VERSION "canboat-NMEA2000-curated"

NS_ :

BS_:

BU_: Vector__XXX
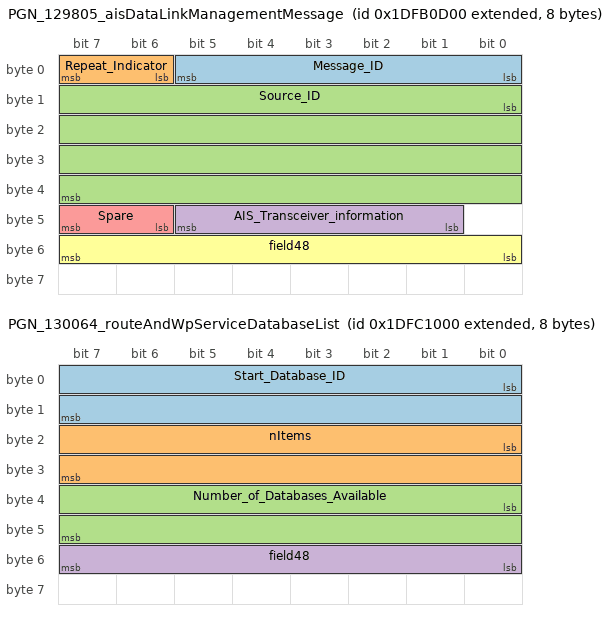
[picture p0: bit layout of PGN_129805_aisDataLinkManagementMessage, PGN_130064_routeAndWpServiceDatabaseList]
BO_ 2650475776 PGN_129805_aisDataLinkManagementMessage: 8 Vector__XXX
 SG_ Message_ID : 0|6@1+ (1.0,0) [0|63] "" Vector__XXX
 SG_ Repeat_Indicator : 6|2@1+ (1.0,0) [0|3] "" Vector__XXX
 SG_ Source_ID : 8|32@1+ (1.0,0) [2000000.0|999999999.0] "" Vector__XXX
 SG_ AIS_Transceiver_information : 41|5@1+ (1.0,0) [0|31] "" Vector__XXX
 SG_ Spare : 46|2@1+ (1.0,0) [0|3] "" Vector__XXX
 SG_ field48 : 48|8@1+ (1.0,0) [0|255] "" Vector__XXX

BO_ 2650476032 PGN_129806_aisChannelManagement: 31 Vector__XXX
 SG_ Message_ID : 0|6@1+ (1.0,0) [0|63] "" Vector__XXX
 SG_ Repeat_Indicator : 6|2@1+ (1.0,0) [0|3] "" Vector__XXX
 SG_ Source_ID : 8|32@1+ (1.0,0) [2000000.0|999999999.0] "" Vector__XXX
 SG_ AIS_Transceiver_information : 41|5@1+ (1.0,0) [0|31] "" Vector__XXX
 SG_ Spare : 46|2@1+ (1.0,0) [0|3] "" Vector__XXX
 SG_ Channel_A : 48|16@1+ (1.0,0) [0|65535] "" Vector__XXX
 SG_ Channel_B : 64|16@1+ (1.0,0) [0|65535] "" Vector__XXX
 SG_ Power : 83|1@1+ (1.0,0) [0|1] "" Vector__XXX
 SG_ Tx_Rx_Mode : 84|4@1+ (1.0,0) [0|15] "" Vector__XXX
 SG_ North_East_Longitude_Corner_1 : 88|32@1- (1e-07,0) [-180.0|180.0] "" Vector__XXX
 SG_ North_East_Latitude_Corner_1 : 120|32@1- (1e-07,0) [-90.0|90.0] "" Vector__XXX
 SG_ South_West_Longitude_Corner_2 : 152|32@1- (1e-07,0) [-180.0|180.0] "" Vector__XXX
 SG_ South_West_Latitude_Corner_2 : 184|32@1- (1e-07,0) [-90.0|90.0] "" Vector__XXX
 SG_ Addressed_or_Broadcast_Message_Indicator : 217|1@1+ (1.0,0) [0|1] "" Vector__XXX
 SG_ Channel_A_Bandwidth : 218|1@1+ (1.0,0) [0|1] "" Vector__XXX
 SG_ Channel_B_Bandwidth : 219|1@1+ (1.0,0) [0|1] "" Vector__XXX
 SG_ Transitional_Zone_Size : 221|3@1+ (1.0,0) [0|7] "" Vector__XXX
 SG_ Spare_1 : 224|23@1+ (1.0,0) [0|8388607] "" Vector__XXX

BO_ 2650476288 PGN_129807_aisClassBGroupAssignment: 29 Vector__XXX
 SG_ Message_ID : 0|6@1+ (1.0,0) [0|63] "" Vector__XXX
 SG_ Repeat_Indicator : 6|2@1+ (1.0,0) [0|3] "" Vector__XXX
 SG_ Source_ID : 8|32@1+ (1.0,0) [2000000.0|999999999.0] "" Vector__XXX
 SG_ Spare : 40|2@1+ (1.0,0) [0|3] "" Vector__XXX
 SG_ Tx_Rx_Mode : 42|4@1+ (1.0,0) [0|15] "" Vector__XXX
 SG_ North_East_Longitude_Corner_1 : 48|32@1- (1e-07,0) [-180.0|180.0] "" Vector__XXX
 SG_ North_East_Latitude_Corner_1 : 80|32@1- (1e-07,0) [-90.0|90.0] "" Vector__XXX
 SG_ South_West_Longitude_Corner_2 : 112|32@1- (1e-07,0) [-180.0|180.0] "" Vector__XXX
 SG_ South_West_Latitude_Corner_2 : 144|32@1- (1e-07,0) [-90.0|90.0] "" Vector__XXX
 SG_ Station_Type : 176|4@1+ (1.0,0) [0|15] "" Vector__XXX
 SG_ Ship_and_Cargo_Filter : 184|8@1+ (1.0,0) [0|255] "" Vector__XXX
 SG_ Spare_1 : 192|22@1+ (1.0,0) [0|4194303] "" Vector__XXX
 SG_ Reporting_Interval : 216|4@1+ (1.0,0) [0|15] "" Vector__XXX
 SG_ Quiet_Time : 220|4@1+ (60.0,0) [0.0|900.0] "" Vector__XXX
 SG_ Spare_2 : 224|6@1+ (1.0,0) [0|63] "" Vector__XXX

BO_ 2449149952 PGN_129808_dscCallInformation: 62 Vector__XXX
 SG_ DSC_Format_Symbol : 0|8@1+ (1.0,0) [0|255] "" Vector__XXX
 SG_ DSC_Category_Symbol : 8|8@1+ (1.0,0) [0|255] "" Vector__XXX
 SG_ DSC_Message_Address : 16|40@1+ (1.0,0) [0.0|9999999999.0] "" Vector__XXX
 SG_ _1st_Telecommand : 56|8@1+ (1.0,0) [0|255] "" Vector__XXX
 SG_ Subsequent_Communication_Mode_or_2nd_Telecommand : 64|8@1+ (1.0,0) [0|255] "" Vector__XXX
 SG_ Proposed_Rx_Frequency_Channel : 72|48@1+ (1.0,0) [0|281474976710655] "" Vector__XXX
 SG_ Proposed_Tx_Frequency_Channel : 120|48@1+ (1.0,0) [0|281474976710655] "" Vector__XXX
 SG_ Telephone_Number : 168|8@1+ (1.0,0) [0|255] "" Vector__XXX
 SG_ Latitude_of_Vessel_Reported : 176|32@1- (1e-07,0) [-90.0|90.0] "" Vector__XXX
 SG_ Longitude_of_Vessel_Reported : 208|32@1- (1e-07,0) [-180.0|180.0] "" Vector__XXX
 SG_ Time_of_Position : 240|32@1+ (0.0001,0) [0.0|86401.0] "" Vector__XXX
 SG_ MMSI_of_Ship_In_Distress : 272|40@1+ (1.0,0) [0.0|9999999999.0] "" Vector__XXX
 SG_ DSC_EOS_Symbol : 312|8@1+ (1.0,0) [0|255] "" Vector__XXX
 SG_ Expansion_Enabled : 320|2@1+ (1.0,0) [0|3] "" Vector__XXX
 SG_ Calling_Rx_Frequency_Channel : 328|48@1+ (1.0,0) [0|281474976710655] "" Vector__XXX
 SG_ Calling_Tx_Frequency_Channel : 376|48@1+ (1.0,0) [0|281474976710655] "" Vector__XXX
 SG_ Time_of_Receipt : 424|32@1+ (0.0001,0) [0.0|86401.0] "" Vector__XXX
 SG_ Date_of_Receipt : 456|16@1+ (1.0,0) [0|65535] "" Vector__XXX
 SG_ DSC_Equipment_Assigned_Message_ID : 472|16@1+ (1.0,0) [0|65535] "" Vector__XXX
 SG_ field488 : 488|8@1+ (1.0,0) [0|255] "" Vector__XXX

BO_ 2449149952 PGN_129808_dscDistressCallInformation: 62 Vector__XXX
 SG_ DSC_Format : 0|8@1+ (1.0,0) [0|255] "" Vector__XXX
 SG_ DSC_Category : 8|8@1+ (1.0,0) [0|255] "" Vector__XXX
 SG_ DSC_Message_Address : 16|40@1+ (1.0,0) [0.0|9999999999.0] "" Vector__XXX
 SG_ Nature_of_Distress : 56|8@1+ (1.0,0) [0|255] "" Vector__XXX
 SG_ Subsequent_Communication_Mode_or_2nd_Telecommand : 64|8@1+ (1.0,0) [0|255] "" Vector__XXX
 SG_ Proposed_Rx_Frequency_Channel : 72|48@1+ (1.0,0) [0|281474976710655] "" Vector__XXX
 SG_ Proposed_Tx_Frequency_Channel : 120|48@1+ (1.0,0) [0|281474976710655] "" Vector__XXX
 SG_ Telephone_Number : 168|8@1+ (1.0,0) [0|255] "" Vector__XXX
 SG_ Latitude_of_Vessel_Reported : 176|32@1- (1e-07,0) [-90.0|90.0] "" Vector__XXX
 SG_ Longitude_of_Vessel_Reported : 208|32@1- (1e-07,0) [-180.0|180.0] "" Vector__XXX
 SG_ Time_of_Position : 240|32@1+ (0.0001,0) [0.0|86401.0] "" Vector__XXX
 SG_ MMSI_of_Ship_In_Distress : 272|40@1+ (1.0,0) [0.0|9999999999.0] "" Vector__XXX
 SG_ DSC_EOS_Symbol : 312|8@1+ (1.0,0) [0|255] "" Vector__XXX
 SG_ Expansion_Enabled : 320|2@1+ (1.0,0) [0|3] "" Vector__XXX
 SG_ Calling_Rx_Frequency_Channel : 328|48@1+ (1.0,0) [0|281474976710655] "" Vector__XXX
 SG_ Calling_Tx_Frequency_Channel : 376|48@1+ (1.0,0) [0|281474976710655] "" Vector__XXX
 SG_ Time_of_Receipt : 424|32@1+ (0.0001,0) [0.0|86401.0] "" Vector__XXX
 SG_ Date_of_Receipt : 456|16@1+ (1.0,0) [0|65535] "" Vector__XXX
 SG_ DSC_Equipment_Assigned_Message_ID : 472|16@1+ (1.0,0) [0|65535] "" Vector__XXX
 SG_ field488 : 488|8@1+ (1.0,0) [0|255] "" Vector__XXX

BO_ 2583367936 PGN_129809_aisClassBStaticDataMsg24PartA: 27 Vector__XXX
 SG_ Message_ID : 0|6@1+ (1.0,0) [0|63] "" Vector__XXX
 SG_ Repeat_Indicator : 6|2@1+ (1.0,0) [0|3] "" Vector__XXX
 SG_ User_ID : 8|32@1+ (1.0,0) [2000000.0|999999999.0] "" Vector__XXX
 SG_ Name : 40|160@1+ (1.0,0) [0|1461501637330902918203684832716283019655932542975] "" Vector__XXX
 SG_ AIS_Transceiver_information : 200|5@1+ (1.0,0) [0|31] "" Vector__XXX
 SG_ Sequence_ID : 208|8@1+ (1.0,0) [0|255] "" Vector__XXX

BO_ 2583368192 PGN_129810_aisClassBStaticDataMsg24PartB: 35 Vector__XXX
 SG_ Message_ID : 0|6@1+ (1.0,0) [0|63] "" Vector__XXX
 SG_ Repeat_Indicator : 6|2@1+ (1.0,0) [0|3] "" Vector__XXX
 SG_ User_ID : 8|32@1+ (1.0,0) [2000000.0|999999999.0] "" Vector__XXX
 SG_ Type_of_ship : 40|8@1+ (1.0,0) [0|255] "" Vector__XXX
 SG_ Vendor_ID : 48|56@1+ (1.0,0) [0|72057594037927935] "" Vector__XXX
 SG_ Callsign : 104|56@1+ (1.0,0) [0|72057594037927935] "" Vector__XXX
 SG_ Length : 160|16@1+ (0.1,0) [0.0|6553.5] "" Vector__XXX
 SG_ Beam : 176|16@1+ (0.1,0) [0.0|6553.5] "" Vector__XXX
 SG_ Position_reference_from_Starboard : 192|16@1+ (0.1,0) [0.0|6553.5] "" Vector__XXX
 SG_ Position_reference_from_Bow : 208|16@1+ (0.1,0) [0.0|6553.5] "" Vector__XXX
 SG_ Mothership_User_ID : 224|32@1+ (1.0,0) [2000000.0|999999999.0] "" Vector__XXX
 SG_ Spare : 258|2@1+ (1.0,0) [0|3] "" Vector__XXX
 SG_ GNSS_type : 260|4@1+ (1.0,0) [0|15] "" Vector__XXX
 SG_ AIS_Transceiver_information : 264|5@1+ (1.0,0) [0|31] "" Vector__XXX
 SG_ Sequence_ID : 272|8@1+ (1.0,0) [0|255] "" Vector__XXX

BO_ 2583368448 PGN_129811_aisSingleSlotBinaryMessageDeprecated: 14 Vector__XXX
 SG_ Sequence_ID : 0|8@1+ (1.0,0) [0|255] "" Vector__XXX
 SG_ Message_ID : 8|6@1+ (1.0,0) [0|63] "" Vector__XXX
 SG_ Repeat_Indicator : 14|2@1+ (1.0,0) [0|3] "" Vector__XXX
 SG_ Source_ID : 16|32@1+ (1.0,0) [2000000.0|999999999.0] "" Vector__XXX
 SG_ Destination_Indicator : 48|1@1+ (1.0,0) [0|1] "" Vector__XXX
 SG_ Binary_data_flag : 49|1@1+ (1.0,0) [0|1] "" Vector__XXX
 SG_ Spare : 50|1@1+ (1.0,0) [0|1] "" Vector__XXX
 SG_ AIS_Transceiver_information : 51|5@1+ (1.0,0) [0|31] "" Vector__XXX
 SG_ Destination_ID : 56|32@1+ (1.0,0) [2000000.0|999999999.0] "" Vector__XXX
 SG_ Number_of_bits_in_Binary_Data_Field : 88|16@1+ (1.0,0) [0|65535] "" Vector__XXX
 SG_ Binary_Data : 104|8@1+ (1.0,0) [0|255] "" Vector__XXX

BO_ 2583368704 PGN_129812_aisMultiSlotBinaryMessageDeprecated: 16 Vector__XXX
 SG_ Sequence_ID : 0|8@1+ (1.0,0) [0|255] "" Vector__XXX
 SG_ Message_ID : 8|6@1+ (1.0,0) [0|63] "" Vector__XXX
 SG_ Repeat_Indicator : 14|2@1+ (1.0,0) [0|3] "" Vector__XXX
 SG_ Source_ID : 16|32@1+ (1.0,0) [2000000.0|999999999.0] "" Vector__XXX
 SG_ Destination_Indicator : 48|1@1+ (1.0,0) [0|1] "" Vector__XXX
 SG_ Binary_data_flag : 49|1@1+ (1.0,0) [0|1] "" Vector__XXX
 SG_ AIS_Transceiver_information : 52|5@1+ (1.0,0) [0|31] "" Vector__XXX
 SG_ Destination_ID : 57|32@1+ (1.0,0) [2000000.0|999999999.0] "" Vector__XXX
 SG_ Spare : 89|3@1+ (1.0,0) [0|7] "" Vector__XXX
 SG_ Communication_state_selector_flag : 92|1@1+ (1.0,0) [0|1] "" Vector__XXX
 SG_ Communication_State : 93|19@1+ (1.0,0) [0|524287] "" Vector__XXX
 SG_ Spare_1 : 112|3@1+ (1.0,0) [0|7] "" Vector__XXX
 SG_ field120 : 120|8@1+ (1.0,0) [0|255] "" Vector__XXX

BO_ 2583368960 PGN_129813_aisLongRangeBroadcastMessage: 20 Vector__XXX
 SG_ Sequence_ID : 0|8@1+ (1.0,0) [0|255] "" Vector__XXX
 SG_ Message_ID : 8|6@1+ (1.0,0) [0|63] "" Vector__XXX
 SG_ Repeat_Indicator : 14|2@1+ (1.0,0) [0|3] "" Vector__XXX
 SG_ User_ID : 16|32@1+ (1.0,0) [2000000.0|999999999.0] "" Vector__XXX
 SG_ Longitude : 48|32@1- (1e-07,0) [-180.0|180.0] "" Vector__XXX
 SG_ Latitude : 80|32@1- (1e-07,0) [-90.0|90.0] "" Vector__XXX
 SG_ Position_Accuracy : 112|1@1+ (1.0,0) [0|1] "" Vector__XXX
 SG_ RAIM : 113|1@1+ (1.0,0) [0|1] "" Vector__XXX
 SG_ Nav_Status : 114|4@1+ (1.0,0) [0|15] "" Vector__XXX
 SG_ Position_Latency : 118|1@1+ (1.0,0) [0|1] "" Vector__XXX
 SG_ Spare : 119|1@1+ (1.0,0) [0|1] "" Vector__XXX
 SG_ SOG : 120|16@1+ (0.01,0) [0.0|655.35] "" Vector__XXX
 SG_ COG : 136|16@1+ (0.0001,0) [0.0|6.5535000000000005] "" Vector__XXX
 SG_ AIS_Transceiver_information : 152|5@1+ (1.0,0) [0|31] "" Vector__XXX

BO_ 2583369216 PGN_129814_aisSingleSlotBinaryMessage: 15 Vector__XXX
 SG_ Sequence_ID : 0|8@1+ (1.0,0) [0|255] "" Vector__XXX
 SG_ Message_ID : 8|6@1+ (1.0,0) [0|63] "" Vector__XXX
 SG_ Repeat_Indicator : 14|2@1+ (1.0,0) [0|3] "" Vector__XXX
 SG_ Source_ID : 16|32@1+ (1.0,0) [2000000.0|999999999.0] "" Vector__XXX
 SG_ Destination_Indicator : 48|1@1+ (1.0,0) [0|1] "" Vector__XXX
 SG_ Binary_data_flag : 49|1@1+ (1.0,0) [0|1] "" Vector__XXX
 SG_ Spare : 50|1@1+ (1.0,0) [0|1] "" Vector__XXX
 SG_ AIS_Transceiver_information : 59|5@1+ (1.0,0) [0|31] "" Vector__XXX
 SG_ Destination_ID : 64|32@1+ (1.0,0) [2000000.0|999999999.0] "" Vector__XXX
 SG_ Number_of_bits_in_Binary_Data_Field : 96|16@1+ (1.0,0) [0|65535] "" Vector__XXX
 SG_ Binary_Data : 112|8@1+ (1.0,0) [0|255] "" Vector__XXX

BO_ 2583369472 PGN_129815_aisMultiSlotBinaryMessage: 18 Vector__XXX
 SG_ Sequence_ID : 0|8@1+ (1.0,0) [0|255] "" Vector__XXX
 SG_ Message_ID : 8|6@1+ (1.0,0) [0|63] "" Vector__XXX
 SG_ Repeat_Indicator : 14|2@1+ (1.0,0) [0|3] "" Vector__XXX
 SG_ Source_ID : 16|32@1+ (1.0,0) [2000000.0|999999999.0] "" Vector__XXX
 SG_ Destination_Indicator : 48|1@1+ (1.0,0) [0|1] "" Vector__XXX
 SG_ Binary_data_flag : 49|1@1+ (1.0,0) [0|1] "" Vector__XXX
 SG_ Destination_ID : 52|32@1+ (1.0,0) [2000000.0|999999999.0] "" Vector__XXX
 SG_ Spare : 84|3@1+ (1.0,0) [0|7] "" Vector__XXX
 SG_ Communication_state_selector_flag : 87|1@1+ (1.0,0) [0|1] "" Vector__XXX
 SG_ Communication_State : 88|19@1+ (1.0,0) [0|524287] "" Vector__XXX
 SG_ Spare_1 : 107|3@1+ (1.0,0) [0|7] "" Vector__XXX
 SG_ AIS_Transceiver_information : 110|5@1+ (1.0,0) [0|31] "" Vector__XXX
 SG_ Number_of_Bits_in_Binary_Data_Field : 120|16@1+ (1.0,0) [0|65535] "" Vector__XXX
 SG_ Binary_Data : 136|8@1+ (1.0,0) [0|255] "" Vector__XXX

BO_ 2583369728 PGN_129816_aisAcknowledgeBinary: 9 Vector__XXX
 SG_ Sequence_ID : 0|8@1+ (1.0,0) [0|255] "" Vector__XXX
 SG_ Message_ID : 8|6@1+ (1.0,0) [0|63] "" Vector__XXX
 SG_ Repeat_Indicator : 14|2@1+ (1.0,0) [0|3] "" Vector__XXX
 SG_ Source_ID : 16|32@1+ (1.0,0) [2000000.0|999999999.0] "" Vector__XXX
 SG_ AIS_Transceiver_information : 50|5@1+ (1.0,0) [0|31] "" Vector__XXX
 SG_ Spare : 55|1@1+ (1.0,0) [0|1] "" Vector__XXX
 SG_ Number_of_Acknowledgments : 56|8@1+ (1.0,0) [0|255] "" Vector__XXX
 SG_ field64 : 64|8@1+ (1.0,0) [0|255] "" Vector__XXX

BO_ 2382103552 PGN_130052_loranCTdData: 32 Vector__XXX
 SG_ Group_Repetition_Interval__GRI_ : 0|32@1- (1e-09,0) [-2.147483648|2.147483647] "" Vector__XXX
 SG_ Master_Range : 32|32@1- (1e-09,0) [-2.147483648|2.147483647] "" Vector__XXX
 SG_ V_Secondary_TD : 64|32@1- (1e-09,0) [-2.147483648|2.147483647] "" Vector__XXX
 SG_ W_Secondary_TD : 96|32@1- (1e-09,0) [-2.147483648|2.147483647] "" Vector__XXX
 SG_ X_Secondary_TD : 128|32@1- (1e-09,0) [-2.147483648|2.147483647] "" Vector__XXX
 SG_ Y_Secondary_TD : 160|32@1- (1e-09,0) [-2.147483648|2.147483647] "" Vector__XXX
 SG_ Z_Secondary_TD : 192|32@1- (1e-09,0) [-2.147483648|2.147483647] "" Vector__XXX
 SG_ Station_status__Master : 224|4@1+ (1.0,0) [0|15] "" Vector__XXX
 SG_ Station_status__V : 228|4@1+ (1.0,0) [0|15] "" Vector__XXX
 SG_ Station_status__W : 232|4@1+ (1.0,0) [0|15] "" Vector__XXX
 SG_ Station_status__X : 236|4@1+ (1.0,0) [0|15] "" Vector__XXX
 SG_ Station_status__Y : 240|4@1+ (1.0,0) [0|15] "" Vector__XXX
 SG_ Station_status__Z : 244|4@1+ (1.0,0) [0|15] "" Vector__XXX
 SG_ Mode : 248|4@1+ (1.0,0) [0|15] "" Vector__XXX

BO_ 2382103808 PGN_130053_loranCRangeData: 32 Vector__XXX
 SG_ Group_Repetition_Interval__GRI_ : 0|32@1- (1e-09,0) [-2.147483648|2.147483647] "" Vector__XXX
 SG_ Master_Range : 32|32@1- (1e-09,0) [-2.147483648|2.147483647] "" Vector__XXX
 SG_ V_Secondary_Range : 64|32@1- (1e-09,0) [-2.147483648|2.147483647] "" Vector__XXX
 SG_ W_Secondary_Range : 96|32@1- (1e-09,0) [-2.147483648|2.147483647] "" Vector__XXX
 SG_ X_Secondary_Range : 128|32@1- (1e-09,0) [-2.147483648|2.147483647] "" Vector__XXX
 SG_ Y_Secondary_Range : 160|32@1- (1e-09,0) [-2.147483648|2.147483647] "" Vector__XXX
 SG_ Z_Secondary_Range : 192|32@1- (1e-09,0) [-2.147483648|2.147483647] "" Vector__XXX
 SG_ Station_status__Master : 224|4@1+ (1.0,0) [0|15] "" Vector__XXX
 SG_ Station_status__V : 228|4@1+ (1.0,0) [0|15] "" Vector__XXX
 SG_ Station_status__W : 232|4@1+ (1.0,0) [0|15] "" Vector__XXX
 SG_ Station_status__X : 236|4@1+ (1.0,0) [0|15] "" Vector__XXX
 SG_ Station_status__Y : 240|4@1+ (1.0,0) [0|15] "" Vector__XXX
 SG_ Station_status__Z : 244|4@1+ (1.0,0) [0|15] "" Vector__XXX
 SG_ Mode : 248|4@1+ (1.0,0) [0|15] "" Vector__XXX

BO_ 2382104064 PGN_130054_loranCSignalData: 15 Vector__XXX
 SG_ Group_Repetition_Interval__GRI_ : 0|32@1- (1e-09,0) [-2.147483648|2.147483647] "" Vector__XXX
 SG_ Station_identifier : 32|8@1+ (1.0,0) [0|255] "" Vector__XXX
 SG_ Station_SNR : 40|16@1- (0.01,0) [-327.68|327.67] "" Vector__XXX
 SG_ Station_ECD : 56|32@1- (1e-09,0) [-2.147483648|2.147483647] "" Vector__XXX
 SG_ Station_ASF : 88|32@1- (1e-09,0) [-2.147483648|2.147483647] "" Vector__XXX

BO_ 2583432192 PGN_130060_label: 10 Vector__XXX
 SG_ Hardware_Channel_ID : 0|8@1+ (1.0,0) [0|255] "" Vector__XXX
 SG_ PGN : 8|24@1+ (1.0,0) [0.0|262143.0] "" Vector__XXX
 SG_ Data_Source_Instance_Field_Number : 32|8@1+ (1.0,0) [0|255] "" Vector__XXX
 SG_ Data_Source_Instance_Value : 40|8@1+ (1.0,0) [0|255] "" Vector__XXX
 SG_ Secondary_Enumeration_Field_Number : 48|8@1+ (1.0,0) [0|255] "" Vector__XXX
 SG_ Secondary_Enumeration_Field_Value : 56|8@1+ (1.0,0) [0|255] "" Vector__XXX
 SG_ Parameter_Field_Number : 64|8@1+ (1.0,0) [0|255] "" Vector__XXX
 SG_ Label : 72|8@1+ (1.0,0) [0|255] "" Vector__XXX

BO_ 2583432448 PGN_130061_channelSourceConfiguration: 19 Vector__XXX
 SG_ Data_Source_Channel_ID : 0|8@1+ (1.0,0) [0|255] "" Vector__XXX
 SG_ Source_Selection_Status : 8|2@1+ (1.0,0) [0|3] "" Vector__XXX
 SG_ NAME_Selection_Criteria_Mask : 12|12@1+ (1.0,0) [0|4095] "" Vector__XXX
 SG_ Source_NAME : 24|64@1+ (1.0,0) [0|18446744073709551615] "" Vector__XXX
 SG_ PGN : 88|24@1+ (1.0,0) [0.0|262143.0] "" Vector__XXX
 SG_ Data_Source_Instance_Field_Number : 112|8@1+ (1.0,0) [0|255] "" Vector__XXX
 SG_ Data_Source_Instance_Value : 120|8@1+ (1.0,0) [0|255] "" Vector__XXX
 SG_ Secondary_Enumeration_Field_Number : 128|8@1+ (1.0,0) [0|255] "" Vector__XXX
 SG_ Secondary_Enumeration_Field_Value : 136|8@1+ (1.0,0) [0|255] "" Vector__XXX
 SG_ Parameter_Field_Number : 144|8@1+ (1.0,0) [0|255] "" Vector__XXX

BO_ 2650542080 PGN_130064_routeAndWpServiceDatabaseList: 8 Vector__XXX
 SG_ Start_Database_ID : 0|16@1+ (1.0,0) [0|65535] "" Vector__XXX
 SG_ nItems : 16|16@1+ (1.0,0) [0|65535] "" Vector__XXX
 SG_ Number_of_Databases_Available : 32|16@1+ (1.0,0) [0|65535] "" Vector__XXX
 SG_ field48 : 48|8@1+ (1.0,0) [0|255] "" Vector__XXX

BO_ 2650542336 PGN_130065_routeAndWpServiceRouteList: 9 Vector__XXX
 SG_ Start_Route_ID : 0|16@1+ (1.0,0) [0|65535] "" Vector__XXX
 SG_ nItems : 16|16@1+ (1.0,0) [0|65535] "" Vector__XXX
 SG_ Number_of_Routes_in_Database : 32|16@1+ (1.0,0) [0|65535] "" Vector__XXX
 SG_ Database_ID : 48|16@1+ (1.0,0) [0|65535] "" Vector__XXX
 SG_ field64 : 64|8@1+ (1.0,0) [0|255] "" Vector__XXX

BO_ 2650542592 PGN_130066_routeAndWpServiceRouteWpListAttributes: 18 Vector__XXX
 SG_ Database_ID : 0|16@1+ (1.0,0) [0|65535] "" Vector__XXX
 SG_ Route_ID : 16|16@1+ (1.0,0) [0|65535] "" Vector__XXX
 SG_ Route_WP_List_Name : 32|8@1+ (1.0,0) [0|255] "" Vector__XXX
 SG_ Route_WP_List_Timestamp : 40|32@1+ (0.0001,0) [0.0|86401.0] "" Vector__XXX
 SG_ Route_WP_List_Datestamp : 72|16@1+ (1.0,0) [0|65535] "" Vector__XXX
 SG_ Change_at_Last_Timestamp : 88|8@1+ (1.0,0) [0|255] "" Vector__XXX
 SG_ Number_of_WPs_in_the_Route_WP_List : 96|16@1+ (1.0,0) [0|65535] "" Vector__XXX
 SG_ Critical_supplementary_parameters : 112|8@1+ (1.0,0) [0|255] "" Vector__XXX
 SG_ Navigation_Method : 120|2@1+ (1.0,0) [0|3] "" Vector__XXX
 SG_ WP_Identification_Method : 122|2@1+ (1.0,0) [0|3] "" Vector__XXX
 SG_ Route_Status : 124|4@1+ (1.0,0) [0|15] "" Vector__XXX
 SG_ XTE_Limit_for_the_Route : 128|16@1- (1.0,0) [-32768|32767] "" Vector__XXX

BO_ 2650542848 PGN_130067_routeAndWpServiceRouteWpNamePosition: 11 Vector__XXX
 SG_ Start_RPS_ : 0|16@1+ (1.0,0) [0|65535] "" Vector__XXX
 SG_ nItems : 16|16@1+ (1.0,0) [0|65535] "" Vector__XXX
 SG_ Number_of_WPs_in_the_Route_WP_List : 32|16@1+ (1.0,0) [0|65535] "" Vector__XXX
 SG_ Database_ID : 48|16@1+ (1.0,0) [0|65535] "" Vector__XXX
 SG_ Route_ID : 64|16@1+ (1.0,0) [0|65535] "" Vector__XXX
 SG_ field80 : 80|8@1+ (1.0,0) [0|255] "" Vector__XXX

BO_ 2650543104 PGN_130068_routeAndWpServiceRouteWpName: 11 Vector__XXX
 SG_ Start_RPS_ : 0|16@1+ (1.0,0) [0|65535] "" Vector__XXX
 SG_ nItems : 16|16@1+ (1.0,0) [0|65535] "" Vector__XXX
 SG_ Number_of_WPs_in_the_Route_WP_List : 32|16@1+ (1.0,0) [0|65535] "" Vector__XXX
 SG_ Database_ID : 48|16@1+ (1.0,0) [0|65535] "" Vector__XXX
 SG_ Route_ID : 64|16@1+ (1.0,0) [0|65535] "" Vector__XXX
 SG_ field80 : 80|8@1+ (1.0,0) [0|255] "" Vector__XXX

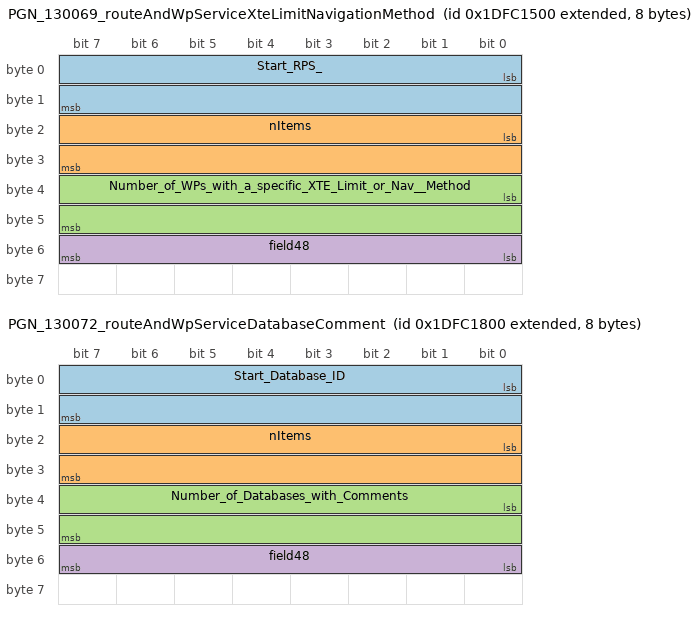
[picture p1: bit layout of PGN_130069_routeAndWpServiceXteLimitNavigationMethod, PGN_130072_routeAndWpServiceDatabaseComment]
BO_ 2650543360 PGN_130069_routeAndWpServiceXteLimitNavigationMethod: 8 Vector__XXX
 SG_ Start_RPS_ : 0|16@1+ (1.0,0) [0|65535] "" Vector__XXX
 SG_ nItems : 16|16@1+ (1.0,0) [0|65535] "" Vector__XXX
 SG_ Number_of_WPs_with_a_specific_XTE_Limit_or_Nav__Method : 32|16@1+ (1.0,0) [0|65535] "" Vector__XXX
 SG_ field48 : 48|8@1+ (1.0,0) [0|255] "" Vector__XXX

BO_ 2650543616 PGN_130070_routeAndWpServiceWpComment: 11 Vector__XXX
 SG_ Start_ID : 0|16@1+ (1.0,0) [0|65535] "" Vector__XXX
 SG_ nItems : 16|16@1+ (1.0,0) [0|65535] "" Vector__XXX
 SG_ Number_of_WPs_with_Comments : 32|16@1+ (1.0,0) [0|65535] "" Vector__XXX
 SG_ Database_ID : 48|16@1+ (1.0,0) [0|65535] "" Vector__XXX
 SG_ Route_ID : 64|16@1+ (1.0,0) [0|65535] "" Vector__XXX
 SG_ field80 : 80|8@1+ (1.0,0) [0|255] "" Vector__XXX

BO_ 2650543872 PGN_130071_routeAndWpServiceRouteComment: 9 Vector__XXX
 SG_ Start_Route_ID : 0|16@1+ (1.0,0) [0|65535] "" Vector__XXX
 SG_ nItems : 16|16@1+ (1.0,0) [0|65535] "" Vector__XXX
 SG_ Number_of_Routes_with_Comments : 32|16@1+ (1.0,0) [0|65535] "" Vector__XXX
 SG_ Database_ID : 48|16@1+ (1.0,0) [0|65535] "" Vector__XXX
 SG_ field64 : 64|8@1+ (1.0,0) [0|255] "" Vector__XXX

BO_ 2650544128 PGN_130072_routeAndWpServiceDatabaseComment: 8 Vector__XXX
 SG_ Start_Database_ID : 0|16@1+ (1.0,0) [0|65535] "" Vector__XXX
 SG_ nItems : 16|16@1+ (1.0,0) [0|65535] "" Vector__XXX
 SG_ Number_of_Databases_with_Comments : 32|16@1+ (1.0,0) [0|65535] "" Vector__XXX
 SG_ field48 : 48|8@1+ (1.0,0) [0|255] "" Vector__XXX

BO_ 2650544384 PGN_130073_routeAndWpServiceRadiusOfTurn: 11 Vector__XXX
 SG_ Start_RPS_ : 0|16@1+ (1.0,0) [0|65535] "" Vector__XXX
 SG_ nItems : 16|16@1+ (1.0,0) [0|65535] "" Vector__XXX
 SG_ Number_of_WPs_with_a_specific_Radius_of_Turn : 32|16@1+ (1.0,0) [0|65535] "" Vector__XXX
 SG_ Database_ID : 48|16@1+ (1.0,0) [0|65535] "" Vector__XXX
 SG_ Route_ID : 64|16@1+ (1.0,0) [0|65535] "" Vector__XXX
 SG_ field80 : 80|8@1+ (1.0,0) [0|255] "" Vector__XXX

BO_ 2650544640 PGN_130074_routeAndWpServiceWpListWpNamePosition: 11 Vector__XXX
 SG_ Start_WP_ID : 0|16@1+ (1.0,0) [0|65535] "" Vector__XXX
 SG_ nItems : 16|16@1+ (1.0,0) [0|65535] "" Vector__XXX
 SG_ Number_of_valid_WPs_in_the_WP_List : 32|16@1+ (1.0,0) [0|65535] "" Vector__XXX
 SG_ Database_ID : 48|16@1+ (1.0,0) [0|65535] "" Vector__XXX
 SG_ field80 : 80|8@1+ (1.0,0) [0|255] "" Vector__XXX

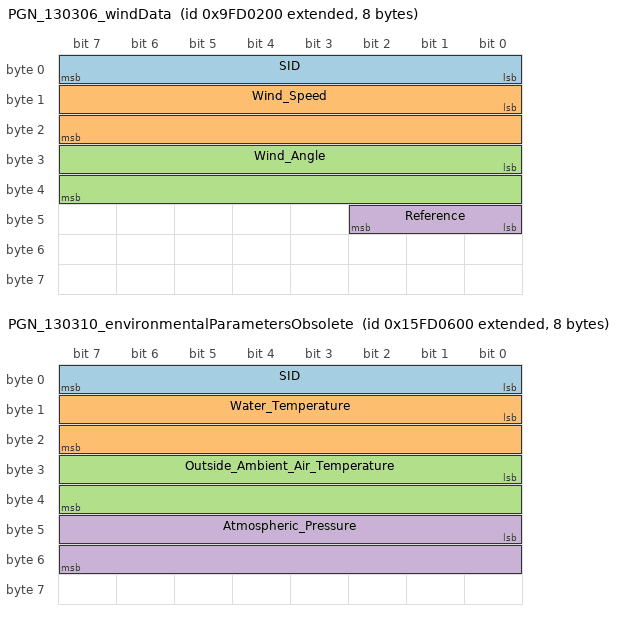
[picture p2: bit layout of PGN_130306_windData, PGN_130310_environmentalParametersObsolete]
BO_ 2315059712 PGN_130306_windData: 8 Vector__XXX
 SG_ SID : 0|8@1+ (1.0,0) [0|255] "" Vector__XXX
 SG_ Wind_Speed : 8|16@1+ (0.01,0) [0.0|655.35] "" Vector__XXX
 SG_ Wind_Angle : 24|16@1+ (0.0001,0) [0.0|6.5535000000000005] "" Vector__XXX
 SG_ Reference : 40|3@1+ (1.0,0) [0|7] "" Vector__XXX

BO_ 2516387328 PGN_130310_environmentalParametersObsolete: 8 Vector__XXX
 SG_ SID : 0|8@1+ (1.0,0) [0|255] "" Vector__XXX
 SG_ Water_Temperature : 8|16@1+ (0.01,0) [0.0|655.35] "" Vector__XXX
 SG_ Outside_Ambient_Air_Temperature : 24|16@1+ (0.01,0) [0.0|655.35] "" Vector__XXX
 SG_ Atmospheric_Pressure : 40|16@1+ (100.0,0) [0.0|6553500.0] "" Vector__XXX

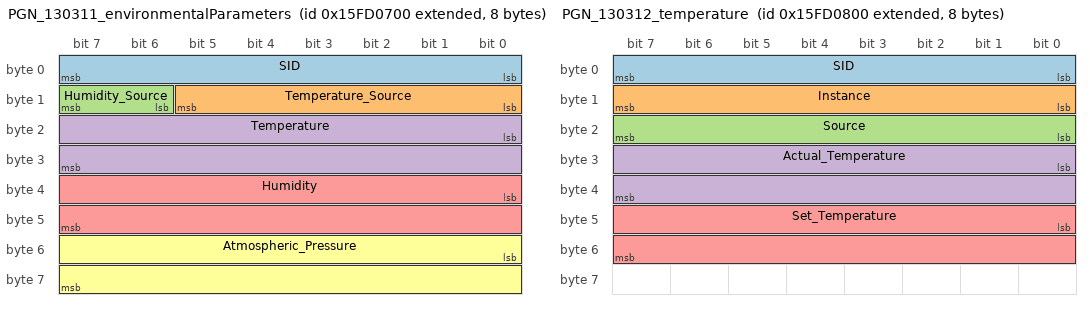
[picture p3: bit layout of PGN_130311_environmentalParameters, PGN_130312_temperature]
BO_ 2516387584 PGN_130311_environmentalParameters: 8 Vector__XXX
 SG_ SID : 0|8@1+ (1.0,0) [0|255] "" Vector__XXX
 SG_ Temperature_Source : 8|6@1+ (1.0,0) [0|63] "" Vector__XXX
 SG_ Humidity_Source : 14|2@1+ (1.0,0) [0|3] "" Vector__XXX
 SG_ Temperature : 16|16@1+ (0.01,0) [0.0|655.35] "" Vector__XXX
 SG_ Humidity : 32|16@1- (0.004,0) [-131.072|131.068] "%" Vector__XXX
 SG_ Atmospheric_Pressure : 48|16@1+ (100.0,0) [0.0|6553500.0] "" Vector__XXX

BO_ 2516387840 PGN_130312_temperature: 8 Vector__XXX
 SG_ SID : 0|8@1+ (1.0,0) [0|255] "" Vector__XXX
 SG_ Instance : 8|8@1+ (1.0,0) [0|255] "" Vector__XXX
 SG_ Source : 16|8@1+ (1.0,0) [0|255] "" Vector__XXX
 SG_ Actual_Temperature : 24|16@1+ (0.01,0) [0.0|655.35] "" Vector__XXX
 SG_ Set_Temperature : 40|16@1+ (0.01,0) [0.0|655.35] "" Vector__XXX

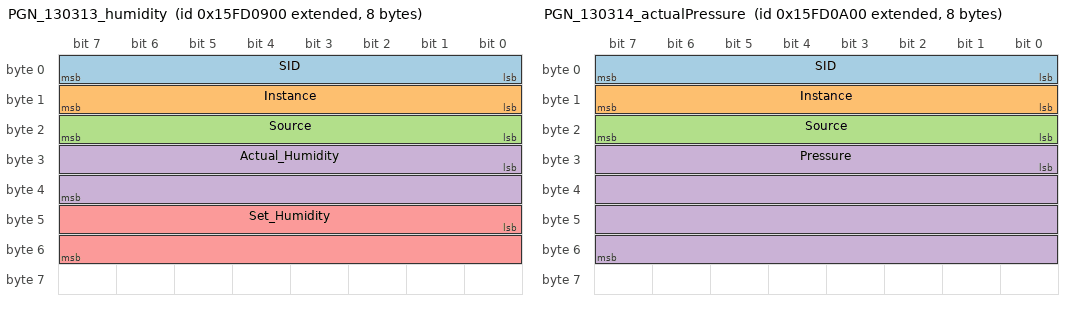
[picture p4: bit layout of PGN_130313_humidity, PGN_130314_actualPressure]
BO_ 2516388096 PGN_130313_humidity: 8 Vector__XXX
 SG_ SID : 0|8@1+ (1.0,0) [0|255] "" Vector__XXX
 SG_ Instance : 8|8@1+ (1.0,0) [0|255] "" Vector__XXX
 SG_ Source : 16|8@1+ (1.0,0) [0|255] "" Vector__XXX
 SG_ Actual_Humidity : 24|16@1- (0.004,0) [-131.072|131.068] "%" Vector__XXX
 SG_ Set_Humidity : 40|16@1- (0.004,0) [-131.072|131.068] "%" Vector__XXX

BO_ 2516388352 PGN_130314_actualPressure: 8 Vector__XXX
 SG_ SID : 0|8@1+ (1.0,0) [0|255] "" Vector__XXX
 SG_ Instance : 8|8@1+ (1.0,0) [0|255] "" Vector__XXX
 SG_ Source : 16|8@1+ (1.0,0) [0|255] "" Vector__XXX
 SG_ Pressure : 24|32@1- (0.1,0) [-214748364.8|214748364.70000002] "" Vector__XXX

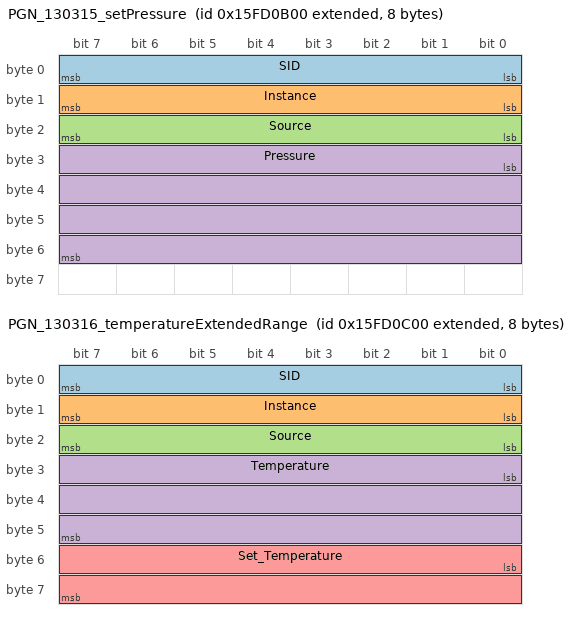
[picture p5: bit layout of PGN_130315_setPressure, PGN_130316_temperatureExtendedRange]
BO_ 2516388608 PGN_130315_setPressure: 8 Vector__XXX
 SG_ SID : 0|8@1+ (1.0,0) [0|255] "" Vector__XXX
 SG_ Instance : 8|8@1+ (1.0,0) [0|255] "" Vector__XXX
 SG_ Source : 16|8@1+ (1.0,0) [0|255] "" Vector__XXX
 SG_ Pressure : 24|32@1- (0.1,0) [-214748364.8|214748364.70000002] "" Vector__XXX

BO_ 2516388864 PGN_130316_temperatureExtendedRange: 8 Vector__XXX
 SG_ SID : 0|8@1+ (1.0,0) [0|255] "" Vector__XXX
 SG_ Instance : 8|8@1+ (1.0,0) [0|255] "" Vector__XXX
 SG_ Source : 16|8@1+ (1.0,0) [0|255] "" Vector__XXX
 SG_ Temperature : 24|24@1+ (0.001,0) [0.0|16777.215] "" Vector__XXX
 SG_ Set_Temperature : 48|16@1+ (0.1,0) [0.0|6553.5] "" Vector__XXX

BO_ 2583498752 PGN_130320_tideStationData: 21 Vector__XXX
 SG_ Mode : 0|4@1+ (1.0,0) [0|15] "" Vector__XXX
 SG_ Tide_Tendency : 4|2@1+ (1.0,0) [0|3] "" Vector__XXX
 SG_ Measurement_Date : 8|16@1+ (1.0,0) [0|65535] "" Vector__XXX
 SG_ Measurement_Time : 24|32@1+ (0.0001,0) [0.0|86401.0] "" Vector__XXX
 SG_ Station_Latitude : 56|32@1- (1e-07,0) [-90.0|90.0] "" Vector__XXX
 SG_ Station_Longitude : 88|32@1- (1e-07,0) [-180.0|180.0] "" Vector__XXX
 SG_ Tide_Level : 120|16@1- (0.001,0) [-32.768|32.767] "" Vector__XXX
 SG_ Tide_Level_standard_deviation : 136|16@1+ (0.01,0) [0.0|655.35] "" Vector__XXX
 SG_ Station_ID : 152|8@1+ (1.0,0) [0|255] "" Vector__XXX
 SG_ Station_Name : 160|8@1+ (1.0,0) [0|255] "" Vector__XXX

BO_ 2583499008 PGN_130321_salinityStationData: 23 Vector__XXX
 SG_ Mode : 0|4@1+ (1.0,0) [0|15] "" Vector__XXX
 SG_ Measurement_Date : 8|16@1+ (1.0,0) [0|65535] "" Vector__XXX
 SG_ Measurement_Time : 24|32@1+ (0.0001,0) [0.0|86401.0] "" Vector__XXX
 SG_ Station_Latitude : 56|32@1- (1e-07,0) [-90.0|90.0] "" Vector__XXX
 SG_ Station_Longitude : 88|32@1- (1e-07,0) [-180.0|180.0] "" Vector__XXX
 SG_ Salinity : 120|32@1- (1.0,0) [-3.40282346638529e+38|3.40282346638529e+38] "ppt" Vector__XXX
 SG_ Water_Temperature : 152|16@1+ (0.01,0) [0.0|655.35] "" Vector__XXX
 SG_ Station_ID : 168|8@1+ (1.0,0) [0|255] "" Vector__XXX
 SG_ Station_Name : 176|8@1+ (1.0,0) [0|255] "" Vector__XXX

BO_ 2583499264 PGN_130322_currentStationData: 27 Vector__XXX
 SG_ Mode : 0|4@1+ (1.0,0) [0|15] "" Vector__XXX
 SG_ State : 4|3@1+ (1.0,0) [0|7] "" Vector__XXX
 SG_ Measurement_Date : 8|16@1+ (1.0,0) [0|65535] "" Vector__XXX
 SG_ Measurement_Time : 24|32@1+ (0.0001,0) [0.0|86401.0] "" Vector__XXX
 SG_ Station_Latitude : 56|32@1- (1e-07,0) [-90.0|90.0] "" Vector__XXX
 SG_ Station_Longitude : 88|32@1- (1e-07,0) [-180.0|180.0] "" Vector__XXX
 SG_ Measurement_Depth : 120|32@1+ (0.01,0) [0.0|42949672.95] "" Vector__XXX
 SG_ Current_speed : 152|16@1+ (0.01,0) [0.0|655.35] "" Vector__XXX
 SG_ Current_flow_direction : 168|16@1+ (0.0001,0) [0.0|6.5535000000000005] "" Vector__XXX
 SG_ Water_Temperature : 184|16@1+ (0.01,0) [0.0|655.35] "" Vector__XXX
 SG_ Station_ID : 200|8@1+ (1.0,0) [0|255] "" Vector__XXX
 SG_ Station_Name : 208|8@1+ (1.0,0) [0|255] "" Vector__XXX

BO_ 2583499520 PGN_130323_meteorologicalStationData: 28 Vector__XXX
 SG_ Mode : 0|4@1+ (1.0,0) [0|15] "" Vector__XXX
 SG_ Measurement_Date : 8|16@1+ (1.0,0) [0|65535] "" Vector__XXX
 SG_ Measurement_Time : 24|32@1+ (0.0001,0) [0.0|86401.0] "" Vector__XXX
 SG_ Station_Latitude : 56|32@1- (1e-07,0) [-90.0|90.0] "" Vector__XXX
 SG_ Station_Longitude : 88|32@1- (1e-07,0) [-180.0|180.0] "" Vector__XXX
 SG_ Wind_Speed : 120|16@1+ (0.01,0) [0.0|655.35] "" Vector__XXX
 SG_ Wind_Direction : 136|16@1+ (0.0001,0) [0.0|6.5535000000000005] "" Vector__XXX
 SG_ Wind_Reference : 152|3@1+ (1.0,0) [0|7] "" Vector__XXX
 SG_ Wind_Gusts : 160|16@1+ (0.01,0) [0.0|655.35] "" Vector__XXX
 SG_ Atmospheric_Pressure : 176|16@1+ (100.0,0) [0.0|6553500.0] "" Vector__XXX
 SG_ Ambient_Temperature : 192|16@1+ (0.01,0) [0.0|655.35] "" Vector__XXX
 SG_ Station_ID : 208|8@1+ (1.0,0) [0|255] "" Vector__XXX
 SG_ Station_Name : 216|8@1+ (1.0,0) [0|255] "" Vector__XXX

BO_ 2583499776 PGN_130324_mooredBuoyStationData: 35 Vector__XXX
 SG_ Mode : 0|4@1+ (1.0,0) [0|15] "" Vector__XXX
 SG_ Measurement_Date : 8|16@1+ (1.0,0) [0|65535] "" Vector__XXX
 SG_ Measurement_Time : 24|32@1+ (0.0001,0) [0.0|86401.0] "" Vector__XXX
 SG_ Station_Latitude : 56|32@1- (1e-07,0) [-90.0|90.0] "" Vector__XXX
 SG_ Station_Longitude : 88|32@1- (1e-07,0) [-180.0|180.0] "" Vector__XXX
 SG_ Wind_Speed : 120|16@1+ (0.01,0) [0.0|655.35] "" Vector__XXX
 SG_ Wind_Direction : 136|16@1+ (0.0001,0) [0.0|6.5535000000000005] "" Vector__XXX
 SG_ Wind_Reference : 152|3@1+ (1.0,0) [0|7] "" Vector__XXX
 SG_ Wind_Gusts : 160|16@1+ (0.01,0) [0.0|655.35] "" Vector__XXX
 SG_ Wave_Height : 176|16@1+ (0.01,0) [0.0|655.35] "" Vector__XXX
 SG_ Dominant_Wave_Period : 192|16@1+ (0.01,0) [0.0|655.35] "" Vector__XXX
 SG_ Atmospheric_Pressure : 208|16@1+ (100.0,0) [0.0|6553500.0] "" Vector__XXX
 SG_ Pressure_Tendency_Rate : 224|16@1- (10.0,0) [-327680.0|327670.0] "" Vector__XXX
 SG_ Air_Temperature : 240|16@1+ (0.01,0) [0.0|655.35] "" Vector__XXX
 SG_ Water_Temperature : 256|16@1+ (0.01,0) [0.0|655.35] "" Vector__XXX
 SG_ Station_ID : 272|8@1+ (1.0,0) [0|255] "" Vector__XXX

BO_ 2583501056 PGN_130329_hvacStatus: 28 Vector__XXX
 SG_ HVAC_Identifier : 0|8@1+ (1.0,0) [0|255] "" Vector__XXX
 SG_ Location : 8|8@1+ (1.0,0) [0|255] "" Vector__XXX
 SG_ Operating_Mode : 16|4@1+ (1.0,0) [0|15] "" Vector__XXX
 SG_ Control_Operating_State : 20|4@1+ (1.0,0) [0|15] "" Vector__XXX
 SG_ Power : 24|2@1+ (1.0,0) [0|3] "" Vector__XXX
 SG_ Fan_Speed_Mode_Changeable : 26|2@1+ (1.0,0) [0|3] "" Vector__XXX
 SG_ Fan_Speed_Mode : 28|2@1+ (1.0,0) [0|3] "" Vector__XXX
 SG_ Fan_Operation_Mode : 30|2@1+ (1.0,0) [0|3] "" Vector__XXX
 SG_ Fan_Speed_Available : 32|8@1+ (1.0,0) [0|255] "" Vector__XXX
 SG_ Fan_Speed : 40|8@1+ (1.0,0) [0|255] "" Vector__XXX
 SG_ Setpoint_Type : 48|8@1+ (1.0,0) [0|255] "" Vector__XXX
 SG_ Lower_Temperature_Setpoint : 56|16@1+ (0.01,0) [0.0|655.35] "" Vector__XXX
 SG_ Upper_Temperature_Setpoint : 72|16@1+ (0.01,0) [0.0|655.35] "" Vector__XXX
 SG_ Lower_Humidity_Setpoint : 88|8@1- (1.0,0) [-128|127] "" Vector__XXX
 SG_ Upper_Humidity_Setpoint : 96|8@1- (1.0,0) [-128|127] "" Vector__XXX
 SG_ Auxiliary_Heat_Control_Supported : 104|4@1+ (1.0,0) [0|15] "" Vector__XXX
 SG_ Auxiliary_Heat_Automatic_Mode : 108|2@1+ (1.0,0) [0|3] "" Vector__XXX
 SG_ Auxiliary_Heat_State : 110|2@1+ (1.0,0) [0|3] "" Vector__XXX
 SG_ Current_Temperature : 112|16@1+ (0.01,0) [0.0|655.35] "" Vector__XXX
 SG_ Current_Humidity : 128|8@1- (1.0,0) [-128|127] "" Vector__XXX
 SG_ Supported_Modes : 136|16@1+ (1.0,0) [0|65535] "" Vector__XXX
 SG_ Sea_Water_Temperature : 152|16@1+ (0.01,0) [0.0|655.35] "" Vector__XXX
 SG_ Loop_Temperature : 168|16@1+ (0.01,0) [0.0|655.35] "" Vector__XXX
 SG_ Evaporator_Temperature : 184|16@1+ (0.01,0) [0.0|655.35] "" Vector__XXX
 SG_ Inlet_Temperature : 200|16@1+ (0.01,0) [0.0|655.35] "" Vector__XXX
 SG_ Inlet_Humidity : 216|8@1- (1.0,0) [-128|127] "" Vector__XXX

BO_ 2650610176 PGN_130330_lightingSystemSettings: 13 Vector__XXX
 SG_ Global_Enable : 0|2@1+ (1.0,0) [0|3] "" Vector__XXX
 SG_ Default_Settings_Command : 2|3@1+ (1.0,0) [0|7] "" Vector__XXX
 SG_ Name_of_the_lighting_controller : 8|8@1+ (1.0,0) [0|255] "" Vector__XXX
 SG_ Max_Scenes : 16|8@1+ (1.0,0) [0|255] "" Vector__XXX
 SG_ Max_Scene_Configuration_Count : 24|8@1+ (1.0,0) [0|255] "" Vector__XXX
 SG_ Max_Zones : 32|8@1+ (1.0,0) [0|255] "" Vector__XXX
 SG_ Max_Color_Sequences : 40|8@1+ (1.0,0) [0|255] "" Vector__XXX
 SG_ Max_Color_Sequence_Color_Count : 48|8@1+ (1.0,0) [0|255] "" Vector__XXX
 SG_ Number_of_Programs : 56|8@1+ (1.0,0) [0|255] "" Vector__XXX
 SG_ Controller_Capabilities : 64|8@1+ (1.0,0) [0|255] "" Vector__XXX
 SG_ Identify_Device : 72|32@1+ (1.0,0) [0|4294967295] "" Vector__XXX

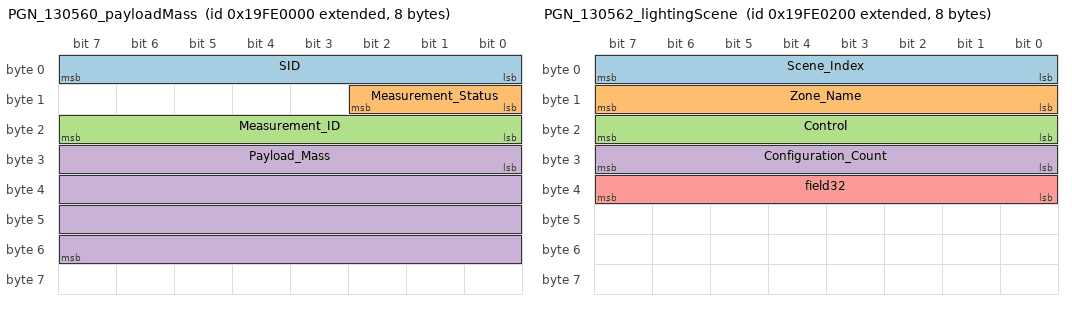
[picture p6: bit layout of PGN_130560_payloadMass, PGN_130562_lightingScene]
BO_ 2583560192 PGN_130560_payloadMass: 8 Vector__XXX
 SG_ SID : 0|8@1+ (1.0,0) [0|255] "" Vector__XXX
 SG_ Measurement_Status : 8|3@1+ (1.0,0) [0|7] "" Vector__XXX
 SG_ Measurement_ID : 16|8@1+ (1.0,0) [0|255] "" Vector__XXX
 SG_ Payload_Mass : 24|32@1+ (1.0,0) [0|4294967295] "" Vector__XXX

BO_ 2583560448 PGN_130561_lightingZone: 14 Vector__XXX
 SG_ Zone_Index : 0|8@1+ (1.0,0) [0|255] "" Vector__XXX
 SG_ Zone_Name : 8|8@1+ (1.0,0) [0|255] "" Vector__XXX
 SG_ Red_Component : 16|8@1+ (1.0,0) [0|255] "" Vector__XXX
 SG_ Green_Component : 24|8@1+ (1.0,0) [0|255] "" Vector__XXX
 SG_ Blue_Component : 32|8@1+ (1.0,0) [0|255] "" Vector__XXX
 SG_ Color_Temperature : 40|16@1+ (1.0,0) [0|65535] "" Vector__XXX
 SG_ Intensity : 56|8@1+ (1.0,0) [0|255] "" Vector__XXX
 SG_ Program_ID : 64|8@1+ (1.0,0) [0|255] "" Vector__XXX
 SG_ Program_Color_Sequence_Index : 72|8@1+ (1.0,0) [0|255] "" Vector__XXX
 SG_ Program_Intensity : 80|8@1+ (1.0,0) [0|255] "" Vector__XXX
 SG_ Program_Rate : 88|8@1+ (1.0,0) [0|255] "" Vector__XXX
 SG_ Program_Color_Sequence : 96|8@1+ (1.0,0) [0|255] "" Vector__XXX
 SG_ Zone_Enabled : 104|2@1+ (1.0,0) [0|3] "" Vector__XXX

BO_ 2583560704 PGN_130562_lightingScene: 8 Vector__XXX
 SG_ Scene_Index : 0|8@1+ (1.0,0) [0|255] "" Vector__XXX
 SG_ Zone_Name : 8|8@1+ (1.0,0) [0|255] "" Vector__XXX
 SG_ Control : 16|8@1+ (1.0,0) [0|255] "" Vector__XXX
 SG_ Configuration_Count : 24|8@1+ (1.0,0) [0|255] "" Vector__XXX
 SG_ field32 : 32|8@1+ (1.0,0) [0|255] "" Vector__XXX

BO_ 2583560960 PGN_130563_lightingDevice: 21 Vector__XXX
 SG_ Device_ID : 0|32@1+ (1.0,0) [0|4294967295] "" Vector__XXX
 SG_ Device_Capabilities : 32|8@1+ (1.0,0) [0|255] "" Vector__XXX
 SG_ Color_Capabilities : 40|8@1+ (1.0,0) [0|255] "" Vector__XXX
 SG_ Zone_Index : 48|8@1+ (1.0,0) [0|255] "" Vector__XXX
 SG_ Name_of_Lighting_Device : 56|8@1+ (1.0,0) [0|255] "" Vector__XXX
 SG_ Status : 64|8@1+ (1.0,0) [0|255] "" Vector__XXX
 SG_ Red_Component : 72|8@1+ (1.0,0) [0|255] "" Vector__XXX
 SG_ Green_Component : 80|8@1+ (1.0,0) [0|255] "" Vector__XXX
 SG_ Blue_Component : 88|8@1+ (1.0,0) [0|255] "" Vector__XXX
 SG_ Color_Temperature : 96|16@1+ (1.0,0) [0|65535] "" Vector__XXX
 SG_ Intensity : 112|8@1+ (1.0,0) [0|255] "" Vector__XXX
 SG_ Program_ID : 120|8@1+ (1.0,0) [0|255] "" Vector__XXX
 SG_ Program_Color_Sequence_Index : 128|8@1+ (1.0,0) [0|255] "" Vector__XXX
 SG_ Program_Intensity : 136|8@1+ (1.0,0) [0|255] "" Vector__XXX
 SG_ Program_Rate : 144|8@1+ (1.0,0) [0|255] "" Vector__XXX
 SG_ Program_Color_Sequence_Rate : 152|8@1+ (1.0,0) [0|255] "" Vector__XXX
 SG_ Enabled : 160|2@1+ (1.0,0) [0|3] "" Vector__XXX

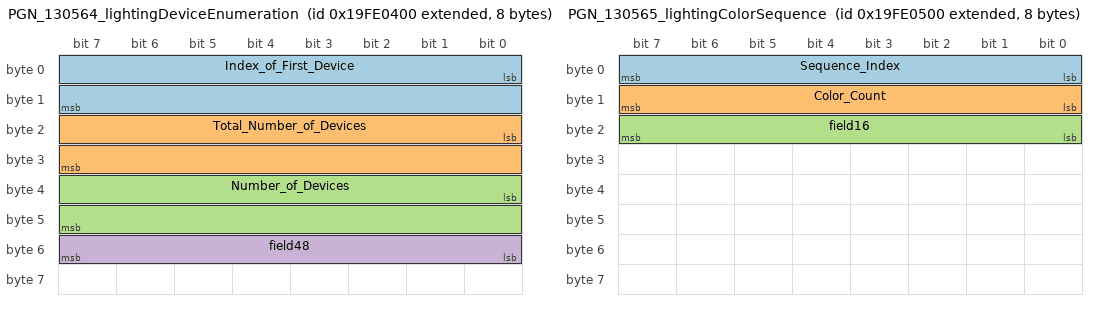
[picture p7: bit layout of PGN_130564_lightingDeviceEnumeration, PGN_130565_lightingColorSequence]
BO_ 2583561216 PGN_130564_lightingDeviceEnumeration: 8 Vector__XXX
 SG_ Index_of_First_Device : 0|16@1+ (1.0,0) [0|65535] "" Vector__XXX
 SG_ Total_Number_of_Devices : 16|16@1+ (1.0,0) [0|65535] "" Vector__XXX
 SG_ Number_of_Devices : 32|16@1+ (1.0,0) [0|65535] "" Vector__XXX
 SG_ field48 : 48|8@1+ (1.0,0) [0|255] "" Vector__XXX

BO_ 2583561472 PGN_130565_lightingColorSequence: 8 Vector__XXX
 SG_ Sequence_Index : 0|8@1+ (1.0,0) [0|255] "" Vector__XXX
 SG_ Color_Count : 8|8@1+ (1.0,0) [0|255] "" Vector__XXX
 SG_ field16 : 16|8@1+ (1.0,0) [0|255] "" Vector__XXX

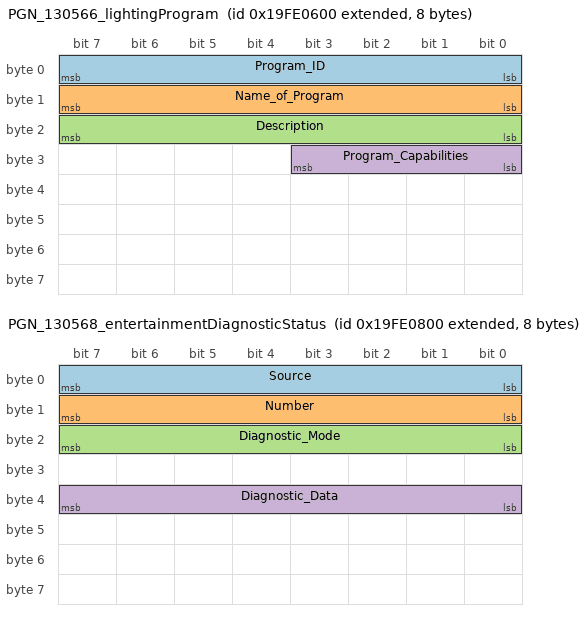
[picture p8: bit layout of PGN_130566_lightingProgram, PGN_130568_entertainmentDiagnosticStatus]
BO_ 2583561728 PGN_130566_lightingProgram: 8 Vector__XXX
 SG_ Program_ID : 0|8@1+ (1.0,0) [0|255] "" Vector__XXX
 SG_ Name_of_Program : 8|8@1+ (1.0,0) [0|255] "" Vector__XXX
 SG_ Description : 16|8@1+ (1.0,0) [0|255] "" Vector__XXX
 SG_ Program_Capabilities : 24|4@1+ (1.0,0) [0|15] "" Vector__XXX

BO_ 2583561984 PGN_130567_watermakerInputSettingAndStatus: 24 Vector__XXX
 SG_ Watermaker_Operating_State : 0|6@1+ (1.0,0) [0|63] "" Vector__XXX
 SG_ Production_Start_Stop : 6|2@1+ (1.0,0) [0|3] "" Vector__XXX
 SG_ Rinse_Start_Stop : 8|2@1+ (1.0,0) [0|3] "" Vector__XXX
 SG_ Low_Pressure_Pump_Status : 10|2@1+ (1.0,0) [0|3] "" Vector__XXX
 SG_ High_Pressure_Pump_Status : 12|2@1+ (1.0,0) [0|3] "" Vector__XXX
 SG_ Emergency_Stop : 14|2@1+ (1.0,0) [0|3] "" Vector__XXX
 SG_ Product_Solenoid_Valve_Status : 16|2@1+ (1.0,0) [0|3] "" Vector__XXX
 SG_ Flush_Mode_Status : 18|2@1+ (1.0,0) [0|3] "" Vector__XXX
 SG_ Salinity_Status : 20|2@1+ (1.0,0) [0|3] "" Vector__XXX
 SG_ Sensor_Status : 22|2@1+ (1.0,0) [0|3] "" Vector__XXX
 SG_ Oil_Change_Indicator_Status : 24|2@1+ (1.0,0) [0|3] "" Vector__XXX
 SG_ Filter_Status : 26|2@1+ (1.0,0) [0|3] "" Vector__XXX
 SG_ System_Status : 28|2@1+ (1.0,0) [0|3] "" Vector__XXX
 SG_ Salinity : 32|16@1+ (1.0,0) [0|65535] "" Vector__XXX
 SG_ Product_Water_Temperature : 48|16@1+ (0.01,0) [0.0|655.35] "" Vector__XXX
 SG_ Pre_filter_Pressure : 64|16@1+ (100.0,0) [0.0|6553500.0] "" Vector__XXX
 SG_ Post_filter_Pressure : 80|16@1+ (100.0,0) [0.0|6553500.0] "" Vector__XXX
 SG_ Feed_Pressure : 96|16@1- (1000.0,0) [-32768000.0|32767000.0] "" Vector__XXX
 SG_ System_High_Pressure : 112|16@1+ (1000.0,0) [0.0|65535000.0] "" Vector__XXX
 SG_ Product_Water_Flow : 128|16@1- (0.1,0) [-3276.8|3276.7000000000003] "" Vector__XXX
 SG_ Brine_Water_Flow : 144|16@1- (0.1,0) [-3276.8|3276.7000000000003] "" Vector__XXX
 SG_ Run_Time : 160|32@1+ (1.0,0) [0|4294967295] "" Vector__XXX

BO_ 2583562240 PGN_130568_entertainmentDiagnosticStatus: 8 Vector__XXX
 SG_ Source : 0|8@1+ (1.0,0) [0|255] "" Vector__XXX
 SG_ Number : 8|8@1+ (1.0,0) [0|255] "" Vector__XXX
 SG_ Diagnostic_Mode : 16|8@1+ (1.0,0) [0|255] "" Vector__XXX
 SG_ Diagnostic_Data : 32|8@1+ (1.0,0) [0|255] "" Vector__XXX

BO_ 2583562496 PGN_130569_currentStatusAndFile: 26 Vector__XXX
 SG_ Zone : 0|8@1+ (1.0,0) [0|255] "" Vector__XXX
 SG_ Source : 8|8@1+ (1.0,0) [0|255] "" Vector__XXX
 SG_ Number : 16|8@1+ (1.0,0) [0|255] "" Vector__XXX
 SG_ ID : 24|32@1+ (1.0,0) [0|4294967295] "" Vector__XXX
 SG_ Play_status : 56|8@1+ (1.0,0) [0|255] "" Vector__XXX
 SG_ Elapsed_Track_Time : 64|16@1+ (1.0,0) [0|65535] "" Vector__XXX
 SG_ Track_Time : 80|16@1+ (1.0,0) [0|65535] "" Vector__XXX
 SG_ Repeat_Status : 96|4@1+ (1.0,0) [0|15] "" Vector__XXX
 SG_ Shuffle_Status : 100|4@1+ (1.0,0) [0|15] "" Vector__XXX
 SG_ Save_Favorite_Number : 104|8@1+ (1.0,0) [0|255] "" Vector__XXX
 SG_ Play_Favorite_Number : 112|16@1+ (1.0,0) [0|65535] "" Vector__XXX
 SG_ Thumbs_Up_Down : 128|8@1+ (1.0,0) [0|255] "" Vector__XXX
 SG_ Signal_Strength : 136|8@1+ (1.0,0) [0|255] "%" Vector__XXX
 SG_ Radio_Frequency : 144|32@1+ (10.0,0) [0.0|42949672950.0] "" Vector__XXX
 SG_ HD_Frequency_Multicast : 176|8@1+ (1.0,0) [0|255] "" Vector__XXX
 SG_ Delete_Favorite_Number : 184|8@1+ (1.0,0) [0|255] "" Vector__XXX
 SG_ Total_Number_of_Tracks : 192|16@1+ (1.0,0) [0|65535] "" Vector__XXX

BO_ 2583562752 PGN_130570_libraryDataFile: 23 Vector__XXX
 SG_ Source : 0|8@1+ (1.0,0) [0|255] "" Vector__XXX
 SG_ Number : 8|8@1+ (1.0,0) [0|255] "" Vector__XXX
 SG_ ID : 16|32@1+ (1.0,0) [0|4294967295] "" Vector__XXX
 SG_ Type : 48|8@1+ (1.0,0) [0|255] "" Vector__XXX
 SG_ Name : 56|8@1+ (1.0,0) [0|255] "" Vector__XXX
 SG_ Track : 64|16@1+ (1.0,0) [0|65535] "" Vector__XXX
 SG_ Station : 80|16@1+ (1.0,0) [0|65535] "" Vector__XXX
 SG_ Favorite : 96|8@1+ (1.0,0) [0|255] "" Vector__XXX
 SG_ Radio_Frequency : 104|32@1+ (10.0,0) [0.0|42949672950.0] "" Vector__XXX
 SG_ HD_Frequency : 136|8@1+ (1.0,0) [0|255] "" Vector__XXX
 SG_ Zone : 144|8@1+ (1.0,0) [0|255] "" Vector__XXX
 SG_ In_play_queue : 152|2@1+ (1.0,0) [0|3] "" Vector__XXX
 SG_ Locked : 154|2@1+ (1.0,0) [0|3] "" Vector__XXX
 SG_ Artist_Name : 160|8@1+ (1.0,0) [0|255] "" Vector__XXX
 SG_ Album_Name : 168|8@1+ (1.0,0) [0|255] "" Vector__XXX
 SG_ Station_Name : 176|8@1+ (1.0,0) [0|255] "" Vector__XXX

BO_ 2583563008 PGN_130571_libraryDataGroup: 16 Vector__XXX
 SG_ Source : 0|8@1+ (1.0,0) [0|255] "" Vector__XXX
 SG_ Number : 8|8@1+ (1.0,0) [0|255] "" Vector__XXX
 SG_ Type : 16|8@1+ (1.0,0) [0|255] "" Vector__XXX
 SG_ Zone : 24|8@1+ (1.0,0) [0|255] "" Vector__XXX
 SG_ Group_ID : 32|32@1+ (1.0,0) [0|4294967295] "" Vector__XXX
 SG_ ID_offset : 64|16@1+ (1.0,0) [0|65535] "" Vector__XXX
 SG_ ID_count : 80|16@1+ (1.0,0) [0|65535] "" Vector__XXX
 SG_ Total_ID_count : 96|16@1+ (1.0,0) [0|65535] "" Vector__XXX
 SG_ field112 : 112|8@1+ (1.0,0) [0|255] "" Vector__XXX
 SG_ Artist : 120|8@1+ (1.0,0) [0|255] "" Vector__XXX

BO_ 2583563264 PGN_130572_libraryDataSearch: 12 Vector__XXX
 SG_ Source : 0|8@1+ (1.0,0) [0|255] "" Vector__XXX
 SG_ Number : 8|8@1+ (1.0,0) [0|255] "" Vector__XXX
 SG_ Group_ID : 16|32@1+ (1.0,0) [0|4294967295] "" Vector__XXX
 SG_ Group_type_1 : 48|8@1+ (1.0,0) [0|255] "" Vector__XXX
 SG_ Group_name_1 : 56|8@1+ (1.0,0) [0|255] "" Vector__XXX
 SG_ Group_type_2 : 64|8@1+ (1.0,0) [0|255] "" Vector__XXX
 SG_ Group_name_2 : 72|8@1+ (1.0,0) [0|255] "" Vector__XXX
 SG_ Group_type_3 : 80|8@1+ (1.0,0) [0|255] "" Vector__XXX
 SG_ Group_name_3 : 88|8@1+ (1.0,0) [0|255] "" Vector__XXX

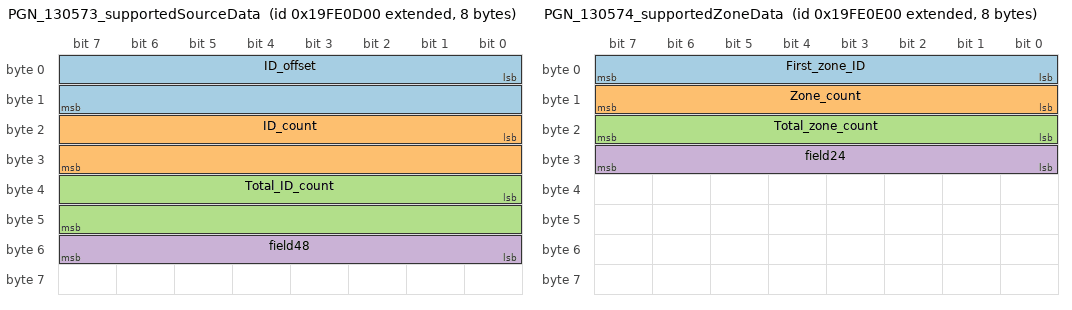
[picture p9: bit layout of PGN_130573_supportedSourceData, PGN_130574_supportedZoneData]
BO_ 2583563520 PGN_130573_supportedSourceData: 8 Vector__XXX
 SG_ ID_offset : 0|16@1+ (1.0,0) [0|65535] "" Vector__XXX
 SG_ ID_count : 16|16@1+ (1.0,0) [0|65535] "" Vector__XXX
 SG_ Total_ID_count : 32|16@1+ (1.0,0) [0|65535] "" Vector__XXX
 SG_ field48 : 48|8@1+ (1.0,0) [0|255] "" Vector__XXX

BO_ 2583563776 PGN_130574_supportedZoneData: 8 Vector__XXX
 SG_ First_zone_ID : 0|8@1+ (1.0,0) [0|255] "" Vector__XXX
 SG_ Zone_count : 8|8@1+ (1.0,0) [0|255] "" Vector__XXX
 SG_ Total_zone_count : 16|8@1+ (1.0,0) [0|255] "" Vector__XXX
 SG_ field24 : 24|8@1+ (1.0,0) [0|255] "" Vector__XXX

BO_ 2583564032 PGN_130575_entertainmentParentalControlStatus: 9 Vector__XXX
 SG_ Source : 0|8@1+ (1.0,0) [0|255] "" Vector__XXX
 SG_ Number : 8|8@1+ (1.0,0) [0|255] "" Vector__XXX
 SG_ Lock_Type : 16|4@1+ (1.0,0) [0|15] "" Vector__XXX
 SG_ Lock_Status : 20|2@1+ (1.0,0) [0|3] "" Vector__XXX
 SG_ File___Station_ID : 24|32@1+ (1.0,0) [0|4294967295] "" Vector__XXX
 SG_ Current_Pincode : 56|8@1+ (1.0,0) [0|255] "" Vector__XXX
 SG_ New_Pincode : 64|8@1+ (1.0,0) [0|255] "" Vector__XXX

BO_ 2315128832 PGN_130576_smallCraftStatus: 8 Vector__XXX
 SG_ Port_trim_tab : 0|8@1- (1.0,0) [-128|127] "%" Vector__XXX
 SG_ Starboard_trim_tab : 8|8@1- (1.0,0) [-128|127] "%" Vector__XXX

BO_ 2382237952 PGN_130577_directionData: 14 Vector__XXX
 SG_ Data_Mode : 0|4@1+ (1.0,0) [0|15] "" Vector__XXX
 SG_ COG_Reference : 4|2@1+ (1.0,0) [0|3] "" Vector__XXX
 SG_ SID : 8|8@1+ (1.0,0) [0|255] "" Vector__XXX
 SG_ COG : 16|16@1+ (0.0001,0) [0.0|6.5535000000000005] "" Vector__XXX
 SG_ SOG : 32|16@1+ (0.01,0) [0.0|655.35] "" Vector__XXX
 SG_ Heading : 48|16@1+ (0.0001,0) [0.0|6.5535000000000005] "" Vector__XXX
 SG_ Speed_through_Water : 64|16@1+ (0.01,0) [0.0|655.35] "" Vector__XXX
 SG_ Set : 80|16@1+ (0.0001,0) [0.0|6.5535000000000005] "" Vector__XXX
 SG_ Drift : 96|16@1+ (0.01,0) [0.0|655.35] "" Vector__XXX

BO_ 2315129344 PGN_130578_vesselSpeedComponents: 12 Vector__XXX
 SG_ Longitudinal_Speed__Water_referenced : 0|16@1- (0.001,0) [-32.768|32.767] "" Vector__XXX
 SG_ Transverse_Speed__Water_referenced : 16|16@1- (0.001,0) [-32.768|32.767] "" Vector__XXX
 SG_ Longitudinal_Speed__Ground_referenced : 32|16@1- (0.001,0) [-32.768|32.767] "" Vector__XXX
 SG_ Transverse_Speed__Ground_referenced : 48|16@1- (0.001,0) [-32.768|32.767] "" Vector__XXX
 SG_ Stern_Speed__Water_referenced : 64|16@1- (0.001,0) [-32.768|32.767] "" Vector__XXX
 SG_ Stern_Speed__Ground_referenced : 80|16@1- (0.001,0) [-32.768|32.767] "" Vector__XXX

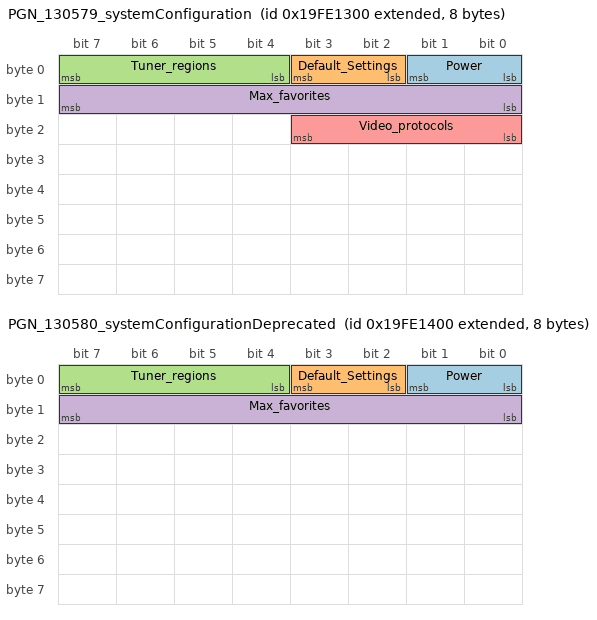
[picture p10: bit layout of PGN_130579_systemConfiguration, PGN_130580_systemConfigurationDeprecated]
BO_ 2583565056 PGN_130579_systemConfiguration: 8 Vector__XXX
 SG_ Power : 0|2@1+ (1.0,0) [0|3] "" Vector__XXX
 SG_ Default_Settings : 2|2@1+ (1.0,0) [0|3] "" Vector__XXX
 SG_ Tuner_regions : 4|4@1+ (1.0,0) [0|15] "" Vector__XXX
 SG_ Max_favorites : 8|8@1+ (1.0,0) [0|255] "" Vector__XXX
 SG_ Video_protocols : 16|4@1+ (1.0,0) [0|15] "" Vector__XXX

BO_ 2583565312 PGN_130580_systemConfigurationDeprecated: 8 Vector__XXX
 SG_ Power : 0|2@1+ (1.0,0) [0|3] "" Vector__XXX
 SG_ Default_Settings : 2|2@1+ (1.0,0) [0|3] "" Vector__XXX
 SG_ Tuner_regions : 4|4@1+ (1.0,0) [0|15] "" Vector__XXX
 SG_ Max_favorites : 8|8@1+ (1.0,0) [0|255] "" Vector__XXX

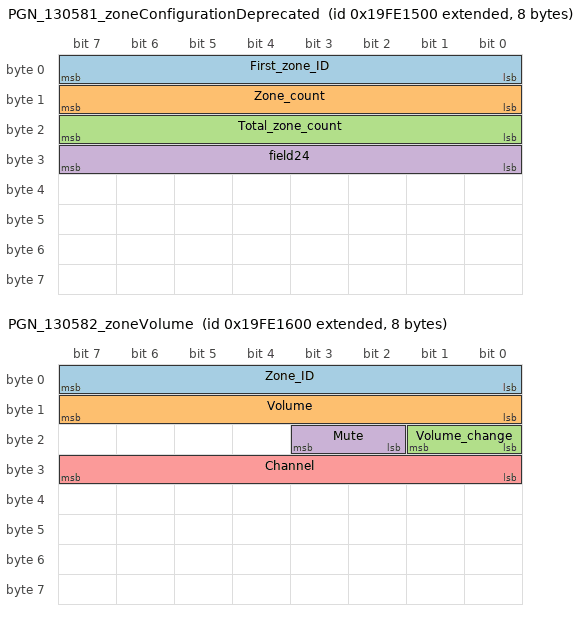
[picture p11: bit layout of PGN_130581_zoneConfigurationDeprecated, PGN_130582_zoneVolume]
BO_ 2583565568 PGN_130581_zoneConfigurationDeprecated: 8 Vector__XXX
 SG_ First_zone_ID : 0|8@1+ (1.0,0) [0|255] "" Vector__XXX
 SG_ Zone_count : 8|8@1+ (1.0,0) [0|255] "" Vector__XXX
 SG_ Total_zone_count : 16|8@1+ (1.0,0) [0|255] "" Vector__XXX
 SG_ field24 : 24|8@1+ (1.0,0) [0|255] "" Vector__XXX

BO_ 2583565824 PGN_130582_zoneVolume: 8 Vector__XXX
 SG_ Zone_ID : 0|8@1+ (1.0,0) [0|255] "" Vector__XXX
 SG_ Volume : 8|8@1+ (1.0,0) [0|255] "%" Vector__XXX
 SG_ Volume_change : 16|2@1+ (1.0,0) [0|3] "" Vector__XXX
 SG_ Mute : 18|2@1+ (1.0,0) [0|3] "" Vector__XXX
 SG_ Channel : 24|8@1+ (1.0,0) [0|255] "" Vector__XXX

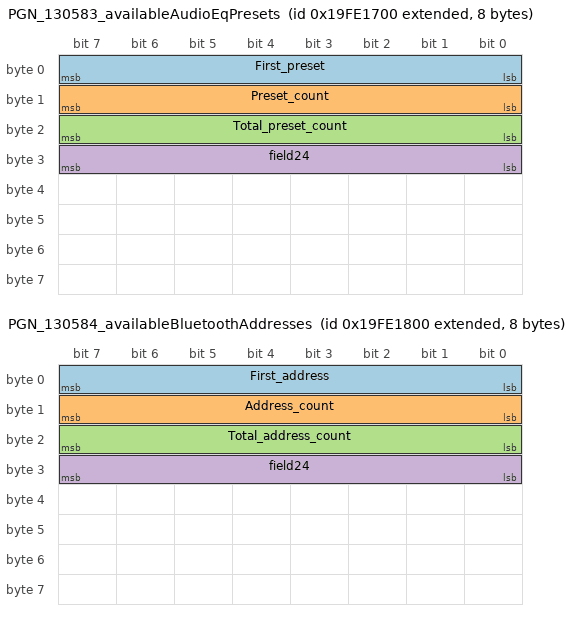
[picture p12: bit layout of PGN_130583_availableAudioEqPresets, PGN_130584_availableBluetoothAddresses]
BO_ 2583566080 PGN_130583_availableAudioEqPresets: 8 Vector__XXX
 SG_ First_preset : 0|8@1+ (1.0,0) [0|255] "" Vector__XXX
 SG_ Preset_count : 8|8@1+ (1.0,0) [0|255] "" Vector__XXX
 SG_ Total_preset_count : 16|8@1+ (1.0,0) [0|255] "" Vector__XXX
 SG_ field24 : 24|8@1+ (1.0,0) [0|255] "" Vector__XXX

BO_ 2583566336 PGN_130584_availableBluetoothAddresses: 8 Vector__XXX
 SG_ First_address : 0|8@1+ (1.0,0) [0|255] "" Vector__XXX
 SG_ Address_count : 8|8@1+ (1.0,0) [0|255] "" Vector__XXX
 SG_ Total_address_count : 16|8@1+ (1.0,0) [0|255] "" Vector__XXX
 SG_ field24 : 24|8@1+ (1.0,0) [0|255] "" Vector__XXX

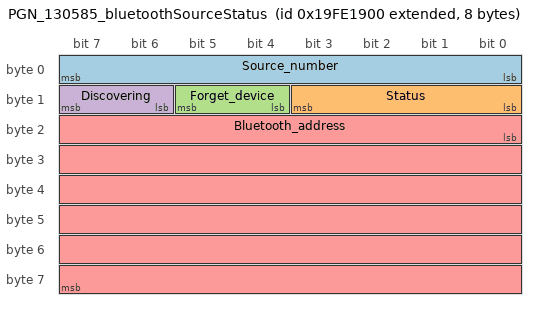
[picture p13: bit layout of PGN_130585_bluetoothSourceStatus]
BO_ 2583566592 PGN_130585_bluetoothSourceStatus: 8 Vector__XXX
 SG_ Source_number : 0|8@1+ (1.0,0) [0|255] "" Vector__XXX
 SG_ Status : 8|4@1+ (1.0,0) [0|15] "" Vector__XXX
 SG_ Forget_device : 12|2@1+ (1.0,0) [0|3] "" Vector__XXX
 SG_ Discovering : 14|2@1+ (1.0,0) [0|3] "" Vector__XXX
 SG_ Bluetooth_address : 16|48@1+ (1.0,0) [0|281474976710655] "" Vector__XXX

BO_ 2583566848 PGN_130586_zoneConfiguration: 15 Vector__XXX
 SG_ Zone_ID : 0|8@1+ (1.0,0) [0|255] "" Vector__XXX
 SG_ Volume_limit : 8|8@1+ (1.0,0) [0|255] "%" Vector__XXX
 SG_ Fade : 16|8@1- (1.0,0) [-128|127] "%" Vector__XXX
 SG_ Balance : 24|8@1- (1.0,0) [-128|127] "%" Vector__XXX
 SG_ Sub_volume : 32|8@1+ (1.0,0) [0|255] "%" Vector__XXX
 SG_ EQ___Treble : 40|8@1- (1.0,0) [-128|127] "%" Vector__XXX
 SG_ EQ___Mid_range : 48|8@1- (1.0,0) [-128|127] "%" Vector__XXX
 SG_ EQ___Bass : 56|8@1- (1.0,0) [-128|127] "%" Vector__XXX
 SG_ Preset_type : 64|8@1+ (1.0,0) [0|255] "" Vector__XXX
 SG_ Audio_filter : 72|8@1+ (1.0,0) [0|255] "" Vector__XXX
 SG_ High_pass_filter_frequency : 80|16@1+ (1.0,0) [0|65535] "" Vector__XXX
 SG_ Low_pass_filter_frequency : 96|16@1+ (1.0,0) [0|65535] "" Vector__XXX
 SG_ Channel : 112|8@1+ (1.0,0) [0|255] "" Vector__XXX

BO_ 2583625728 PGN_130816: 225 Vector__XXX
 SG_ Manufacturer_Code : 0|11@1+ (1.0,0) [0|2047] "" Vector__XXX
 SG_ Industry_Code : 13|3@1+ (1.0,0) [0|7] "" Vector__XXX
 SG_ Data : 16|1784@1+ (1.0,0) [0|1090215279796298345343057319992441691038624747443985361781209060500115864369550760897269927218265076257224706224150656474098235960303036328065314058501678867531182833105052489870268422279120576700031813116210596361941430020414688522690787050244934600671795757515093047026287646566366777283893649942831776083163858446641848270013788759459916945946844663111358071639842481472666169361795887031940572252862030682746818684507336852618633070135215708762463263460541984102045620907003420426453486084172633338261276848631947315738747720031010815] "" Vector__XXX

BO_ 2583625728 PGN_130816_bepMarineCzoneZcfBusDistribution: 223 Vector__XXX
 SG_ Manufacturer_Code : 0|11@1+ (1.0,0) [0|2047] "" Vector__XXX
 SG_ Industry_Code : 13|3@1+ (1.0,0) [0|7] "" Vector__XXX
 SG_ Chunk_Index : 16|16@1+ (1.0,0) [0|65535] "" Vector__XXX
 SG_ Flag : 32|8@1+ (1.0,0) [0|255] "" Vector__XXX
 SG_ Data : 184|1600@1+ (1.0,0) [0|44462416477094044620016814065517364315819234512137839319418223093753683069769152238984782576173969417485953521141049383745107056455283979316385016701612810119562585078620415976730705698345087039035930761275083827265405596065418173652685035788898113991627042329246850314029877161622487411877779578892097029690461532001915311366862468942148892205997883828265721290296220249202674740669814705818564765009960300389641843321936008416473775144511929246788246559538970957296160626364645375] "" Vector__XXX

BO_ 2583625728 PGN_130816_hondaEngineStatus: 8 Vector__XXX
 SG_ Manufacturer_Code : 0|11@1+ (1.0,0) [0|2047] "" Vector__XXX
 SG_ Industry_Code : 13|3@1+ (1.0,0) [0|7] "" Vector__XXX

BO_ 2583625728 PGN_130816_seaRecoveryWatermakerStatus: 14 Vector__XXX
 SG_ Manufacturer_Code : 0|11@1+ (1.0,0) [0|2047] "" Vector__XXX
 SG_ Industry_Code : 13|3@1+ (1.0,0) [0|7] "" Vector__XXX
 SG_ Message_ID : 16|8@1+ (1.0,0) [0|255] "" Vector__XXX
 SG_ Watermaker_Instance : 24|4@1+ (1.0,0) [0|15] "" Vector__XXX
 SG_ Operation_State : 28|4@1+ (1.0,0) [0|15] "" Vector__XXX
 SG_ Prefilter_Pressure : 32|16@1+ (1.0,0) [0|65535] "" Vector__XXX
 SG_ Postfilter_Pressure : 48|16@1+ (1.0,0) [0|65535] "" Vector__XXX
 SG_ Operation_Pressure : 64|16@1+ (1.0,0) [0|65535] "" Vector__XXX
 SG_ Product_Flow : 80|16@1- (1.0,0) [-32768|32767] "" Vector__XXX
 SG_ Prefilter_Pressure_Status : 96|2@1+ (1.0,0) [0|3] "" Vector__XXX
 SG_ Postfilter_Pressure_Status : 98|2@1+ (1.0,0) [0|3] "" Vector__XXX
 SG_ Operation_Pressure_Status : 100|2@1+ (1.0,0) [0|3] "" Vector__XXX
 SG_ Product_Salinity_Status : 102|2@1+ (1.0,0) [0|3] "" Vector__XXX
 SG_ Filter_Status : 104|2@1+ (1.0,0) [0|3] "" Vector__XXX
 SG_ System_Status : 106|2@1+ (1.0,0) [0|3] "" Vector__XXX

CM_ BO_ 2650475776 "NMEA2000: PGN 129805 - AIS Data Link Management Message (type: Fast)";
CM_ BO_ 2650476032 "NMEA2000: PGN 129806 - AIS Channel Management (type: Fast)";
CM_ BO_ 2650476288 "NMEA2000: PGN 129807 - AIS Class B Group Assignment (type: Fast)";
CM_ BO_ 2449149952 "NMEA2000: PGN 129808 - DSC Call Information (type: Fast)";
CM_ BO_ 2449149952 "NMEA2000: PGN 129808 - DSC Distress Call Information (type: Fast)";
CM_ BO_ 2583367936 "NMEA2000: PGN 129809 - AIS Class B static data (msg 24 Part A) (type: Fast)";
CM_ BO_ 2583368192 "NMEA2000: PGN 129810 - AIS Class B static data (msg 24 Part B) (type: Fast)";
CM_ BO_ 2583368448 "NMEA2000: PGN 129811 - AIS Single Slot Binary Message (Deprecated) (type: Fast)";
CM_ BO_ 2583368704 "NMEA2000: PGN 129812 - AIS Multi Slot Binary Message (Deprecated) (type: Fast)";
CM_ BO_ 2583368960 "NMEA2000: PGN 129813 - AIS Long-Range Broadcast Message (type: Fast)";
CM_ BO_ 2583369216 "NMEA2000: PGN 129814 - AIS Single Slot Binary Message (type: Fast)";
CM_ BO_ 2583369472 "NMEA2000: PGN 129815 - AIS Multi Slot Binary Message (type: Fast)";
CM_ BO_ 2583369728 "NMEA2000: PGN 129816 - AIS Acknowledge (Binary) (type: Fast)";
CM_ BO_ 2382103552 "NMEA2000: PGN 130052 - Loran-C TD Data (type: Fast)";
CM_ BO_ 2382103808 "NMEA2000: PGN 130053 - Loran-C Range Data (type: Fast)";
CM_ BO_ 2382104064 "NMEA2000: PGN 130054 - Loran-C Signal Data (type: Fast)";
CM_ BO_ 2583432192 "NMEA2000: PGN 130060 - Label (type: Fast)";
CM_ BO_ 2583432448 "NMEA2000: PGN 130061 - Channel Source Configuration (type: Fast)";
CM_ BO_ 2650542080 "NMEA2000: PGN 130064 - Route and WP Service - Database List (type: Fast)";
CM_ BO_ 2650542336 "NMEA2000: PGN 130065 - Route and WP Service - Route List (type: Fast)";
CM_ BO_ 2650542592 "NMEA2000: PGN 130066 - Route and WP Service - Route/WP-List Attributes (type: Fast)";
CM_ BO_ 2650542848 "NMEA2000: PGN 130067 - Route and WP Service - Route - WP Name & Position (type: Fast)";
CM_ BO_ 2650543104 "NMEA2000: PGN 130068 - Route and WP Service - Route - WP Name (type: Fast)";
CM_ BO_ 2650543360 "NMEA2000: PGN 130069 - Route and WP Service - XTE Limit & Navigation Method (type: Fast)";
CM_ BO_ 2650543616 "NMEA2000: PGN 130070 - Route and WP Service - WP Comment (type: Fast)";
CM_ BO_ 2650543872 "NMEA2000: PGN 130071 - Route and WP Service - Route Comment (type: Fast)";
CM_ BO_ 2650544128 "NMEA2000: PGN 130072 - Route and WP Service - Database Comment (type: Fast)";
CM_ BO_ 2650544384 "NMEA2000: PGN 130073 - Route and WP Service - Radius of Turn (type: Fast)";
CM_ BO_ 2650544640 "NMEA2000: PGN 130074 - Route and WP Service - WP List - WP Name & Position (type: Fast)";
CM_ BO_ 2315059712 "NMEA2000: PGN 130306 - Wind Data (type: Single)";
CM_ BO_ 2516387328 "NMEA2000: PGN 130310 - Environmental Parameters (obsolete) (type: Single)";
CM_ BO_ 2516387584 "NMEA2000: PGN 130311 - Environmental Parameters (type: Single)";
CM_ BO_ 2516387840 "NMEA2000: PGN 130312 - Temperature (type: Single)";
CM_ BO_ 2516388096 "NMEA2000: PGN 130313 - Humidity (type: Single)";
CM_ BO_ 2516388352 "NMEA2000: PGN 130314 - Actual Pressure (type: Single)";
CM_ BO_ 2516388608 "NMEA2000: PGN 130315 - Set Pressure (type: Single)";
CM_ BO_ 2516388864 "NMEA2000: PGN 130316 - Temperature Extended Range (type: Single)";
CM_ BO_ 2583498752 "NMEA2000: PGN 130320 - Tide Station Data (type: Fast)";
CM_ BO_ 2583499008 "NMEA2000: PGN 130321 - Salinity Station Data (type: Fast)";
CM_ BO_ 2583499264 "NMEA2000: PGN 130322 - Current Station Data (type: Fast)";
CM_ BO_ 2583499520 "NMEA2000: PGN 130323 - Meteorological Station Data (type: Fast)";
CM_ BO_ 2583499776 "NMEA2000: PGN 130324 - Moored Buoy Station Data (type: Fast)";
CM_ BO_ 2583501056 "NMEA2000: PGN 130329 - HVAC Status (type: Fast)";
CM_ BO_ 2650610176 "NMEA2000: PGN 130330 - Lighting System Settings (type: Fast)";
CM_ BO_ 2583560192 "NMEA2000: PGN 130560 - Payload Mass (type: Single)";
CM_ BO_ 2583560448 "NMEA2000: PGN 130561 - Lighting Zone (type: Fast)";
CM_ BO_ 2583560704 "NMEA2000: PGN 130562 - Lighting Scene (type: Fast)";
CM_ BO_ 2583560960 "NMEA2000: PGN 130563 - Lighting Device (type: Fast)";
CM_ BO_ 2583561216 "NMEA2000: PGN 130564 - Lighting Device Enumeration (type: Fast)";
CM_ BO_ 2583561472 "NMEA2000: PGN 130565 - Lighting Color Sequence (type: Fast)";
CM_ BO_ 2583561728 "NMEA2000: PGN 130566 - Lighting Program (type: Fast)";
CM_ BO_ 2583561984 "NMEA2000: PGN 130567 - Watermaker Input Setting and Status (type: Fast)";
CM_ BO_ 2583562240 "NMEA2000: PGN 130568 - Entertainment - Diagnostic Status (type: Fast)";
CM_ BO_ 2583562496 "NMEA2000: PGN 130569 - Current Status and File (type: Fast)";
CM_ BO_ 2583562752 "NMEA2000: PGN 130570 - Library Data File (type: Fast)";
CM_ BO_ 2583563008 "NMEA2000: PGN 130571 - Library Data Group (type: Fast)";
CM_ BO_ 2583563264 "NMEA2000: PGN 130572 - Library Data Search (type: Fast)";
CM_ BO_ 2583563520 "NMEA2000: PGN 130573 - Supported Source Data (type: Fast)";
CM_ BO_ 2583563776 "NMEA2000: PGN 130574 - Supported Zone Data (type: Fast)";
CM_ BO_ 2583564032 "NMEA2000: PGN 130575 - Entertainment - Parental Control Status (type: Fast)";
CM_ BO_ 2315128832 "NMEA2000: PGN 130576 - Small Craft Status (type: Single)";
CM_ BO_ 2382237952 "NMEA2000: PGN 130577 - Direction Data (type: Fast)";
CM_ BO_ 2315129344 "NMEA2000: PGN 130578 - Vessel Speed Components (type: Fast)";
CM_ BO_ 2583565056 "NMEA2000: PGN 130579 - System Configuration (type: Single)";
CM_ BO_ 2583565312 "NMEA2000: PGN 130580 - System Configuration (deprecated) (type: Fast)";
CM_ BO_ 2583565568 "NMEA2000: PGN 130581 - Zone Configuration (deprecated) (type: Fast)";
CM_ BO_ 2583565824 "NMEA2000: PGN 130582 - Zone Volume (type: Single)";
CM_ BO_ 2583566080 "NMEA2000: PGN 130583 - Available Audio EQ presets (type: Fast)";
CM_ BO_ 2583566336 "NMEA2000: PGN 130584 - Available Bluetooth addresses (type: Fast)";
CM_ BO_ 2583566592 "NMEA2000: PGN 130585 - Bluetooth source status (type: Single)";
CM_ BO_ 2583566848 "NMEA2000: PGN 130586 - Zone Configuration (type: Fast)";
CM_ BO_ 2583625728 "NMEA2000: PGN 130816 - 0x1FF00-0x1FFFF: Manufacturer Specific fast-packet non-addressed (type: Fast)";
CM_ BO_ 2583625728 "NMEA2000: PGN 130816 - BEP Marine: CZone .zcf Bus Distribution (type: Fast)";
CM_ BO_ 2583625728 "NMEA2000: PGN 130816 - Honda: Engine Status (type: Fast)";
CM_ BO_ 2583625728 "NMEA2000: PGN 130816 - Sea Recovery: Watermaker Status (type: Fast)";
CM_ SG_ 2650475776 Message_ID "canboat type: LOOKUP";
CM_ SG_ 2650475776 Repeat_Indicator "canboat type: LOOKUP";
CM_ SG_ 2650475776 Source_ID "canboat type: MMSI";
CM_ SG_ 2650475776 AIS_Transceiver_information "canboat type: LOOKUP";
CM_ SG_ 2650475776 Spare "canboat type: SPARE";
CM_ SG_ 2650475776 field48 "canboat type: NUMBER";
CM_ SG_ 2650476032 Message_ID "canboat type: LOOKUP";
CM_ SG_ 2650476032 Repeat_Indicator "canboat type: LOOKUP";
CM_ SG_ 2650476032 Source_ID "canboat type: MMSI";
CM_ SG_ 2650476032 AIS_Transceiver_information "canboat type: LOOKUP";
CM_ SG_ 2650476032 Spare "canboat type: SPARE";
CM_ SG_ 2650476032 Channel_A "canboat type: UINT16";
CM_ SG_ 2650476032 Channel_B "canboat type: UINT16";
CM_ SG_ 2650476032 Power "canboat type: LOOKUP";
CM_ SG_ 2650476032 Tx_Rx_Mode "canboat type: LOOKUP";
CM_ SG_ 2650476032 North_East_Longitude_Corner_1 "canboat type: GEO_LON_FIX32";
CM_ SG_ 2650476032 North_East_Latitude_Corner_1 "canboat type: GEO_LAT_FIX32";
CM_ SG_ 2650476032 South_West_Longitude_Corner_2 "canboat type: GEO_LON_FIX32";
CM_ SG_ 2650476032 South_West_Latitude_Corner_2 "canboat type: GEO_LAT_FIX32";
CM_ SG_ 2650476032 Addressed_or_Broadcast_Message_Indicator "canboat type: LOOKUP";
CM_ SG_ 2650476032 Channel_A_Bandwidth "canboat type: LOOKUP";
CM_ SG_ 2650476032 Channel_B_Bandwidth "canboat type: LOOKUP";
CM_ SG_ 2650476032 Transitional_Zone_Size "canboat type: LOOKUP";
CM_ SG_ 2650476032 Spare_1 "canboat type: SPARE";
CM_ SG_ 2650476288 Message_ID "canboat type: LOOKUP";
CM_ SG_ 2650476288 Repeat_Indicator "canboat type: LOOKUP";
CM_ SG_ 2650476288 Source_ID "canboat type: MMSI";
CM_ SG_ 2650476288 Spare "canboat type: SPARE";
CM_ SG_ 2650476288 Tx_Rx_Mode "canboat type: LOOKUP";
CM_ SG_ 2650476288 North_East_Longitude_Corner_1 "canboat type: GEO_LON_FIX32";
CM_ SG_ 2650476288 North_East_Latitude_Corner_1 "canboat type: GEO_LAT_FIX32";
CM_ SG_ 2650476288 South_West_Longitude_Corner_2 "canboat type: GEO_LON_FIX32";
CM_ SG_ 2650476288 South_West_Latitude_Corner_2 "canboat type: GEO_LAT_FIX32";
CM_ SG_ 2650476288 Station_Type "canboat type: LOOKUP";
CM_ SG_ 2650476288 Ship_and_Cargo_Filter "canboat type: LOOKUP";
CM_ SG_ 2650476288 Spare_1 "canboat type: SPARE";
CM_ SG_ 2650476288 Reporting_Interval "canboat type: LOOKUP";
CM_ SG_ 2650476288 Quiet_Time "Commanded quiet time; canboat type: DURATION_UFIX4_MIN";
CM_ SG_ 2650476288 Spare_2 "canboat type: SPARE";
CM_ SG_ 2449149952 DSC_Format_Symbol "canboat type: LOOKUP";
CM_ SG_ 2449149952 DSC_Category_Symbol "canboat type: LOOKUP";
CM_ SG_ 2449149952 DSC_Message_Address "MMSI, Geographic Area or blank; canboat type: DECIMAL";
CM_ SG_ 2449149952 _1st_Telecommand "canboat type: LOOKUP";
CM_ SG_ 2449149952 Subsequent_Communication_Mode_or_2nd_Telecommand "canboat type: LOOKUP";
CM_ SG_ 2449149952 Proposed_Rx_Frequency_Channel "canboat type: STRING_FIX";
CM_ SG_ 2449149952 Proposed_Tx_Frequency_Channel "canboat type: STRING_FIX";
CM_ SG_ 2449149952 Telephone_Number "canboat type: STRING_LAU";
CM_ SG_ 2449149952 Latitude_of_Vessel_Reported "canboat type: GEO_LAT_FIX32";
CM_ SG_ 2449149952 Longitude_of_Vessel_Reported "canboat type: GEO_LON_FIX32";
CM_ SG_ 2449149952 Time_of_Position "Seconds since midnight; canboat type: TIME";
CM_ SG_ 2449149952 MMSI_of_Ship_In_Distress "canboat type: DECIMAL";
CM_ SG_ 2449149952 DSC_EOS_Symbol "canboat type: UINT8";
CM_ SG_ 2449149952 Expansion_Enabled "canboat type: LOOKUP";
CM_ SG_ 2449149952 Calling_Rx_Frequency_Channel "canboat type: STRING_FIX";
CM_ SG_ 2449149952 Calling_Tx_Frequency_Channel "canboat type: STRING_FIX";
CM_ SG_ 2449149952 Time_of_Receipt "Seconds since midnight; canboat type: TIME";
CM_ SG_ 2449149952 Date_of_Receipt "canboat type: DATE";
CM_ SG_ 2449149952 DSC_Equipment_Assigned_Message_ID "canboat type: UINT16";
CM_ SG_ 2449149952 field488 "canboat type: NUMBER";
CM_ SG_ 2449149952 DSC_Format "canboat type: LOOKUP";
CM_ SG_ 2449149952 DSC_Category "Distress; canboat type: LOOKUP";
CM_ SG_ 2449149952 DSC_Message_Address "MMSI, Geographic Area or blank; canboat type: DECIMAL";
CM_ SG_ 2449149952 Nature_of_Distress "canboat type: LOOKUP";
CM_ SG_ 2449149952 Subsequent_Communication_Mode_or_2nd_Telecommand "canboat type: LOOKUP";
CM_ SG_ 2449149952 Proposed_Rx_Frequency_Channel "canboat type: STRING_FIX";
CM_ SG_ 2449149952 Proposed_Tx_Frequency_Channel "canboat type: STRING_FIX";
CM_ SG_ 2449149952 Telephone_Number "canboat type: STRING_LAU";
CM_ SG_ 2449149952 Latitude_of_Vessel_Reported "canboat type: GEO_LAT_FIX32";
CM_ SG_ 2449149952 Longitude_of_Vessel_Reported "canboat type: GEO_LON_FIX32";
CM_ SG_ 2449149952 Time_of_Position "Seconds since midnight; canboat type: TIME";
CM_ SG_ 2449149952 MMSI_of_Ship_In_Distress "canboat type: DECIMAL";
CM_ SG_ 2449149952 DSC_EOS_Symbol "canboat type: UINT8";
CM_ SG_ 2449149952 Expansion_Enabled "canboat type: LOOKUP";
CM_ SG_ 2449149952 Calling_Rx_Frequency_Channel "canboat type: STRING_FIX";
CM_ SG_ 2449149952 Calling_Tx_Frequency_Channel "canboat type: STRING_FIX";
CM_ SG_ 2449149952 Time_of_Receipt "Seconds since midnight; canboat type: TIME";
CM_ SG_ 2449149952 Date_of_Receipt "canboat type: DATE";
CM_ SG_ 2449149952 DSC_Equipment_Assigned_Message_ID "canboat type: UINT16";
CM_ SG_ 2449149952 field488 "canboat type: NUMBER";
CM_ SG_ 2583367936 Message_ID "canboat type: LOOKUP";
CM_ SG_ 2583367936 Repeat_Indicator "canboat type: LOOKUP";
CM_ SG_ 2583367936 User_ID "canboat type: MMSI";
CM_ SG_ 2583367936 Name "canboat type: STRING_FIX";
CM_ SG_ 2583367936 AIS_Transceiver_information "canboat type: LOOKUP";
CM_ SG_ 2583367936 Sequence_ID "canboat type: UINT8";
CM_ SG_ 2583368192 Message_ID "canboat type: LOOKUP";
CM_ SG_ 2583368192 Repeat_Indicator "canboat type: LOOKUP";
CM_ SG_ 2583368192 User_ID "canboat type: MMSI";
CM_ SG_ 2583368192 Type_of_ship "canboat type: LOOKUP";
CM_ SG_ 2583368192 Vendor_ID "canboat type: STRING_FIX";
CM_ SG_ 2583368192 Callsign "canboat type: STRING_FIX";
CM_ SG_ 2583368192 Length "canboat type: LENGTH_UFIX16_DM";
CM_ SG_ 2583368192 Beam "canboat type: LENGTH_UFIX16_DM";
CM_ SG_ 2583368192 Position_reference_from_Starboard "canboat type: LENGTH_UFIX16_DM";
CM_ SG_ 2583368192 Position_reference_from_Bow "canboat type: LENGTH_UFIX16_DM";
CM_ SG_ 2583368192 Mothership_User_ID "canboat type: MMSI";
CM_ SG_ 2583368192 Spare "canboat type: SPARE";
CM_ SG_ 2583368192 GNSS_type "canboat type: LOOKUP";
CM_ SG_ 2583368192 AIS_Transceiver_information "canboat type: LOOKUP";
CM_ SG_ 2583368192 Sequence_ID "canboat type: UINT8";
CM_ SG_ 2583368448 Sequence_ID "canboat type: UINT8";
CM_ SG_ 2583368448 Message_ID "canboat type: LOOKUP";
CM_ SG_ 2583368448 Repeat_Indicator "canboat type: LOOKUP";
CM_ SG_ 2583368448 Source_ID "canboat type: MMSI";
CM_ SG_ 2583368448 Destination_Indicator "canboat type: LOOKUP";
CM_ SG_ 2583368448 Binary_data_flag "canboat type: UNSIGNED_INTEGER";
CM_ SG_ 2583368448 Spare "canboat type: SPARE";
CM_ SG_ 2583368448 AIS_Transceiver_information "canboat type: LOOKUP";
CM_ SG_ 2583368448 Destination_ID "canboat type: MMSI";
CM_ SG_ 2583368448 Number_of_bits_in_Binary_Data_Field "canboat type: UINT16";
CM_ SG_ 2583368448 Binary_Data "canboat type: BINARY";
CM_ SG_ 2583368704 Sequence_ID "canboat type: UINT8";
CM_ SG_ 2583368704 Message_ID "canboat type: LOOKUP";
CM_ SG_ 2583368704 Repeat_Indicator "canboat type: LOOKUP";
CM_ SG_ 2583368704 Source_ID "canboat type: MMSI";
CM_ SG_ 2583368704 Destination_Indicator "canboat type: LOOKUP";
CM_ SG_ 2583368704 Binary_data_flag "canboat type: UNSIGNED_INTEGER";
CM_ SG_ 2583368704 AIS_Transceiver_information "canboat type: LOOKUP";
CM_ SG_ 2583368704 Destination_ID "canboat type: MMSI";
CM_ SG_ 2583368704 Spare "canboat type: SPARE";
CM_ SG_ 2583368704 Communication_state_selector_flag "canboat type: UNSIGNED_INTEGER";
CM_ SG_ 2583368704 Communication_State "canboat type: BINARY";
CM_ SG_ 2583368704 Spare_1 "canboat type: SPARE";
CM_ SG_ 2583368704 field120 "canboat type: NUMBER";
CM_ SG_ 2583368960 Sequence_ID "canboat type: UINT8";
CM_ SG_ 2583368960 Message_ID "canboat type: LOOKUP";
CM_ SG_ 2583368960 Repeat_Indicator "canboat type: LOOKUP";
CM_ SG_ 2583368960 User_ID "canboat type: MMSI";
CM_ SG_ 2583368960 Longitude "canboat type: GEO_LON_FIX32";
CM_ SG_ 2583368960 Latitude "canboat type: GEO_LAT_FIX32";
CM_ SG_ 2583368960 Position_Accuracy "canboat type: LOOKUP";
CM_ SG_ 2583368960 RAIM "canboat type: LOOKUP";
CM_ SG_ 2583368960 Nav_Status "canboat type: LOOKUP";
CM_ SG_ 2583368960 Position_Latency "canboat type: UNSIGNED_INTEGER";
CM_ SG_ 2583368960 Spare "canboat type: SPARE";
CM_ SG_ 2583368960 SOG "canboat type: SPEED_UFIX16_CM";
CM_ SG_ 2583368960 COG "canboat type: ANGLE_UFIX16";
CM_ SG_ 2583368960 AIS_Transceiver_information "canboat type: LOOKUP";
CM_ SG_ 2583369216 Sequence_ID "canboat type: UINT8";
CM_ SG_ 2583369216 Message_ID "canboat type: LOOKUP";
CM_ SG_ 2583369216 Repeat_Indicator "canboat type: LOOKUP";
CM_ SG_ 2583369216 Source_ID "canboat type: MMSI";
CM_ SG_ 2583369216 Destination_Indicator "canboat type: LOOKUP";
CM_ SG_ 2583369216 Binary_data_flag "canboat type: UNSIGNED_INTEGER";
CM_ SG_ 2583369216 Spare "canboat type: SPARE";
CM_ SG_ 2583369216 AIS_Transceiver_information "canboat type: LOOKUP";
CM_ SG_ 2583369216 Destination_ID "canboat type: MMSI";
CM_ SG_ 2583369216 Number_of_bits_in_Binary_Data_Field "canboat type: UINT16";
CM_ SG_ 2583369216 Binary_Data "canboat type: BINARY";
CM_ SG_ 2583369472 Sequence_ID "canboat type: UINT8";
CM_ SG_ 2583369472 Message_ID "canboat type: LOOKUP";
CM_ SG_ 2583369472 Repeat_Indicator "canboat type: LOOKUP";
CM_ SG_ 2583369472 Source_ID "canboat type: MMSI";
CM_ SG_ 2583369472 Destination_Indicator "canboat type: LOOKUP";
CM_ SG_ 2583369472 Binary_data_flag "canboat type: UNSIGNED_INTEGER";
CM_ SG_ 2583369472 Destination_ID "canboat type: MMSI";
CM_ SG_ 2583369472 Spare "canboat type: SPARE";
CM_ SG_ 2583369472 Communication_state_selector_flag "canboat type: UNSIGNED_INTEGER";
CM_ SG_ 2583369472 Communication_State "canboat type: BINARY";
CM_ SG_ 2583369472 Spare_1 "canboat type: SPARE";
CM_ SG_ 2583369472 AIS_Transceiver_information "canboat type: LOOKUP";
CM_ SG_ 2583369472 Number_of_Bits_in_Binary_Data_Field "canboat type: UINT16";
CM_ SG_ 2583369472 Binary_Data "canboat type: BINARY";
CM_ SG_ 2583369728 Sequence_ID "canboat type: UINT8";
CM_ SG_ 2583369728 Message_ID "canboat type: LOOKUP";
CM_ SG_ 2583369728 Repeat_Indicator "canboat type: LOOKUP";
CM_ SG_ 2583369728 Source_ID "canboat type: MMSI";
CM_ SG_ 2583369728 AIS_Transceiver_information "canboat type: LOOKUP";
CM_ SG_ 2583369728 Spare "canboat type: SPARE";
CM_ SG_ 2583369728 Number_of_Acknowledgments "canboat type: UINT8";
CM_ SG_ 2583369728 field64 "canboat type: NUMBER";
CM_ SG_ 2382103552 Group_Repetition_Interval__GRI_ "canboat type: DURATION_FIX32_NANO_S";
CM_ SG_ 2382103552 Master_Range "canboat type: DURATION_FIX32_NANO_S";
CM_ SG_ 2382103552 V_Secondary_TD "canboat type: DURATION_FIX32_NANO_S";
CM_ SG_ 2382103552 W_Secondary_TD "canboat type: DURATION_FIX32_NANO_S";
CM_ SG_ 2382103552 X_Secondary_TD "canboat type: DURATION_FIX32_NANO_S";
CM_ SG_ 2382103552 Y_Secondary_TD "canboat type: DURATION_FIX32_NANO_S";
CM_ SG_ 2382103552 Z_Secondary_TD "canboat type: DURATION_FIX32_NANO_S";
CM_ SG_ 2382103552 Station_status__Master "canboat type: BITLOOKUP";
CM_ SG_ 2382103552 Station_status__V "canboat type: BITLOOKUP";
CM_ SG_ 2382103552 Station_status__W "canboat type: BITLOOKUP";
CM_ SG_ 2382103552 Station_status__X "canboat type: BITLOOKUP";
CM_ SG_ 2382103552 Station_status__Y "canboat type: BITLOOKUP";
CM_ SG_ 2382103552 Station_status__Z "canboat type: BITLOOKUP";
CM_ SG_ 2382103552 Mode "canboat type: LOOKUP";
CM_ SG_ 2382103808 Group_Repetition_Interval__GRI_ "canboat type: DURATION_FIX32_NANO_S";
CM_ SG_ 2382103808 Master_Range "canboat type: DURATION_FIX32_NANO_S";
CM_ SG_ 2382103808 V_Secondary_Range "canboat type: DURATION_FIX32_NANO_S";
CM_ SG_ 2382103808 W_Secondary_Range "canboat type: DURATION_FIX32_NANO_S";
CM_ SG_ 2382103808 X_Secondary_Range "canboat type: DURATION_FIX32_NANO_S";
CM_ SG_ 2382103808 Y_Secondary_Range "canboat type: DURATION_FIX32_NANO_S";
CM_ SG_ 2382103808 Z_Secondary_Range "canboat type: DURATION_FIX32_NANO_S";
CM_ SG_ 2382103808 Station_status__Master "canboat type: BITLOOKUP";
CM_ SG_ 2382103808 Station_status__V "canboat type: BITLOOKUP";
CM_ SG_ 2382103808 Station_status__W "canboat type: BITLOOKUP";
CM_ SG_ 2382103808 Station_status__X "canboat type: BITLOOKUP";
CM_ SG_ 2382103808 Station_status__Y "canboat type: BITLOOKUP";
CM_ SG_ 2382103808 Station_status__Z "canboat type: BITLOOKUP";
CM_ SG_ 2382103808 Mode "canboat type: LOOKUP";
CM_ SG_ 2382104064 Group_Repetition_Interval__GRI_ "canboat type: DURATION_FIX32_NANO_S";
CM_ SG_ 2382104064 Station_identifier "canboat type: STRING_FIX";
CM_ SG_ 2382104064 Station_SNR "canboat type: SIGNALTONOISERATIO_FIX16";
CM_ SG_ 2382104064 Station_ECD "canboat type: DURATION_FIX32_NANO_S";
CM_ SG_ 2382104064 Station_ASF "canboat type: DURATION_FIX32_NANO_S";
CM_ SG_ 2583432192 Hardware_Channel_ID "canboat type: UINT8";
CM_ SG_ 2583432192 PGN "canboat type: PGN";
CM_ SG_ 2583432192 Data_Source_Instance_Field_Number "canboat type: UINT8";
CM_ SG_ 2583432192 Data_Source_Instance_Value "canboat type: UINT8";
CM_ SG_ 2583432192 Secondary_Enumeration_Field_Number "canboat type: UINT8";
CM_ SG_ 2583432192 Secondary_Enumeration_Field_Value "canboat type: UINT8";
CM_ SG_ 2583432192 Parameter_Field_Number "canboat type: UINT8";
CM_ SG_ 2583432192 Label "canboat type: STRING_LAU";
CM_ SG_ 2583432448 Data_Source_Channel_ID "canboat type: UINT8";
CM_ SG_ 2583432448 Source_Selection_Status "canboat type: UNSIGNED_INTEGER";
CM_ SG_ 2583432448 NAME_Selection_Criteria_Mask "canboat type: BINARY";
CM_ SG_ 2583432448 Source_NAME "canboat type: ISO_NAME";
CM_ SG_ 2583432448 PGN "canboat type: PGN";
CM_ SG_ 2583432448 Data_Source_Instance_Field_Number "canboat type: UINT8";
CM_ SG_ 2583432448 Data_Source_Instance_Value "canboat type: UINT8";
CM_ SG_ 2583432448 Secondary_Enumeration_Field_Number "canboat type: UINT8";
CM_ SG_ 2583432448 Secondary_Enumeration_Field_Value "canboat type: UINT8";
CM_ SG_ 2583432448 Parameter_Field_Number "canboat type: UINT8";
CM_ SG_ 2650542080 Start_Database_ID "canboat type: UINT16";
CM_ SG_ 2650542080 nItems "canboat type: UINT16";
CM_ SG_ 2650542080 Number_of_Databases_Available "canboat type: UINT16";
CM_ SG_ 2650542080 field48 "canboat type: NUMBER";
CM_ SG_ 2650542336 Start_Route_ID "canboat type: UINT16";
CM_ SG_ 2650542336 nItems "canboat type: UINT16";
CM_ SG_ 2650542336 Number_of_Routes_in_Database "canboat type: UINT16";
CM_ SG_ 2650542336 Database_ID "canboat type: UINT16";
CM_ SG_ 2650542336 field64 "canboat type: NUMBER";
CM_ SG_ 2650542592 Database_ID "canboat type: UINT16";
CM_ SG_ 2650542592 Route_ID "canboat type: UINT16";
CM_ SG_ 2650542592 Route_WP_List_Name "canboat type: STRING_LAU";
CM_ SG_ 2650542592 Route_WP_List_Timestamp "Seconds since midnight; canboat type: TIME";
CM_ SG_ 2650542592 Route_WP_List_Datestamp "canboat type: DATE";
CM_ SG_ 2650542592 Change_at_Last_Timestamp "canboat type: BITLOOKUP";
CM_ SG_ 2650542592 Number_of_WPs_in_the_Route_WP_List "canboat type: UINT16";
CM_ SG_ 2650542592 Critical_supplementary_parameters "canboat type: BITLOOKUP";
CM_ SG_ 2650542592 Navigation_Method "canboat type: LOOKUP";
CM_ SG_ 2650542592 WP_Identification_Method "canboat type: LOOKUP";
CM_ SG_ 2650542592 Route_Status "canboat type: LOOKUP";
CM_ SG_ 2650542592 XTE_Limit_for_the_Route "canboat type: DISTANCE_FIX16_M";
CM_ SG_ 2650542848 Start_RPS_ "canboat type: UINT16";
CM_ SG_ 2650542848 nItems "canboat type: UINT16";
CM_ SG_ 2650542848 Number_of_WPs_in_the_Route_WP_List "canboat type: UINT16";
CM_ SG_ 2650542848 Database_ID "canboat type: UINT16";
CM_ SG_ 2650542848 Route_ID "canboat type: UINT16";
CM_ SG_ 2650542848 field80 "canboat type: NUMBER";
CM_ SG_ 2650543104 Start_RPS_ "canboat type: UINT16";
CM_ SG_ 2650543104 nItems "canboat type: UINT16";
CM_ SG_ 2650543104 Number_of_WPs_in_the_Route_WP_List "canboat type: UINT16";
CM_ SG_ 2650543104 Database_ID "canboat type: UINT16";
CM_ SG_ 2650543104 Route_ID "canboat type: UINT16";
CM_ SG_ 2650543104 field80 "canboat type: NUMBER";
CM_ SG_ 2650543360 Start_RPS_ "canboat type: UINT16";
CM_ SG_ 2650543360 nItems "canboat type: UINT16";
CM_ SG_ 2650543360 Number_of_WPs_with_a_specific_XTE_Limit_or_Nav__Method "canboat type: UINT16";
CM_ SG_ 2650543360 field48 "canboat type: NUMBER";
CM_ SG_ 2650543616 Start_ID "canboat type: UINT16";
CM_ SG_ 2650543616 nItems "canboat type: UINT16";
CM_ SG_ 2650543616 Number_of_WPs_with_Comments "canboat type: UINT16";
CM_ SG_ 2650543616 Database_ID "canboat type: UINT16";
CM_ SG_ 2650543616 Route_ID "canboat type: UINT16";
CM_ SG_ 2650543616 field80 "canboat type: NUMBER";
CM_ SG_ 2650543872 Start_Route_ID "canboat type: UINT16";
CM_ SG_ 2650543872 nItems "canboat type: UINT16";
CM_ SG_ 2650543872 Number_of_Routes_with_Comments "canboat type: UINT16";
CM_ SG_ 2650543872 Database_ID "canboat type: UINT16";
CM_ SG_ 2650543872 field64 "canboat type: NUMBER";
CM_ SG_ 2650544128 Start_Database_ID "canboat type: UINT16";
CM_ SG_ 2650544128 nItems "canboat type: UINT16";
CM_ SG_ 2650544128 Number_of_Databases_with_Comments "canboat type: UINT16";
CM_ SG_ 2650544128 field48 "canboat type: NUMBER";
CM_ SG_ 2650544384 Start_RPS_ "canboat type: UINT16";
CM_ SG_ 2650544384 nItems "canboat type: UINT16";
CM_ SG_ 2650544384 Number_of_WPs_with_a_specific_Radius_of_Turn "canboat type: UINT16";
CM_ SG_ 2650544384 Database_ID "canboat type: UINT16";
CM_ SG_ 2650544384 Route_ID "canboat type: UINT16";
CM_ SG_ 2650544384 field80 "canboat type: NUMBER";
CM_ SG_ 2650544640 Start_WP_ID "canboat type: UINT16";
CM_ SG_ 2650544640 nItems "canboat type: UINT16";
CM_ SG_ 2650544640 Number_of_valid_WPs_in_the_WP_List "canboat type: UINT16";
CM_ SG_ 2650544640 Database_ID "canboat type: UINT16";
CM_ SG_ 2650544640 field80 "canboat type: NUMBER";
CM_ SG_ 2315059712 SID "canboat type: UINT8";
CM_ SG_ 2315059712 Wind_Speed "canboat type: SPEED_UFIX16_CM";
CM_ SG_ 2315059712 Wind_Angle "canboat type: ANGLE_UFIX16";
CM_ SG_ 2315059712 Reference "canboat type: LOOKUP";
CM_ SG_ 2516387328 SID "canboat type: UINT8";
CM_ SG_ 2516387328 Water_Temperature "canboat type: TEMPERATURE";
CM_ SG_ 2516387328 Outside_Ambient_Air_Temperature "canboat type: TEMPERATURE";
CM_ SG_ 2516387328 Atmospheric_Pressure "canboat type: PRESSURE_UFIX16_HPA";
CM_ SG_ 2516387584 SID "canboat type: UINT8";
CM_ SG_ 2516387584 Temperature_Source "canboat type: LOOKUP";
CM_ SG_ 2516387584 Humidity_Source "canboat type: LOOKUP";
CM_ SG_ 2516387584 Temperature "canboat type: TEMPERATURE";
CM_ SG_ 2516387584 Humidity "canboat type: PERCENTAGE_FIX16";
CM_ SG_ 2516387584 Atmospheric_Pressure "canboat type: PRESSURE_UFIX16_HPA";
CM_ SG_ 2516387840 SID "canboat type: UINT8";
CM_ SG_ 2516387840 Instance "canboat type: UINT8";
CM_ SG_ 2516387840 Source "canboat type: LOOKUP";
CM_ SG_ 2516387840 Actual_Temperature "canboat type: TEMPERATURE";
CM_ SG_ 2516387840 Set_Temperature "canboat type: TEMPERATURE";
CM_ SG_ 2516388096 SID "canboat type: UINT8";
CM_ SG_ 2516388096 Instance "canboat type: UINT8";
CM_ SG_ 2516388096 Source "canboat type: LOOKUP";
CM_ SG_ 2516388096 Actual_Humidity "canboat type: PERCENTAGE_FIX16";
CM_ SG_ 2516388096 Set_Humidity "canboat type: PERCENTAGE_FIX16";
CM_ SG_ 2516388352 SID "canboat type: UINT8";
CM_ SG_ 2516388352 Instance "canboat type: UINT8";
CM_ SG_ 2516388352 Source "canboat type: LOOKUP";
CM_ SG_ 2516388352 Pressure "canboat type: PRESSURE_FIX32_DPA";
CM_ SG_ 2516388608 SID "canboat type: UINT8";
CM_ SG_ 2516388608 Instance "canboat type: UINT8";
CM_ SG_ 2516388608 Source "canboat type: LOOKUP";
CM_ SG_ 2516388608 Pressure "canboat type: PRESSURE_FIX32_DPA";
CM_ SG_ 2516388864 SID "canboat type: UINT8";
CM_ SG_ 2516388864 Instance "canboat type: UINT8";
CM_ SG_ 2516388864 Source "canboat type: LOOKUP";
CM_ SG_ 2516388864 Temperature "canboat type: TEMPERATURE_UFIX24";
CM_ SG_ 2516388864 Set_Temperature "canboat type: TEMPERATURE_HIGH";
CM_ SG_ 2583498752 Mode "canboat type: LOOKUP";
CM_ SG_ 2583498752 Tide_Tendency "canboat type: LOOKUP";
CM_ SG_ 2583498752 Measurement_Date "canboat type: DATE";
CM_ SG_ 2583498752 Measurement_Time "Seconds since midnight; canboat type: TIME";
CM_ SG_ 2583498752 Station_Latitude "canboat type: GEO_LAT_FIX32";
CM_ SG_ 2583498752 Station_Longitude "canboat type: GEO_LON_FIX32";
CM_ SG_ 2583498752 Tide_Level "Relative to MLLW; canboat type: DISTANCE_FIX16_MM";
CM_ SG_ 2583498752 Tide_Level_standard_deviation "canboat type: LENGTH_UFIX16_CM";
CM_ SG_ 2583498752 Station_ID "canboat type: STRING_LAU";
CM_ SG_ 2583498752 Station_Name "canboat type: STRING_LAU";
CM_ SG_ 2583499008 Mode "canboat type: LOOKUP";
CM_ SG_ 2583499008 Measurement_Date "canboat type: DATE";
CM_ SG_ 2583499008 Measurement_Time "Seconds since midnight; canboat type: TIME";
CM_ SG_ 2583499008 Station_Latitude "canboat type: GEO_LAT_FIX32";
CM_ SG_ 2583499008 Station_Longitude "canboat type: GEO_LON_FIX32";
CM_ SG_ 2583499008 Salinity "canboat type: FLOAT_PPT";
CM_ SG_ 2583499008 Water_Temperature "canboat type: TEMPERATURE";
CM_ SG_ 2583499008 Station_ID "canboat type: STRING_LAU";
CM_ SG_ 2583499008 Station_Name "canboat type: STRING_LAU";
CM_ SG_ 2583499264 Mode "canboat type: LOOKUP";
CM_ SG_ 2583499264 State "canboat type: LOOKUP";
CM_ SG_ 2583499264 Measurement_Date "canboat type: DATE";
CM_ SG_ 2583499264 Measurement_Time "Seconds since midnight; canboat type: TIME";
CM_ SG_ 2583499264 Station_Latitude "canboat type: GEO_LAT_FIX32";
CM_ SG_ 2583499264 Station_Longitude "canboat type: GEO_LON_FIX32";
CM_ SG_ 2583499264 Measurement_Depth "Depth below transducer; canboat type: LENGTH_UFIX32_CM";
CM_ SG_ 2583499264 Current_speed "canboat type: SPEED_UFIX16_CM";
CM_ SG_ 2583499264 Current_flow_direction "canboat type: ANGLE_UFIX16";
CM_ SG_ 2583499264 Water_Temperature "canboat type: TEMPERATURE";
CM_ SG_ 2583499264 Station_ID "canboat type: STRING_LAU";
CM_ SG_ 2583499264 Station_Name "canboat type: STRING_LAU";
CM_ SG_ 2583499520 Mode "canboat type: LOOKUP";
CM_ SG_ 2583499520 Measurement_Date "canboat type: DATE";
CM_ SG_ 2583499520 Measurement_Time "Seconds since midnight; canboat type: TIME";
CM_ SG_ 2583499520 Station_Latitude "canboat type: GEO_LAT_FIX32";
CM_ SG_ 2583499520 Station_Longitude "canboat type: GEO_LON_FIX32";
CM_ SG_ 2583499520 Wind_Speed "canboat type: SPEED_UFIX16_CM";
CM_ SG_ 2583499520 Wind_Direction "canboat type: ANGLE_UFIX16";
CM_ SG_ 2583499520 Wind_Reference "canboat type: LOOKUP";
CM_ SG_ 2583499520 Wind_Gusts "canboat type: SPEED_UFIX16_CM";
CM_ SG_ 2583499520 Atmospheric_Pressure "canboat type: PRESSURE_UFIX16_HPA";
CM_ SG_ 2583499520 Ambient_Temperature "canboat type: TEMPERATURE";
CM_ SG_ 2583499520 Station_ID "canboat type: STRING_LAU";
CM_ SG_ 2583499520 Station_Name "canboat type: STRING_LAU";
CM_ SG_ 2583499776 Mode "canboat type: LOOKUP";
CM_ SG_ 2583499776 Measurement_Date "canboat type: DATE";
CM_ SG_ 2583499776 Measurement_Time "Seconds since midnight; canboat type: TIME";
CM_ SG_ 2583499776 Station_Latitude "canboat type: GEO_LAT_FIX32";
CM_ SG_ 2583499776 Station_Longitude "canboat type: GEO_LON_FIX32";
CM_ SG_ 2583499776 Wind_Speed "canboat type: SPEED_UFIX16_CM";
CM_ SG_ 2583499776 Wind_Direction "canboat type: ANGLE_UFIX16";
CM_ SG_ 2583499776 Wind_Reference "canboat type: LOOKUP";
CM_ SG_ 2583499776 Wind_Gusts "canboat type: SPEED_UFIX16_CM";
CM_ SG_ 2583499776 Wave_Height "canboat type: LENGTH_UFIX16_CM";
CM_ SG_ 2583499776 Dominant_Wave_Period "canboat type: DURATION_UFIX16_CS";
CM_ SG_ 2583499776 Atmospheric_Pressure "canboat type: PRESSURE_UFIX16_HPA";
CM_ SG_ 2583499776 Pressure_Tendency_Rate "canboat type: PRESSURE_RATE_FIX16_PA";
CM_ SG_ 2583499776 Air_Temperature "canboat type: TEMPERATURE";
CM_ SG_ 2583499776 Water_Temperature "canboat type: TEMPERATURE";
CM_ SG_ 2583499776 Station_ID "canboat type: STRING_LAU";
CM_ SG_ 2583501056 HVAC_Identifier "canboat type: UINT8";
CM_ SG_ 2583501056 Location "canboat type: UINT8";
CM_ SG_ 2583501056 Operating_Mode "canboat type: UNSIGNED_INTEGER";
CM_ SG_ 2583501056 Control_Operating_State "canboat type: UNSIGNED_INTEGER";
CM_ SG_ 2583501056 Power "canboat type: LOOKUP";
CM_ SG_ 2583501056 Fan_Speed_Mode_Changeable "canboat type: UNSIGNED_INTEGER";
CM_ SG_ 2583501056 Fan_Speed_Mode "canboat type: UNSIGNED_INTEGER";
CM_ SG_ 2583501056 Fan_Operation_Mode "canboat type: UNSIGNED_INTEGER";
CM_ SG_ 2583501056 Fan_Speed_Available "canboat type: UINT8";
CM_ SG_ 2583501056 Fan_Speed "canboat type: UINT8";
CM_ SG_ 2583501056 Setpoint_Type "canboat type: UINT8";
CM_ SG_ 2583501056 Lower_Temperature_Setpoint "canboat type: TEMPERATURE";
CM_ SG_ 2583501056 Upper_Temperature_Setpoint "canboat type: TEMPERATURE";
CM_ SG_ 2583501056 Lower_Humidity_Setpoint "canboat type: INT8";
CM_ SG_ 2583501056 Upper_Humidity_Setpoint "canboat type: INT8";
CM_ SG_ 2583501056 Auxiliary_Heat_Control_Supported "canboat type: UNSIGNED_INTEGER";
CM_ SG_ 2583501056 Auxiliary_Heat_Automatic_Mode "canboat type: UNSIGNED_INTEGER";
CM_ SG_ 2583501056 Auxiliary_Heat_State "canboat type: UNSIGNED_INTEGER";
CM_ SG_ 2583501056 Current_Temperature "canboat type: TEMPERATURE";
CM_ SG_ 2583501056 Current_Humidity "canboat type: INT8";
CM_ SG_ 2583501056 Supported_Modes "canboat type: UINT16";
CM_ SG_ 2583501056 Sea_Water_Temperature "canboat type: TEMPERATURE";
CM_ SG_ 2583501056 Loop_Temperature "canboat type: TEMPERATURE";
CM_ SG_ 2583501056 Evaporator_Temperature "canboat type: TEMPERATURE";
CM_ SG_ 2583501056 Inlet_Temperature "canboat type: TEMPERATURE";
CM_ SG_ 2583501056 Inlet_Humidity "canboat type: INT8";
CM_ SG_ 2650610176 Global_Enable "canboat type: UNSIGNED_INTEGER";
CM_ SG_ 2650610176 Default_Settings_Command "canboat type: LOOKUP";
CM_ SG_ 2650610176 Name_of_the_lighting_controller "canboat type: STRING_LAU";
CM_ SG_ 2650610176 Max_Scenes "canboat type: UINT8";
CM_ SG_ 2650610176 Max_Scene_Configuration_Count "canboat type: UINT8";
CM_ SG_ 2650610176 Max_Zones "canboat type: UINT8";
CM_ SG_ 2650610176 Max_Color_Sequences "canboat type: UINT8";
CM_ SG_ 2650610176 Max_Color_Sequence_Color_Count "canboat type: UINT8";
CM_ SG_ 2650610176 Number_of_Programs "canboat type: UINT8";
CM_ SG_ 2650610176 Controller_Capabilities "canboat type: UINT8";
CM_ SG_ 2650610176 Identify_Device "canboat type: UINT32";
CM_ SG_ 2583560192 SID "canboat type: UINT8";
CM_ SG_ 2583560192 Measurement_Status "canboat type: UNSIGNED_INTEGER";
CM_ SG_ 2583560192 Measurement_ID "canboat type: UINT8";
CM_ SG_ 2583560192 Payload_Mass "canboat type: UINT32";
CM_ SG_ 2583560448 Zone_Index "canboat type: UINT8";
CM_ SG_ 2583560448 Zone_Name "canboat type: STRING_LAU";
CM_ SG_ 2583560448 Red_Component "canboat type: UINT8";
CM_ SG_ 2583560448 Green_Component "canboat type: UINT8";
CM_ SG_ 2583560448 Blue_Component "canboat type: UINT8";
CM_ SG_ 2583560448 Color_Temperature "canboat type: UINT16";
CM_ SG_ 2583560448 Intensity "canboat type: UINT8";
CM_ SG_ 2583560448 Program_ID "canboat type: UINT8";
CM_ SG_ 2583560448 Program_Color_Sequence_Index "canboat type: UINT8";
CM_ SG_ 2583560448 Program_Intensity "canboat type: UINT8";
CM_ SG_ 2583560448 Program_Rate "canboat type: UINT8";
CM_ SG_ 2583560448 Program_Color_Sequence "canboat type: UINT8";
CM_ SG_ 2583560448 Zone_Enabled "canboat type: LOOKUP";
CM_ SG_ 2583560704 Scene_Index "canboat type: UINT8";
CM_ SG_ 2583560704 Zone_Name "canboat type: STRING_LAU";
CM_ SG_ 2583560704 Control "canboat type: UINT8";
CM_ SG_ 2583560704 Configuration_Count "canboat type: UINT8";
CM_ SG_ 2583560704 field32 "canboat type: NUMBER";
CM_ SG_ 2583560960 Device_ID "canboat type: UINT32";
CM_ SG_ 2583560960 Device_Capabilities "canboat type: UINT8";
CM_ SG_ 2583560960 Color_Capabilities "canboat type: UINT8";
CM_ SG_ 2583560960 Zone_Index "canboat type: UINT8";
CM_ SG_ 2583560960 Name_of_Lighting_Device "canboat type: STRING_LAU";
CM_ SG_ 2583560960 Status "canboat type: UINT8";
CM_ SG_ 2583560960 Red_Component "canboat type: UINT8";
CM_ SG_ 2583560960 Green_Component "canboat type: UINT8";
CM_ SG_ 2583560960 Blue_Component "canboat type: UINT8";
CM_ SG_ 2583560960 Color_Temperature "canboat type: UINT16";
CM_ SG_ 2583560960 Intensity "canboat type: UINT8";
CM_ SG_ 2583560960 Program_ID "canboat type: UINT8";
CM_ SG_ 2583560960 Program_Color_Sequence_Index "canboat type: UINT8";
CM_ SG_ 2583560960 Program_Intensity "canboat type: UINT8";
CM_ SG_ 2583560960 Program_Rate "canboat type: UINT8";
CM_ SG_ 2583560960 Program_Color_Sequence_Rate "canboat type: UINT8";
CM_ SG_ 2583560960 Enabled "canboat type: LOOKUP";
CM_ SG_ 2583561216 Index_of_First_Device "canboat type: UINT16";
CM_ SG_ 2583561216 Total_Number_of_Devices "canboat type: UINT16";
CM_ SG_ 2583561216 Number_of_Devices "canboat type: UINT16";
CM_ SG_ 2583561216 field48 "canboat type: NUMBER";
CM_ SG_ 2583561472 Sequence_Index "canboat type: UINT8";
CM_ SG_ 2583561472 Color_Count "canboat type: UINT8";
CM_ SG_ 2583561472 field16 "canboat type: NUMBER";
CM_ SG_ 2583561728 Program_ID "canboat type: UINT8";
CM_ SG_ 2583561728 Name_of_Program "canboat type: STRING_LAU";
CM_ SG_ 2583561728 Description "canboat type: STRING_LAU";
CM_ SG_ 2583561728 Program_Capabilities "canboat type: UNSIGNED_INTEGER";
CM_ SG_ 2583561984 Watermaker_Operating_State "canboat type: LOOKUP";
CM_ SG_ 2583561984 Production_Start_Stop "canboat type: LOOKUP";
CM_ SG_ 2583561984 Rinse_Start_Stop "canboat type: LOOKUP";
CM_ SG_ 2583561984 Low_Pressure_Pump_Status "canboat type: LOOKUP";
CM_ SG_ 2583561984 High_Pressure_Pump_Status "canboat type: LOOKUP";
CM_ SG_ 2583561984 Emergency_Stop "canboat type: LOOKUP";
CM_ SG_ 2583561984 Product_Solenoid_Valve_Status "canboat type: LOOKUP";
CM_ SG_ 2583561984 Flush_Mode_Status "canboat type: LOOKUP";
CM_ SG_ 2583561984 Salinity_Status "canboat type: LOOKUP";
CM_ SG_ 2583561984 Sensor_Status "canboat type: LOOKUP";
CM_ SG_ 2583561984 Oil_Change_Indicator_Status "canboat type: LOOKUP";
CM_ SG_ 2583561984 Filter_Status "canboat type: LOOKUP";
CM_ SG_ 2583561984 System_Status "canboat type: LOOKUP";
CM_ SG_ 2583561984 Salinity "canboat type: CONCENTRATION_UINT16_PPM";
CM_ SG_ 2583561984 Product_Water_Temperature "canboat type: TEMPERATURE";
CM_ SG_ 2583561984 Pre_filter_Pressure "canboat type: PRESSURE_UFIX16_HPA";
CM_ SG_ 2583561984 Post_filter_Pressure "canboat type: PRESSURE_UFIX16_HPA";
CM_ SG_ 2583561984 Feed_Pressure "canboat type: PRESSURE_FIX16_KPA";
CM_ SG_ 2583561984 System_High_Pressure "canboat type: PRESSURE_UFIX16_KPA";
CM_ SG_ 2583561984 Product_Water_Flow "canboat type: VOLUMETRIC_FLOW";
CM_ SG_ 2583561984 Brine_Water_Flow "canboat type: VOLUMETRIC_FLOW";
CM_ SG_ 2583561984 Run_Time "canboat type: DURATION_UFIX32_S";
CM_ SG_ 2583562240 Source "canboat type: LOOKUP";
CM_ SG_ 2583562240 Number "Source number per type; canboat type: UINT8";
CM_ SG_ 2583562240 Diagnostic_Mode "canboat type: UINT8";
CM_ SG_ 2583562240 Diagnostic_Data "canboat type: STRING_LAU";
CM_ SG_ 2583562496 Zone "canboat type: LOOKUP";
CM_ SG_ 2583562496 Source "canboat type: LOOKUP";
CM_ SG_ 2583562496 Number "Source number per type; canboat type: UINT8";
CM_ SG_ 2583562496 ID "Unique file ID; canboat type: UINT32";
CM_ SG_ 2583562496 Play_status "canboat type: LOOKUP";
CM_ SG_ 2583562496 Elapsed_Track_Time "canboat type: DURATION_UFIX16_S";
CM_ SG_ 2583562496 Track_Time "canboat type: DURATION_UFIX16_S";
CM_ SG_ 2583562496 Repeat_Status "canboat type: LOOKUP";
CM_ SG_ 2583562496 Shuffle_Status "canboat type: LOOKUP";
CM_ SG_ 2583562496 Save_Favorite_Number "Used to command AV to save current station as favorite; canboat type: UINT8";
CM_ SG_ 2583562496 Play_Favorite_Number "Used to command AV to play indicated favorite station; canboat type: UINT16";
CM_ SG_ 2583562496 Thumbs_Up_Down "canboat type: LOOKUP";
CM_ SG_ 2583562496 Signal_Strength "canboat type: PERCENTAGE_UINT8";
CM_ SG_ 2583562496 Radio_Frequency "canboat type: RADIO_FREQUENCY_UFIX32";
CM_ SG_ 2583562496 HD_Frequency_Multicast "Digital sub channel; canboat type: UINT8";
CM_ SG_ 2583562496 Delete_Favorite_Number "Used to command AV to delete current station as favorite; canboat type: UINT8";
CM_ SG_ 2583562496 Total_Number_of_Tracks "canboat type: UINT16";
CM_ SG_ 2583562752 Source "canboat type: LOOKUP";
CM_ SG_ 2583562752 Number "Source number per type; canboat type: UINT8";
CM_ SG_ 2583562752 ID "Unique file ID; canboat type: UINT32";
CM_ SG_ 2583562752 Type "canboat type: LOOKUP";
CM_ SG_ 2583562752 Name "canboat type: STRING_LAU";
CM_ SG_ 2583562752 Track "canboat type: UINT16";
CM_ SG_ 2583562752 Station "canboat type: UINT16";
CM_ SG_ 2583562752 Favorite "canboat type: UINT8";
CM_ SG_ 2583562752 Radio_Frequency "canboat type: RADIO_FREQUENCY_UFIX32";
CM_ SG_ 2583562752 HD_Frequency "canboat type: UINT8";
CM_ SG_ 2583562752 Zone "canboat type: LOOKUP";
CM_ SG_ 2583562752 In_play_queue "canboat type: LOOKUP";
CM_ SG_ 2583562752 Locked "canboat type: LOOKUP";
CM_ SG_ 2583562752 Artist_Name "canboat type: STRING_LAU";
CM_ SG_ 2583562752 Album_Name "canboat type: STRING_LAU";
CM_ SG_ 2583562752 Station_Name "canboat type: STRING_LAU";
CM_ SG_ 2583563008 Source "canboat type: LOOKUP";
CM_ SG_ 2583563008 Number "Source number per type; canboat type: UINT8";
CM_ SG_ 2583563008 Type "canboat type: LOOKUP";
CM_ SG_ 2583563008 Zone "canboat type: LOOKUP";
CM_ SG_ 2583563008 Group_ID "Unique group ID; canboat type: UINT32";
CM_ SG_ 2583563008 ID_offset "First ID in this PGN; canboat type: UINT16";
CM_ SG_ 2583563008 ID_count "Number of IDs in this PGN; canboat type: UINT16";
CM_ SG_ 2583563008 Total_ID_count "Total IDs in group; canboat type: UINT16";
CM_ SG_ 2583563008 field112 "canboat type: NUMBER";
CM_ SG_ 2583563008 Artist "canboat type: STRING_LAU";
CM_ SG_ 2583563264 Source "canboat type: LOOKUP";
CM_ SG_ 2583563264 Number "Source number per type; canboat type: UINT8";
CM_ SG_ 2583563264 Group_ID "Unique group ID; canboat type: UINT32";
CM_ SG_ 2583563264 Group_type_1 "canboat type: LOOKUP";
CM_ SG_ 2583563264 Group_name_1 "canboat type: STRING_LAU";
CM_ SG_ 2583563264 Group_type_2 "canboat type: LOOKUP";
CM_ SG_ 2583563264 Group_name_2 "canboat type: STRING_LAU";
CM_ SG_ 2583563264 Group_type_3 "canboat type: LOOKUP";
CM_ SG_ 2583563264 Group_name_3 "canboat type: STRING_LAU";
CM_ SG_ 2583563520 ID_offset "First ID in this PGN; canboat type: UINT16";
CM_ SG_ 2583563520 ID_count "Number of IDs in this PGN; canboat type: UINT16";
CM_ SG_ 2583563520 Total_ID_count "Total IDs in group; canboat type: UINT16";
CM_ SG_ 2583563520 field48 "canboat type: NUMBER";
CM_ SG_ 2583563776 First_zone_ID "First Zone in this PGN; canboat type: UINT8";
CM_ SG_ 2583563776 Zone_count "Number of Zones in this PGN; canboat type: UINT8";
CM_ SG_ 2583563776 Total_zone_count "Total Zones supported by this device; canboat type: UINT8";
CM_ SG_ 2583563776 field24 "canboat type: NUMBER";
CM_ SG_ 2583564032 Source "canboat type: LOOKUP";
CM_ SG_ 2583564032 Number "Source number per type; canboat type: UINT8";
CM_ SG_ 2583564032 Lock_Type "canboat type: UNSIGNED_INTEGER";
CM_ SG_ 2583564032 Lock_Status "canboat type: UNSIGNED_INTEGER";
CM_ SG_ 2583564032 File___Station_ID "Unique file or station ID; canboat type: UINT32";
CM_ SG_ 2583564032 Current_Pincode "canboat type: STRING_LAU";
CM_ SG_ 2583564032 New_Pincode "canboat type: STRING_LAU";
CM_ SG_ 2315128832 Port_trim_tab "canboat type: PERCENTAGE_INT8";
CM_ SG_ 2315128832 Starboard_trim_tab "canboat type: PERCENTAGE_INT8";
CM_ SG_ 2382237952 Data_Mode "canboat type: LOOKUP";
CM_ SG_ 2382237952 COG_Reference "canboat type: LOOKUP";
CM_ SG_ 2382237952 SID "canboat type: UINT8";
CM_ SG_ 2382237952 COG "canboat type: ANGLE_UFIX16";
CM_ SG_ 2382237952 SOG "canboat type: SPEED_UFIX16_CM";
CM_ SG_ 2382237952 Heading "canboat type: ANGLE_UFIX16";
CM_ SG_ 2382237952 Speed_through_Water "canboat type: SPEED_UFIX16_CM";
CM_ SG_ 2382237952 Set "canboat type: ANGLE_UFIX16";
CM_ SG_ 2382237952 Drift "canboat type: SPEED_UFIX16_CM";
CM_ SG_ 2315129344 Longitudinal_Speed__Water_referenced "canboat type: SPEED_FIX16_MM";
CM_ SG_ 2315129344 Transverse_Speed__Water_referenced "canboat type: SPEED_FIX16_MM";
CM_ SG_ 2315129344 Longitudinal_Speed__Ground_referenced "canboat type: SPEED_FIX16_MM";
CM_ SG_ 2315129344 Transverse_Speed__Ground_referenced "canboat type: SPEED_FIX16_MM";
CM_ SG_ 2315129344 Stern_Speed__Water_referenced "canboat type: SPEED_FIX16_MM";
CM_ SG_ 2315129344 Stern_Speed__Ground_referenced "canboat type: SPEED_FIX16_MM";
CM_ SG_ 2583565056 Power "canboat type: LOOKUP";
CM_ SG_ 2583565056 Default_Settings "canboat type: LOOKUP";
CM_ SG_ 2583565056 Tuner_regions "canboat type: LOOKUP";
CM_ SG_ 2583565056 Max_favorites "canboat type: UINT8";
CM_ SG_ 2583565056 Video_protocols "canboat type: LOOKUP";
CM_ SG_ 2583565312 Power "canboat type: LOOKUP";
CM_ SG_ 2583565312 Default_Settings "canboat type: LOOKUP";
CM_ SG_ 2583565312 Tuner_regions "canboat type: LOOKUP";
CM_ SG_ 2583565312 Max_favorites "canboat type: UINT8";
CM_ SG_ 2583565568 First_zone_ID "First Zone in this PGN; canboat type: UINT8";
CM_ SG_ 2583565568 Zone_count "Number of Zones in this PGN; canboat type: UINT8";
CM_ SG_ 2583565568 Total_zone_count "Total Zones supported by this device; canboat type: UINT8";
CM_ SG_ 2583565568 field24 "canboat type: NUMBER";
CM_ SG_ 2583565824 Zone_ID "canboat type: LOOKUP";
CM_ SG_ 2583565824 Volume "canboat type: PERCENTAGE_UINT8";
CM_ SG_ 2583565824 Volume_change "Write only; canboat type: LOOKUP";
CM_ SG_ 2583565824 Mute "canboat type: LOOKUP";
CM_ SG_ 2583565824 Channel "canboat type: LOOKUP";
CM_ SG_ 2583566080 First_preset "First preset in this PGN; canboat type: UINT8";
CM_ SG_ 2583566080 Preset_count "canboat type: UINT8";
CM_ SG_ 2583566080 Total_preset_count "canboat type: UINT8";
CM_ SG_ 2583566080 field24 "canboat type: NUMBER";
CM_ SG_ 2583566336 First_address "First address in this PGN; canboat type: UINT8";
CM_ SG_ 2583566336 Address_count "canboat type: UINT8";
CM_ SG_ 2583566336 Total_address_count "canboat type: UINT8";
CM_ SG_ 2583566336 field24 "canboat type: NUMBER";
CM_ SG_ 2583566592 Source_number "canboat type: UINT8";
CM_ SG_ 2583566592 Status "canboat type: LOOKUP";
CM_ SG_ 2583566592 Forget_device "canboat type: LOOKUP";
CM_ SG_ 2583566592 Discovering "canboat type: LOOKUP";
CM_ SG_ 2583566592 Bluetooth_address "canboat type: BINARY";
CM_ SG_ 2583566848 Zone_ID "canboat type: LOOKUP";
CM_ SG_ 2583566848 Volume_limit "canboat type: PERCENTAGE_UINT8";
CM_ SG_ 2583566848 Fade "canboat type: PERCENTAGE_INT8";
CM_ SG_ 2583566848 Balance "canboat type: PERCENTAGE_INT8";
CM_ SG_ 2583566848 Sub_volume "canboat type: PERCENTAGE_UINT8";
CM_ SG_ 2583566848 EQ___Treble "canboat type: PERCENTAGE_INT8";
CM_ SG_ 2583566848 EQ___Mid_range "canboat type: PERCENTAGE_INT8";
CM_ SG_ 2583566848 EQ___Bass "canboat type: PERCENTAGE_INT8";
CM_ SG_ 2583566848 Preset_type "canboat type: LOOKUP";
CM_ SG_ 2583566848 Audio_filter "canboat type: LOOKUP";
CM_ SG_ 2583566848 High_pass_filter_frequency "canboat type: FREQUENCY_UFIX16";
CM_ SG_ 2583566848 Low_pass_filter_frequency "canboat type: FREQUENCY_UFIX16";
CM_ SG_ 2583566848 Channel "canboat type: LOOKUP";
CM_ SG_ 2583625728 Manufacturer_Code "canboat type: LOOKUP";
CM_ SG_ 2583625728 Industry_Code "canboat type: LOOKUP";
CM_ SG_ 2583625728 Data "canboat type: BINARY";
CM_ SG_ 2583625728 Manufacturer_Code "BEP Marine; canboat type: LOOKUP";
CM_ SG_ 2583625728 Industry_Code "Marine Industry; canboat type: LOOKUP";
CM_ SG_ 2583625728 Chunk_Index "0-based index of this chunk in the transfer; canboat type: UINT16";
CM_ SG_ 2583625728 Flag "Observed = 0x01; meaning unknown (possibly transfer mode / direction); canboat type: UINT8";
CM_ SG_ 2583625728 Data "Up to 200 bytes of .zcf data; terminator chunk has 0 bytes; canboat type: BINARY";
CM_ SG_ 2583625728 Manufacturer_Code "Honda Motor; canboat type: LOOKUP";
CM_ SG_ 2583625728 Industry_Code "Marine Industry; canboat type: LOOKUP";
CM_ SG_ 2583625728 Manufacturer_Code "Sea Recovery; canboat type: LOOKUP";
CM_ SG_ 2583625728 Industry_Code "Marine Industry; canboat type: LOOKUP";
CM_ SG_ 2583625728 Message_ID "canboat type: UINT8";
CM_ SG_ 2583625728 Watermaker_Instance "canboat type: UNSIGNED_INTEGER";
CM_ SG_ 2583625728 Operation_State "canboat type: UNSIGNED_INTEGER";
CM_ SG_ 2583625728 Prefilter_Pressure "canboat type: UINT16";
CM_ SG_ 2583625728 Postfilter_Pressure "canboat type: UINT16";
CM_ SG_ 2583625728 Operation_Pressure "canboat type: UINT16";
CM_ SG_ 2583625728 Product_Flow "canboat type: INT16";
CM_ SG_ 2583625728 Prefilter_Pressure_Status "canboat type: UNSIGNED_INTEGER";
CM_ SG_ 2583625728 Postfilter_Pressure_Status "canboat type: UNSIGNED_INTEGER";
CM_ SG_ 2583625728 Operation_Pressure_Status "canboat type: UNSIGNED_INTEGER";
CM_ SG_ 2583625728 Product_Salinity_Status "canboat type: UNSIGNED_INTEGER";
CM_ SG_ 2583625728 Filter_Status "canboat type: UNSIGNED_INTEGER";
CM_ SG_ 2583625728 System_Status "canboat type: UNSIGNED_INTEGER";
VAL_ 2650475776 Message_ID 1 "Scheduled Class A position report" 2 "Assigned scheduled Class A position report" 3 "Interrogated Class A position report" 4 "Base station report" 5 "Static and voyage related data" 6 "Binary addressed message" 7 "Binary acknowledgement" 8 "Binary broadcast message" 9 "Standard SAR aircraft position report" 10 "UTC/date inquiry" 11 "UTC/date response" 12 "Safety related addressed message" 13 "Safety related acknowledgement" 14 "Satety related broadcast message" 15 "Interrogation" 16 "Assignment mode command" 17 "DGNSS broadcast binary message" 18 "Standard Class B position report" 19 "Extended Class B position report" 20 "Data link management message" 21 "ATON report" 22 "Channel management" 23 "Group assignment command" 24 "Static data report" 25 "Single slot binary message" 26 "Multiple slot binary message" 27 "Position report for long range applications" ;
VAL_ 2650475776 Repeat_Indicator 0 "Initial" 1 "First retransmission" 2 "Second retransmission" 3 "Final retransmission" ;
VAL_ 2650475776 AIS_Transceiver_information 0 "Channel A VDL reception" 1 "Channel B VDL reception" 2 "Channel A VDL transmission" 3 "Channel B VDL transmission" 4 "Own information not broadcast" 5 "Reserved" ;
VAL_ 2650476032 Message_ID 1 "Scheduled Class A position report" 2 "Assigned scheduled Class A position report" 3 "Interrogated Class A position report" 4 "Base station report" 5 "Static and voyage related data" 6 "Binary addressed message" 7 "Binary acknowledgement" 8 "Binary broadcast message" 9 "Standard SAR aircraft position report" 10 "UTC/date inquiry" 11 "UTC/date response" 12 "Safety related addressed message" 13 "Safety related acknowledgement" 14 "Satety related broadcast message" 15 "Interrogation" 16 "Assignment mode command" 17 "DGNSS broadcast binary message" 18 "Standard Class B position report" 19 "Extended Class B position report" 20 "Data link management message" 21 "ATON report" 22 "Channel management" 23 "Group assignment command" 24 "Static data report" 25 "Single slot binary message" 26 "Multiple slot binary message" 27 "Position report for long range applications" ;
VAL_ 2650476032 Repeat_Indicator 0 "Initial" 1 "First retransmission" 2 "Second retransmission" 3 "Final retransmission" ;
VAL_ 2650476032 AIS_Transceiver_information 0 "Channel A VDL reception" 1 "Channel B VDL reception" 2 "Channel A VDL transmission" 3 "Channel B VDL transmission" 4 "Own information not broadcast" 5 "Reserved" ;
VAL_ 2650476032 Power 0 "High" 1 "Low" ;
VAL_ 2650476032 Tx_Rx_Mode 0 "Tx A/Tx B, Rx A/Rx B" 1 "Tx A, Rx A/Rx B" 2 "Tx B, Rx A/Rx B" ;
VAL_ 2650476032 Addressed_or_Broadcast_Message_Indicator 0 "Broadcast geo area message" 1 "Addressed message" ;
VAL_ 2650476032 Channel_A_Bandwidth 0 "Default" 1 "12.5 kHz" ;
VAL_ 2650476032 Channel_B_Bandwidth 0 "Default" 1 "12.5 kHz" ;
VAL_ 2650476032 Transitional_Zone_Size 0 "1 nm" 1 "2 nm" 2 "3 nm" 3 "4 nm" 4 "5 nm" 5 "6 nm" ;
VAL_ 2650476288 Message_ID 1 "Scheduled Class A position report" 2 "Assigned scheduled Class A position report" 3 "Interrogated Class A position report" 4 "Base station report" 5 "Static and voyage related data" 6 "Binary addressed message" 7 "Binary acknowledgement" 8 "Binary broadcast message" 9 "Standard SAR aircraft position report" 10 "UTC/date inquiry" 11 "UTC/date response" 12 "Safety related addressed message" 13 "Safety related acknowledgement" 14 "Satety related broadcast message" 15 "Interrogation" 16 "Assignment mode command" 17 "DGNSS broadcast binary message" 18 "Standard Class B position report" 19 "Extended Class B position report" 20 "Data link management message" 21 "ATON report" 22 "Channel management" 23 "Group assignment command" 24 "Static data report" 25 "Single slot binary message" 26 "Multiple slot binary message" 27 "Position report for long range applications" ;
VAL_ 2650476288 Repeat_Indicator 0 "Initial" 1 "First retransmission" 2 "Second retransmission" 3 "Final retransmission" ;
VAL_ 2650476288 Tx_Rx_Mode 0 "Tx A/Tx B, Rx A/Rx B" 1 "Tx A, Rx A/Rx B" 2 "Tx B, Rx A/Rx B" ;
VAL_ 2650476288 Station_Type 0 "All types of mobile station" 2 "All types of Class B mobile station" 3 "SAR airborne mobile station" 4 "AtoN station" 5 "Class B CS shipborne mobile station" 6 "Inland waterways" 7 "Regional use 7" 8 "Regional use 8" 9 "Regional use 9" ;
VAL_ 2650476288 Ship_and_Cargo_Filter 0 "Unavailable" 20 "Wing In Ground" 21 "Wing In Ground (hazard cat X)" 22 "Wing In Ground (hazard cat Y)" 23 "Wing In Ground (hazard cat Z)" 24 "Wing In Ground (hazard cat OS)" 29 "Wing In Ground (no additional information)" 30 "Fishing" 31 "Towing" 32 "Towing exceeds 200m or wider than 25m" 33 "Engaged in dredging or underwater operations" 34 "Engaged in diving operations" 35 "Engaged in military operations" 36 "Sailing" 37 "Pleasure" 40 "High speed craft" 41 "High speed craft (hazard cat X)" 42 "High speed craft (hazard cat Y)" 43 "High speed craft (hazard cat Z)" 44 "High speed craft (hazard cat OS)" 49 "High speed craft (no additional information)" 50 "Pilot vessel" 51 "SAR" 52 "Tug" 53 "Port tender" 54 "Anti-pollution" 55 "Law enforcement" 56 "Spare" 57 "Spare #2" 58 "Medical" 59 "Ships and aircraft of States not parties to an armed conflict" 60 "Passenger ship" 61 "Passenger ship (hazard cat X)" 62 "Passenger ship (hazard cat Y)" 63 "Passenger ship (hazard cat Z)" 64 "Passenger ship (hazard cat OS)" 69 "Passenger ship (no additional information)" 70 "Cargo ship" 71 "Cargo ship (hazard cat X)" 72 "Cargo ship (hazard cat Y)" 73 "Cargo ship (hazard cat Z)" 74 "Cargo ship (hazard cat OS)" 79 "Cargo ship (no additional information)" 80 "Tanker" 81 "Tanker (hazard cat X)" 82 "Tanker (hazard cat Y)" 83 "Tanker (hazard cat Z)" 84 "Tanker (hazard cat OS)" 89 "Tanker (no additional information)" 90 "Other" 91 "Other (hazard cat X)" 92 "Other (hazard cat Y)" 93 "Other (hazard cat Z)" 94 "Other (hazard cat OS)" 99 "Other (no additional information)" ;
VAL_ 2650476288 Reporting_Interval 0 "As given by the autonomous mode" 1 "10 min" 2 "6 min" 3 "3 min" 4 "1 min" 5 "30 sec" 6 "15 sec" 7 "10 sec" 8 "5 sec" 9 "2 sec (not applicable to Class B CS)" 10 "Next shorter reporting interval" 11 "Next longer reporting interval" ;
VAL_ 2449149952 DSC_Format_Symbol 102 "Geographical area" 112 "Distress" 114 "Common interest" 116 "All ships" 120 "Individual stations" 121 "Non-calling purpose" 123 "Individual station automatic" ;
VAL_ 2449149952 DSC_Category_Symbol 100 "Routine" 108 "Safety" 110 "Urgency" 112 "Distress" ;
VAL_ 2449149952 _1st_Telecommand 100 "F3E/G3E All modes TP" 101 "F3E/G3E duplex TP" 103 "Polling" 104 "Unable to comply" 105 "End of call" 106 "Data" 109 "J3E TP" 110 "Distress acknowledgement" 112 "Distress relay" 113 "F1B/J2B TTY-FEC" 115 "F1B/J2B TTY-ARQ" 118 "Test" 121 "Ship position or location registration updating" 126 "No information" ;
VAL_ 2449149952 Subsequent_Communication_Mode_or_2nd_Telecommand 100 "No reason given" 101 "Congestion at MSC" 102 "Busy" 103 "Queue indication" 104 "Station barred" 105 "No operator available" 106 "Operator temporarily unavailable" 107 "Equipment disabled" 108 "Unable to use proposed channel" 109 "Unable to use proposed mode" 110 "Ships and aircraft of States not parties to an armed conflict" 111 "Medical transports" 112 "Pay phone/public call office" 113 "Fax/data" 126 "No information" ;
VAL_ 2449149952 Expansion_Enabled 0 "No" 1 "Yes" ;
VAL_ 2449149952 DSC_Format 102 "Geographical area" 112 "Distress" 114 "Common interest" 116 "All ships" 120 "Individual stations" 121 "Non-calling purpose" 123 "Individual station automatic" ;
VAL_ 2449149952 DSC_Category 100 "Routine" 108 "Safety" 110 "Urgency" 112 "Distress" ;
VAL_ 2449149952 Nature_of_Distress 100 "Fire" 101 "Flooding" 102 "Collision" 103 "Grounding" 104 "Listing" 105 "Sinking" 106 "Disabled and adrift" 107 "Undesignated" 108 "Abandoning ship" 109 "Piracy" 110 "Man overboard" 112 "EPIRB emission" ;
VAL_ 2449149952 Subsequent_Communication_Mode_or_2nd_Telecommand 100 "No reason given" 101 "Congestion at MSC" 102 "Busy" 103 "Queue indication" 104 "Station barred" 105 "No operator available" 106 "Operator temporarily unavailable" 107 "Equipment disabled" 108 "Unable to use proposed channel" 109 "Unable to use proposed mode" 110 "Ships and aircraft of States not parties to an armed conflict" 111 "Medical transports" 112 "Pay phone/public call office" 113 "Fax/data" 126 "No information" ;
VAL_ 2449149952 Expansion_Enabled 0 "No" 1 "Yes" ;
VAL_ 2583367936 Message_ID 1 "Scheduled Class A position report" 2 "Assigned scheduled Class A position report" 3 "Interrogated Class A position report" 4 "Base station report" 5 "Static and voyage related data" 6 "Binary addressed message" 7 "Binary acknowledgement" 8 "Binary broadcast message" 9 "Standard SAR aircraft position report" 10 "UTC/date inquiry" 11 "UTC/date response" 12 "Safety related addressed message" 13 "Safety related acknowledgement" 14 "Satety related broadcast message" 15 "Interrogation" 16 "Assignment mode command" 17 "DGNSS broadcast binary message" 18 "Standard Class B position report" 19 "Extended Class B position report" 20 "Data link management message" 21 "ATON report" 22 "Channel management" 23 "Group assignment command" 24 "Static data report" 25 "Single slot binary message" 26 "Multiple slot binary message" 27 "Position report for long range applications" ;
VAL_ 2583367936 Repeat_Indicator 0 "Initial" 1 "First retransmission" 2 "Second retransmission" 3 "Final retransmission" ;
VAL_ 2583367936 AIS_Transceiver_information 0 "Channel A VDL reception" 1 "Channel B VDL reception" 2 "Channel A VDL transmission" 3 "Channel B VDL transmission" 4 "Own information not broadcast" 5 "Reserved" ;
VAL_ 2583368192 Message_ID 1 "Scheduled Class A position report" 2 "Assigned scheduled Class A position report" 3 "Interrogated Class A position report" 4 "Base station report" 5 "Static and voyage related data" 6 "Binary addressed message" 7 "Binary acknowledgement" 8 "Binary broadcast message" 9 "Standard SAR aircraft position report" 10 "UTC/date inquiry" 11 "UTC/date response" 12 "Safety related addressed message" 13 "Safety related acknowledgement" 14 "Satety related broadcast message" 15 "Interrogation" 16 "Assignment mode command" 17 "DGNSS broadcast binary message" 18 "Standard Class B position report" 19 "Extended Class B position report" 20 "Data link management message" 21 "ATON report" 22 "Channel management" 23 "Group assignment command" 24 "Static data report" 25 "Single slot binary message" 26 "Multiple slot binary message" 27 "Position report for long range applications" ;
VAL_ 2583368192 Repeat_Indicator 0 "Initial" 1 "First retransmission" 2 "Second retransmission" 3 "Final retransmission" ;
VAL_ 2583368192 Type_of_ship 0 "Unavailable" 20 "Wing In Ground" 21 "Wing In Ground (hazard cat X)" 22 "Wing In Ground (hazard cat Y)" 23 "Wing In Ground (hazard cat Z)" 24 "Wing In Ground (hazard cat OS)" 29 "Wing In Ground (no additional information)" 30 "Fishing" 31 "Towing" 32 "Towing exceeds 200m or wider than 25m" 33 "Engaged in dredging or underwater operations" 34 "Engaged in diving operations" 35 "Engaged in military operations" 36 "Sailing" 37 "Pleasure" 40 "High speed craft" 41 "High speed craft (hazard cat X)" 42 "High speed craft (hazard cat Y)" 43 "High speed craft (hazard cat Z)" 44 "High speed craft (hazard cat OS)" 49 "High speed craft (no additional information)" 50 "Pilot vessel" 51 "SAR" 52 "Tug" 53 "Port tender" 54 "Anti-pollution" 55 "Law enforcement" 56 "Spare" 57 "Spare #2" 58 "Medical" 59 "Ships and aircraft of States not parties to an armed conflict" 60 "Passenger ship" 61 "Passenger ship (hazard cat X)" 62 "Passenger ship (hazard cat Y)" 63 "Passenger ship (hazard cat Z)" 64 "Passenger ship (hazard cat OS)" 69 "Passenger ship (no additional information)" 70 "Cargo ship" 71 "Cargo ship (hazard cat X)" 72 "Cargo ship (hazard cat Y)" 73 "Cargo ship (hazard cat Z)" 74 "Cargo ship (hazard cat OS)" 79 "Cargo ship (no additional information)" 80 "Tanker" 81 "Tanker (hazard cat X)" 82 "Tanker (hazard cat Y)" 83 "Tanker (hazard cat Z)" 84 "Tanker (hazard cat OS)" 89 "Tanker (no additional information)" 90 "Other" 91 "Other (hazard cat X)" 92 "Other (hazard cat Y)" 93 "Other (hazard cat Z)" 94 "Other (hazard cat OS)" 99 "Other (no additional information)" ;
VAL_ 2583368192 GNSS_type 0 "Default: undefined" 1 "GPS" 2 "GLONASS" 3 "Combined GPS/GLONASS" 4 "Loran-C" 5 "Chayka" 6 "Integrated navigation system" 7 "Surveyed" 8 "Galileo" ;
VAL_ 2583368192 AIS_Transceiver_information 0 "Channel A VDL reception" 1 "Channel B VDL reception" 2 "Channel A VDL transmission" 3 "Channel B VDL transmission" 4 "Own information not broadcast" 5 "Reserved" ;
VAL_ 2583368448 Message_ID 1 "Scheduled Class A position report" 2 "Assigned scheduled Class A position report" 3 "Interrogated Class A position report" 4 "Base station report" 5 "Static and voyage related data" 6 "Binary addressed message" 7 "Binary acknowledgement" 8 "Binary broadcast message" 9 "Standard SAR aircraft position report" 10 "UTC/date inquiry" 11 "UTC/date response" 12 "Safety related addressed message" 13 "Safety related acknowledgement" 14 "Satety related broadcast message" 15 "Interrogation" 16 "Assignment mode command" 17 "DGNSS broadcast binary message" 18 "Standard Class B position report" 19 "Extended Class B position report" 20 "Data link management message" 21 "ATON report" 22 "Channel management" 23 "Group assignment command" 24 "Static data report" 25 "Single slot binary message" 26 "Multiple slot binary message" 27 "Position report for long range applications" ;
VAL_ 2583368448 Repeat_Indicator 0 "Initial" 1 "First retransmission" 2 "Second retransmission" 3 "Final retransmission" ;
VAL_ 2583368448 Destination_Indicator 0 "Broadcast geo area message" 1 "Addressed message" ;
VAL_ 2583368448 AIS_Transceiver_information 0 "Channel A VDL reception" 1 "Channel B VDL reception" 2 "Channel A VDL transmission" 3 "Channel B VDL transmission" 4 "Own information not broadcast" 5 "Reserved" ;
VAL_ 2583368704 Message_ID 1 "Scheduled Class A position report" 2 "Assigned scheduled Class A position report" 3 "Interrogated Class A position report" 4 "Base station report" 5 "Static and voyage related data" 6 "Binary addressed message" 7 "Binary acknowledgement" 8 "Binary broadcast message" 9 "Standard SAR aircraft position report" 10 "UTC/date inquiry" 11 "UTC/date response" 12 "Safety related addressed message" 13 "Safety related acknowledgement" 14 "Satety related broadcast message" 15 "Interrogation" 16 "Assignment mode command" 17 "DGNSS broadcast binary message" 18 "Standard Class B position report" 19 "Extended Class B position report" 20 "Data link management message" 21 "ATON report" 22 "Channel management" 23 "Group assignment command" 24 "Static data report" 25 "Single slot binary message" 26 "Multiple slot binary message" 27 "Position report for long range applications" ;
VAL_ 2583368704 Repeat_Indicator 0 "Initial" 1 "First retransmission" 2 "Second retransmission" 3 "Final retransmission" ;
VAL_ 2583368704 Destination_Indicator 0 "Broadcast geo area message" 1 "Addressed message" ;
VAL_ 2583368704 AIS_Transceiver_information 0 "Channel A VDL reception" 1 "Channel B VDL reception" 2 "Channel A VDL transmission" 3 "Channel B VDL transmission" 4 "Own information not broadcast" 5 "Reserved" ;
VAL_ 2583368960 Message_ID 1 "Scheduled Class A position report" 2 "Assigned scheduled Class A position report" 3 "Interrogated Class A position report" 4 "Base station report" 5 "Static and voyage related data" 6 "Binary addressed message" 7 "Binary acknowledgement" 8 "Binary broadcast message" 9 "Standard SAR aircraft position report" 10 "UTC/date inquiry" 11 "UTC/date response" 12 "Safety related addressed message" 13 "Safety related acknowledgement" 14 "Satety related broadcast message" 15 "Interrogation" 16 "Assignment mode command" 17 "DGNSS broadcast binary message" 18 "Standard Class B position report" 19 "Extended Class B position report" 20 "Data link management message" 21 "ATON report" 22 "Channel management" 23 "Group assignment command" 24 "Static data report" 25 "Single slot binary message" 26 "Multiple slot binary message" 27 "Position report for long range applications" ;
VAL_ 2583368960 Repeat_Indicator 0 "Initial" 1 "First retransmission" 2 "Second retransmission" 3 "Final retransmission" ;
VAL_ 2583368960 Position_Accuracy 0 "Low" 1 "High" ;
VAL_ 2583368960 RAIM 0 "not in use" 1 "in use" ;
VAL_ 2583368960 Nav_Status 0 "Under way using engine" 1 "At anchor" 2 "Not under command" 3 "Restricted maneuverability" 4 "Constrained by her draught" 5 "Moored" 6 "Aground" 7 "Engaged in Fishing" 8 "Under way sailing" 9 "Hazardous material - High Speed" 10 "Hazardous material - Wing in Ground" 11 "Power-driven vessel towing astern" 12 "Power-driven vessel pushing ahead or towing alongside" 14 "AIS-SART" ;
VAL_ 2583368960 AIS_Transceiver_information 0 "Channel A VDL reception" 1 "Channel B VDL reception" 2 "Channel A VDL transmission" 3 "Channel B VDL transmission" 4 "Own information not broadcast" 5 "Reserved" ;
VAL_ 2583369216 Message_ID 1 "Scheduled Class A position report" 2 "Assigned scheduled Class A position report" 3 "Interrogated Class A position report" 4 "Base station report" 5 "Static and voyage related data" 6 "Binary addressed message" 7 "Binary acknowledgement" 8 "Binary broadcast message" 9 "Standard SAR aircraft position report" 10 "UTC/date inquiry" 11 "UTC/date response" 12 "Safety related addressed message" 13 "Safety related acknowledgement" 14 "Satety related broadcast message" 15 "Interrogation" 16 "Assignment mode command" 17 "DGNSS broadcast binary message" 18 "Standard Class B position report" 19 "Extended Class B position report" 20 "Data link management message" 21 "ATON report" 22 "Channel management" 23 "Group assignment command" 24 "Static data report" 25 "Single slot binary message" 26 "Multiple slot binary message" 27 "Position report for long range applications" ;
VAL_ 2583369216 Repeat_Indicator 0 "Initial" 1 "First retransmission" 2 "Second retransmission" 3 "Final retransmission" ;
VAL_ 2583369216 Destination_Indicator 0 "Broadcast geo area message" 1 "Addressed message" ;
VAL_ 2583369216 AIS_Transceiver_information 0 "Channel A VDL reception" 1 "Channel B VDL reception" 2 "Channel A VDL transmission" 3 "Channel B VDL transmission" 4 "Own information not broadcast" 5 "Reserved" ;
VAL_ 2583369472 Message_ID 1 "Scheduled Class A position report" 2 "Assigned scheduled Class A position report" 3 "Interrogated Class A position report" 4 "Base station report" 5 "Static and voyage related data" 6 "Binary addressed message" 7 "Binary acknowledgement" 8 "Binary broadcast message" 9 "Standard SAR aircraft position report" 10 "UTC/date inquiry" 11 "UTC/date response" 12 "Safety related addressed message" 13 "Safety related acknowledgement" 14 "Satety related broadcast message" 15 "Interrogation" 16 "Assignment mode command" 17 "DGNSS broadcast binary message" 18 "Standard Class B position report" 19 "Extended Class B position report" 20 "Data link management message" 21 "ATON report" 22 "Channel management" 23 "Group assignment command" 24 "Static data report" 25 "Single slot binary message" 26 "Multiple slot binary message" 27 "Position report for long range applications" ;
VAL_ 2583369472 Repeat_Indicator 0 "Initial" 1 "First retransmission" 2 "Second retransmission" 3 "Final retransmission" ;
VAL_ 2583369472 Destination_Indicator 0 "Broadcast geo area message" 1 "Addressed message" ;
VAL_ 2583369472 AIS_Transceiver_information 0 "Channel A VDL reception" 1 "Channel B VDL reception" 2 "Channel A VDL transmission" 3 "Channel B VDL transmission" 4 "Own information not broadcast" 5 "Reserved" ;
VAL_ 2583369728 Message_ID 1 "Scheduled Class A position report" 2 "Assigned scheduled Class A position report" 3 "Interrogated Class A position report" 4 "Base station report" 5 "Static and voyage related data" 6 "Binary addressed message" 7 "Binary acknowledgement" 8 "Binary broadcast message" 9 "Standard SAR aircraft position report" 10 "UTC/date inquiry" 11 "UTC/date response" 12 "Safety related addressed message" 13 "Safety related acknowledgement" 14 "Satety related broadcast message" 15 "Interrogation" 16 "Assignment mode command" 17 "DGNSS broadcast binary message" 18 "Standard Class B position report" 19 "Extended Class B position report" 20 "Data link management message" 21 "ATON report" 22 "Channel management" 23 "Group assignment command" 24 "Static data report" 25 "Single slot binary message" 26 "Multiple slot binary message" 27 "Position report for long range applications" ;
VAL_ 2583369728 Repeat_Indicator 0 "Initial" 1 "First retransmission" 2 "Second retransmission" 3 "Final retransmission" ;
VAL_ 2583369728 AIS_Transceiver_information 0 "Channel A VDL reception" 1 "Channel B VDL reception" 2 "Channel A VDL transmission" 3 "Channel B VDL transmission" 4 "Own information not broadcast" 5 "Reserved" ;
VAL_ 2382103552 Mode 0 "Autonomous" 1 "Differential enhanced" 2 "Estimated" 3 "Simulator" 4 "Manual" ;
VAL_ 2382103808 Mode 0 "Autonomous" 1 "Differential enhanced" 2 "Estimated" 3 "Simulator" 4 "Manual" ;
VAL_ 2650542592 Navigation_Method 0 "Great Circle" 1 "Rhumb Line" ;
VAL_ 2650542592 WP_Identification_Method 0 "Waypoints in WP list" 1 "Waypoints embedded in route" ;
VAL_ 2650542592 Route_Status 0 "Active" 1 "Inactive" 2 "Deleted" ;
VAL_ 2315059712 Reference 0 "True (ground referenced to North)" 1 "Magnetic (ground referenced to Magnetic North)" 2 "Apparent" 3 "True (boat referenced)" 4 "True (water referenced)" ;
VAL_ 2516387584 Temperature_Source 0 "Sea Temperature" 1 "Outside Temperature" 2 "Inside Temperature" 3 "Engine Room Temperature" 4 "Main Cabin Temperature" 5 "Live Well Temperature" 6 "Bait Well Temperature" 7 "Refrigeration Temperature" 8 "Heating System Temperature" 9 "Dew Point Temperature" 10 "Apparent Wind Chill Temperature" 11 "Theoretical Wind Chill Temperature" 12 "Heat Index Temperature" 13 "Freezer Temperature" 14 "Exhaust Gas Temperature" 15 "Shaft Seal Temperature" ;
VAL_ 2516387584 Humidity_Source 0 "Inside" 1 "Outside" ;
VAL_ 2516387840 Source 0 "Sea Temperature" 1 "Outside Temperature" 2 "Inside Temperature" 3 "Engine Room Temperature" 4 "Main Cabin Temperature" 5 "Live Well Temperature" 6 "Bait Well Temperature" 7 "Refrigeration Temperature" 8 "Heating System Temperature" 9 "Dew Point Temperature" 10 "Apparent Wind Chill Temperature" 11 "Theoretical Wind Chill Temperature" 12 "Heat Index Temperature" 13 "Freezer Temperature" 14 "Exhaust Gas Temperature" 15 "Shaft Seal Temperature" ;
VAL_ 2516388096 Source 0 "Inside" 1 "Outside" ;
VAL_ 2516388352 Source 0 "Atmospheric" 1 "Water" 2 "Steam" 3 "Compressed Air" 4 "Hydraulic" 5 "Filter" 6 "AltimeterSetting" 7 "Oil" 8 "Fuel" ;
VAL_ 2516388608 Source 0 "Atmospheric" 1 "Water" 2 "Steam" 3 "Compressed Air" 4 "Hydraulic" 5 "Filter" 6 "AltimeterSetting" 7 "Oil" 8 "Fuel" ;
VAL_ 2516388864 Source 0 "Sea Temperature" 1 "Outside Temperature" 2 "Inside Temperature" 3 "Engine Room Temperature" 4 "Main Cabin Temperature" 5 "Live Well Temperature" 6 "Bait Well Temperature" 7 "Refrigeration Temperature" 8 "Heating System Temperature" 9 "Dew Point Temperature" 10 "Apparent Wind Chill Temperature" 11 "Theoretical Wind Chill Temperature" 12 "Heat Index Temperature" 13 "Freezer Temperature" 14 "Exhaust Gas Temperature" 15 "Shaft Seal Temperature" ;
VAL_ 2583498752 Mode 0 "Autonomous" 1 "Differential enhanced" 2 "Estimated" 3 "Simulator" 4 "Manual" ;
VAL_ 2583498752 Tide_Tendency 0 "Falling" 1 "Rising" ;
VAL_ 2583499008 Mode 0 "Autonomous" 1 "Differential enhanced" 2 "Estimated" 3 "Simulator" 4 "Manual" ;
VAL_ 2583499264 Mode 0 "Autonomous" 1 "Differential enhanced" 2 "Estimated" 3 "Simulator" 4 "Manual" ;
VAL_ 2583499264 State 0 "Flood" 1 "Slack" 2 "Ebb" ;
VAL_ 2583499520 Mode 0 "Autonomous" 1 "Differential enhanced" 2 "Estimated" 3 "Simulator" 4 "Manual" ;
VAL_ 2583499520 Wind_Reference 0 "True (ground referenced to North)" 1 "Magnetic (ground referenced to Magnetic North)" 2 "Apparent" 3 "True (boat referenced)" 4 "True (water referenced)" ;
VAL_ 2583499776 Mode 0 "Autonomous" 1 "Differential enhanced" 2 "Estimated" 3 "Simulator" 4 "Manual" ;
VAL_ 2583499776 Wind_Reference 0 "True (ground referenced to North)" 1 "Magnetic (ground referenced to Magnetic North)" 2 "Apparent" 3 "True (boat referenced)" 4 "True (water referenced)" ;
VAL_ 2583501056 Power 0 "Off" 1 "On" ;
VAL_ 2650610176 Default_Settings_Command 0 "Idle" 1 "Detect Devices" 2 "Reboot" 3 "Factory Reset" 4 "Powering Up" ;
VAL_ 2583560448 Zone_Enabled 0 "Off" 1 "On" ;
VAL_ 2583560960 Enabled 0 "Off" 1 "On" ;
VAL_ 2583561984 Watermaker_Operating_State 0 "Stopped" 1 "Starting" 2 "Running" 3 "Stopping" 4 "Flushing" 5 "Rinsing" 6 "Initiating" 7 "Manual" ;
VAL_ 2583561984 Production_Start_Stop 0 "No" 1 "Yes" ;
VAL_ 2583561984 Rinse_Start_Stop 0 "No" 1 "Yes" ;
VAL_ 2583561984 Low_Pressure_Pump_Status 0 "No" 1 "Yes" ;
VAL_ 2583561984 High_Pressure_Pump_Status 0 "No" 1 "Yes" ;
VAL_ 2583561984 Emergency_Stop 0 "No" 1 "Yes" ;
VAL_ 2583561984 Product_Solenoid_Valve_Status 0 "OK" 1 "Warning" ;
VAL_ 2583561984 Flush_Mode_Status 0 "No" 1 "Yes" ;
VAL_ 2583561984 Salinity_Status 0 "OK" 1 "Warning" ;
VAL_ 2583561984 Sensor_Status 0 "OK" 1 "Warning" ;
VAL_ 2583561984 Oil_Change_Indicator_Status 0 "OK" 1 "Warning" ;
VAL_ 2583561984 Filter_Status 0 "OK" 1 "Warning" ;
VAL_ 2583561984 System_Status 0 "OK" 1 "Warning" ;
VAL_ 2583562240 Source 0 "Vessel alarm" 1 "AM" 2 "FM" 3 "Weather" 4 "DAB" 5 "Aux" 6 "USB" 7 "CD" 8 "MP3" 9 "Apple iOS" 10 "Android" 11 "Bluetooth" 12 "Sirius XM" 13 "Pandora" 14 "Spotify" 15 "Slacker" 16 "Songza" 17 "Apple Radio" 18 "Last FM" 19 "Ethernet" 20 "Video MP4" 21 "Video DVD" 22 "Video BluRay" 23 "HDMI" 24 "Video" ;
VAL_ 2583562496 Zone 0 "All zones" 1 "Zone 1" 2 "Zone 2" 3 "Zone 3" 4 "Zone 4" ;
VAL_ 2583562496 Source 0 "Vessel alarm" 1 "AM" 2 "FM" 3 "Weather" 4 "DAB" 5 "Aux" 6 "USB" 7 "CD" 8 "MP3" 9 "Apple iOS" 10 "Android" 11 "Bluetooth" 12 "Sirius XM" 13 "Pandora" 14 "Spotify" 15 "Slacker" 16 "Songza" 17 "Apple Radio" 18 "Last FM" 19 "Ethernet" 20 "Video MP4" 21 "Video DVD" 22 "Video BluRay" 23 "HDMI" 24 "Video" ;
VAL_ 2583562496 Play_status 0 "Play" 1 "Pause" 2 "Stop" 3 "FF 1x" 4 "FF 2x" 5 "FF 3x" 6 "FF 4x" 7 "RW 1x" 8 "RW 2x" 9 "RW 3x" 10 "RW 4x" 11 "Skip ahead" 12 "Skip back" 13 "Jog ahead" 14 "Jog back" 15 "Seek up" 16 "Seek down" 17 "Scan up" 18 "Scan down" 19 "Tune up" 20 "Tune down" 21 "Slow motion .75x" 22 "Slow motion .5x" 23 "Slow motion .25x" 24 "Slow motion .125x" ;
VAL_ 2583562496 Repeat_Status 0 "Off" 1 "One" 2 "All" ;
VAL_ 2583562496 Shuffle_Status 0 "Off" 1 "Play queue" 2 "All" ;
VAL_ 2583562496 Thumbs_Up_Down 0 "None" 1 "Thumbs up" 2 "Thumbs down" ;
VAL_ 2583562752 Source 0 "Vessel alarm" 1 "AM" 2 "FM" 3 "Weather" 4 "DAB" 5 "Aux" 6 "USB" 7 "CD" 8 "MP3" 9 "Apple iOS" 10 "Android" 11 "Bluetooth" 12 "Sirius XM" 13 "Pandora" 14 "Spotify" 15 "Slacker" 16 "Songza" 17 "Apple Radio" 18 "Last FM" 19 "Ethernet" 20 "Video MP4" 21 "Video DVD" 22 "Video BluRay" 23 "HDMI" 24 "Video" ;
VAL_ 2583562752 Type 0 "File" 1 "Playlist Name" 2 "Genre Name" 3 "Album Name" 4 "Artist Name" 5 "Track Name" 6 "Station Name" 7 "Station Number" 8 "Favourite Number" 9 "Play Queue" 10 "Content Info" ;
VAL_ 2583562752 Zone 0 "All zones" 1 "Zone 1" 2 "Zone 2" 3 "Zone 3" 4 "Zone 4" ;
VAL_ 2583562752 In_play_queue 0 "No" 1 "Yes" ;
VAL_ 2583562752 Locked 0 "No" 1 "Yes" ;
VAL_ 2583563008 Source 0 "Vessel alarm" 1 "AM" 2 "FM" 3 "Weather" 4 "DAB" 5 "Aux" 6 "USB" 7 "CD" 8 "MP3" 9 "Apple iOS" 10 "Android" 11 "Bluetooth" 12 "Sirius XM" 13 "Pandora" 14 "Spotify" 15 "Slacker" 16 "Songza" 17 "Apple Radio" 18 "Last FM" 19 "Ethernet" 20 "Video MP4" 21 "Video DVD" 22 "Video BluRay" 23 "HDMI" 24 "Video" ;
VAL_ 2583563008 Type 0 "File" 1 "Playlist Name" 2 "Genre Name" 3 "Album Name" 4 "Artist Name" 5 "Track Name" 6 "Station Name" 7 "Station Number" 8 "Favourite Number" 9 "Play Queue" 10 "Content Info" ;
VAL_ 2583563008 Zone 0 "All zones" 1 "Zone 1" 2 "Zone 2" 3 "Zone 3" 4 "Zone 4" ;
VAL_ 2583563264 Source 0 "Vessel alarm" 1 "AM" 2 "FM" 3 "Weather" 4 "DAB" 5 "Aux" 6 "USB" 7 "CD" 8 "MP3" 9 "Apple iOS" 10 "Android" 11 "Bluetooth" 12 "Sirius XM" 13 "Pandora" 14 "Spotify" 15 "Slacker" 16 "Songza" 17 "Apple Radio" 18 "Last FM" 19 "Ethernet" 20 "Video MP4" 21 "Video DVD" 22 "Video BluRay" 23 "HDMI" 24 "Video" ;
VAL_ 2583563264 Group_type_1 0 "File" 1 "Playlist Name" 2 "Genre Name" 3 "Album Name" 4 "Artist Name" 5 "Track Name" 6 "Station Name" 7 "Station Number" 8 "Favourite Number" 9 "Play Queue" 10 "Content Info" ;
VAL_ 2583563264 Group_type_2 0 "File" 1 "Playlist Name" 2 "Genre Name" 3 "Album Name" 4 "Artist Name" 5 "Track Name" 6 "Station Name" 7 "Station Number" 8 "Favourite Number" 9 "Play Queue" 10 "Content Info" ;
VAL_ 2583563264 Group_type_3 0 "File" 1 "Playlist Name" 2 "Genre Name" 3 "Album Name" 4 "Artist Name" 5 "Track Name" 6 "Station Name" 7 "Station Number" 8 "Favourite Number" 9 "Play Queue" 10 "Content Info" ;
VAL_ 2583564032 Source 0 "Vessel alarm" 1 "AM" 2 "FM" 3 "Weather" 4 "DAB" 5 "Aux" 6 "USB" 7 "CD" 8 "MP3" 9 "Apple iOS" 10 "Android" 11 "Bluetooth" 12 "Sirius XM" 13 "Pandora" 14 "Spotify" 15 "Slacker" 16 "Songza" 17 "Apple Radio" 18 "Last FM" 19 "Ethernet" 20 "Video MP4" 21 "Video DVD" 22 "Video BluRay" 23 "HDMI" 24 "Video" ;
VAL_ 2382237952 Data_Mode 0 "Autonomous" 1 "Differential enhanced" 2 "Estimated" 3 "Simulator" 4 "Manual" ;
VAL_ 2382237952 COG_Reference 0 "True" 1 "Magnetic" 2 "Error" ;
VAL_ 2583565056 Power 0 "No" 1 "Yes" ;
VAL_ 2583565056 Default_Settings 0 "Save current settings as user default" 1 "Load user default" 2 "Load manufacturer default" ;
VAL_ 2583565056 Tuner_regions 0 "USA" 1 "Europe" 2 "Asia" 3 "Middle East" 4 "Latin America" 5 "Australia" 6 "Russia" 7 "Japan" ;
VAL_ 2583565056 Video_protocols 0 "PAL" 1 "NTSC" ;
VAL_ 2583565312 Power 0 "No" 1 "Yes" ;
VAL_ 2583565312 Default_Settings 0 "Save current settings as user default" 1 "Load user default" 2 "Load manufacturer default" ;
VAL_ 2583565312 Tuner_regions 0 "USA" 1 "Europe" 2 "Asia" 3 "Middle East" 4 "Latin America" 5 "Australia" 6 "Russia" 7 "Japan" ;
VAL_ 2583565824 Zone_ID 0 "All zones" 1 "Zone 1" 2 "Zone 2" 3 "Zone 3" 4 "Zone 4" ;
VAL_ 2583565824 Volume_change 0 "Up" 1 "Down" ;
VAL_ 2583565824 Mute 0 "No" 1 "Yes" ;
VAL_ 2583565824 Channel 0 "All channels" 1 "Stereo full range" 2 "Stereo front" 3 "Stereo back" 4 "Stereo surround" 5 "Center" 6 "Subwoofer" 7 "Front left" 8 "Front right" 9 "Back left" 10 "Back right" 11 "Surround left" 12 "Surround right" ;
VAL_ 2583566592 Status 0 "Reserved" 1 "Connected" 2 "Connecting" 3 "Not connected" ;
VAL_ 2583566592 Forget_device 0 "No" 1 "Yes" ;
VAL_ 2583566592 Discovering 0 "No" 1 "Yes" ;
VAL_ 2583566848 Zone_ID 0 "All zones" 1 "Zone 1" 2 "Zone 2" 3 "Zone 3" 4 "Zone 4" ;
VAL_ 2583566848 Preset_type 0 "Flat" 1 "Rock" 2 "Hall" 3 "Jazz" 4 "Pop" 5 "Live" 6 "Classic" 7 "Vocal" 8 "Arena" 9 "Cinema" 10 "Custom" ;
VAL_ 2583566848 Audio_filter 0 "Full range" 1 "High pass" 2 "Low pass" 3 "Band pass" 4 "Notch filter" ;
VAL_ 2583566848 Channel 0 "All channels" 1 "Stereo full range" 2 "Stereo front" 3 "Stereo back" 4 "Stereo surround" 5 "Center" 6 "Subwoofer" 7 "Front left" 8 "Front right" 9 "Back left" 10 "Back right" 11 "Surround left" 12 "Surround right" ;
VAL_ 2583625728 Manufacturer_Code 69 "ARKS Enterprises" 78 "FW Murphy/Enovation Controls" 80 "Twin Disc" 85 "Kohler Power Systems" 88 "Hemisphere GPS" 135 "Airmar" 137 "Maretron" 140 "Lowrance" 144 "Mercury Marine" 147 "Nautibus Electronic" 148 "Blue Water Data" 154 "Westerbeke" 157 "ISSPRO" 161 "Offshore Systems (UK)" 163 "Evinrude/BRP" 165 "CPAC Systems" 168 "Xantrex Technology" 169 "Marlin Technologies" 172 "Yanmar Marine" 174 "Volvo Penta" 176 "Carling Technologies Inc. (Moritz Aerospace)" 185 "Beede Instruments" 192 "Floscan Instrument" 193 "Nobeltec" 198 "Mystic Valley Communications" 199 "Actia" 201 "Disenos Y Technologia" 211 "Digital Switching Systems" 215 "Xintex/Atena" 224 "EMMI NETWORK" 228 "ZF" 229 "Garmin" 233 "Yacht Monitoring Solutions" 235 "Sailormade Marine Telemetry/Tetra Technology" 243 "Eride" 257 "Honda Motor" 272 "Groco" 273 "Actisense" 274 "Amphenol LTW Technology" 275 "Navico" 283 "Hamilton Jet" 285 "Sea Recovery" 286 "Coelmo SRL Italy" 295 "BEP Marine" 304 "Empir Bus" 305 "NovAtel" 306 "Sleipner Motor" 307 "MBW Technologies" 315 "ICOM" 328 "Qwerty" 329 "Dief" 341 "Boening Automationstechnologie" 345 "Korean Maritime University" 351 "Thrane and Thrane" 355 "Mastervolt" 356 "Fischer Panda Generators" 358 "Victron Energy" 370 "Rolls Royce Marine" 373 "Electronic Design" 374 "Northern Lights" 378 "Glendinning" 381 "B & G" 384 "Rose Point Navigation Systems" 385 "Johnson Outdoors Marine Electronics Inc Geonav" 394 "Capi 2" 396 "Beyond Measure" 400 "Livorsi Marine" 404 "ComNav" 409 "Chetco" 419 "Fusion Electronics" 421 "Standard Horizon" 422 "True Heading" 426 "Egersund Marine Electronics" 427 "em-trak Marine Electronics" 431 "Tohatsu Co, JP" 437 "Digital Yacht" 438 "Comar Systems Limited" 440 "Cummins" 443 "VDO (aka Continental-Corporation)" 451 "Parker Hannifin aka Village Marine Tech" 459 "Alltek Marine Electronics" 460 "SAN GIORGIO S.E.I.N" 466 "Veethree Electronics & Marine" 470 "SI-TEX Marine Electronics" 471 "Sea Cross Marine" 475 "GME aka Standard Communications" 476 "Humminbird Marine Electronics" 478 "Ocean Sat" 481 "Chetco Digital Instruments" 493 "Watcheye" 499 "Lcj Capteurs" 502 "Attwood Marine" 503 "Naviop S.R.L." 504 "Vesper Marine" 510 "Marinesoft" 513 "Simarine" 517 "NoLand Engineering" 518 "Transas USA" 529 "National Instruments Korea" 530 "National Marine Electronics Association" 532 "Onwa Marine" 540 "Webasto" 571 "Marinecraft (South Korea)" 573 "McMurdo Group aka Orolia" 578 "Advansea" 579 "KVH" 580 "San Jose Technology" 583 "Yacht Control" 586 "Suzuki Motor" 591 "US Coast Guard" 595 "Ship Module aka Customware" 600 "Aquatic AV" 605 "Aventics" 606 "Intellian" 612 "SamwonIT" 614 "Arlt Tecnologies" 637 "Bavaria Yachts" 641 "Diverse Yacht Services" 644 "Wema U.S.A dba KUS" 658 "Shenzhen Jiuzhou Himunication" 688 "Rockford" 699 "Harman International" 704 "JL Audio" 708 "Lars Thrane" 715 "Autonnic" 717 "Yacht Devices" 734 "REAP Systems" 735 "AEM Performance Electronics" 739 "LxNav" 741 "Littelfuse, Inc (formerly Carling Technologies)" 743 "DaeMyung" 744 "Woosung" 748 "ISOTTA IFRA srl" 773 "Clarion US" 776 "HMI Systems" 777 "Ocean Signal" 778 "Seakeeper" 781 "Poly Planar" 785 "Fischer Panda DE" 795 "Broyda Industries" 796 "Canadian Automotive" 797 "Tides Marine" 798 "Lumishore" 799 "Still Water Designs and Audio" 802 "BJ Technologies (Beneteau)" 803 "Gill Sensors" 811 "Blue Water Desalination" 815 "FLIR" 824 "Undheim Systems" 826 "Lewmar" 838 "TeamSurv" 844 "Fell Marine" 847 "Oceanvolt" 862 "Prospec" 868 "Data Panel" 890 "L3 Technologies" 894 "Rhodan Marine Systems" 896 "Nexfour Solutions" 905 "ASA Electronics" 909 "Marines Co (South Korea)" 911 "Nautic-on" 917 "Sentinel" 929 "JL Marine Systems" 930 "Ecotronix" 944 "Zontisa Marine" 951 "EXOR International" 962 "Timbolier Industries" 963 "TJC Micro" 968 "Cox Powertrain" 969 "Blue Seas" 981 "Kobelt Manufacturing" 992 "Blue Ocean IOT" 997 "Xenta Systems" 999 "Signal K" 1004 "Ultraflex" 1008 "Lintest SmartBoat" 1011 "Soundmax" 1020 "Team Italia Marine (Onyx Marine Automation s.r.l)" 1021 "Entratech" 1022 "ITC" 1029 "The Marine Guardian" 1047 "Sonic" 1051 "ProNav" 1053 "Vetus Maxwell INC." 1056 "Lithium Pros" 1059 "Boatrax" 1062 "Marol Co ltd" 1065 "CALYPSO Instruments" 1066 "Spot Zero Water" 1069 "Lithionics Battery" 1070 "Quick-teck Electronics" 1075 "Uniden America" 1083 "Nauticoncept" 1084 "Shadow-Caster LED lighting" 1085 "Wet Sounds" 1088 "E-T-A Circuit Breakers" 1092 "Scheiber" 1100 "Smart Yachts International Limited" 1109 "Dockmate" 1114 "Bobs Machine" 1118 "L3Harris ASV" 1119 "Balmar" 1120 "Elettromedia" 1127 "Electromaax" 1140 "Across Oceans Systems" 1145 "Kiwi Yachting" 1150 "BSB Artificial Intelligence" 1151 "Orca Technologies" 1154 "TBS Electronics" 1158 "Technoton Electroics" 1160 "MG Energy Systems" 1169 "Sea Machine Robotics" 1171 "Vista Manufacturing" 1183 "Zipwake" 1186 "Sailmon" 1192 "Airmoniq Pro Kft" 1194 "Sierra Marine" 1200 "Xinuo Information Technology (Xiamen)" 1218 "Septentrio" 1233 "NKE Marine Electronics" 1238 "SuperTrack Aps" 1239 "Honda Electronics" 1245 "Raritan Engineering" 1249 "Integrated Power Solutions AG" 1260 "Interactive Technologies" 1283 "LTG-Tech" 1299 "Energy Solutions (UK)" 1300 "WATT Fuel Cell" 1302 "Pro Mainer" 1305 "Dragonfly Energy" 1306 "Koden Electronics" 1311 "Humphree" 1316 "Hinkley Yachts" 1317 "Global Marine Management GmbH (GMM)" 1320 "Triskel Marine" 1330 "Warwick Control Technologies" 1331 "Dolphin Charger" 1337 "Barnacle Systems" 1348 "Radian IoT" 1353 "Ocean LED Marine" 1359 "BluNav" 1361 "OVA (Nantong Saiyang Electronics Co., Ltd)" 1368 "RAD Propulsion" 1369 "Electric Yacht" 1372 "Elco Motor Yachts" 1384 "Tecnoseal Foundry S.r.l" 1385 "Pro Charging Systems" 1389 "EVEX" 1398 "Gobius Sensor Technology" 1403 "Arco Marine" 1408 "Lenco Marine" 1413 "Naocontrol" 1417 "Revatek" 1438 "Aeolionics" 1439 "PredictWind" 1440 "Egis Mobile Electric" 1445 "Starboard Yacht Group" 1446 "Roswell Marine" 1451 "ePropulsion (Guangdong ePropulsion Technology Ltd.)" 1452 "Micro-Air" 1453 "Vital Battery" 1458 "Ride Controller" 1460 "Tocaro Blue" 1461 "Vanquish Yachts" 1471 "FT Technologies" 1478 "Alps Alpine" 1481 "E-Force Marine" 1482 "CMC Marine" 1483 "Nanjing Sandemarine Information Technology" 1850 "Teleflex Marine (SeaStar Solutions)" 1851 "Raymarine" 1852 "Navionics" 1853 "Japan Radio" 1854 "Northstar Technologies" 1855 "Furuno" 1856 "Trimble" 1857 "Simrad" 1858 "Litton" 1859 "Kvasar" 1860 "MMP" 1861 "Vector Cantech" 1862 "Yamaha Marine" 1863 "Faria Instruments" ;
VAL_ 2583625728 Industry_Code 0 "Global" 1 "Highway" 2 "Agriculture" 3 "Construction" 4 "Marine Industry" 5 "Industrial" ;
VAL_ 2583625728 Manufacturer_Code 69 "ARKS Enterprises" 78 "FW Murphy/Enovation Controls" 80 "Twin Disc" 85 "Kohler Power Systems" 88 "Hemisphere GPS" 135 "Airmar" 137 "Maretron" 140 "Lowrance" 144 "Mercury Marine" 147 "Nautibus Electronic" 148 "Blue Water Data" 154 "Westerbeke" 157 "ISSPRO" 161 "Offshore Systems (UK)" 163 "Evinrude/BRP" 165 "CPAC Systems" 168 "Xantrex Technology" 169 "Marlin Technologies" 172 "Yanmar Marine" 174 "Volvo Penta" 176 "Carling Technologies Inc. (Moritz Aerospace)" 185 "Beede Instruments" 192 "Floscan Instrument" 193 "Nobeltec" 198 "Mystic Valley Communications" 199 "Actia" 201 "Disenos Y Technologia" 211 "Digital Switching Systems" 215 "Xintex/Atena" 224 "EMMI NETWORK" 228 "ZF" 229 "Garmin" 233 "Yacht Monitoring Solutions" 235 "Sailormade Marine Telemetry/Tetra Technology" 243 "Eride" 257 "Honda Motor" 272 "Groco" 273 "Actisense" 274 "Amphenol LTW Technology" 275 "Navico" 283 "Hamilton Jet" 285 "Sea Recovery" 286 "Coelmo SRL Italy" 295 "BEP Marine" 304 "Empir Bus" 305 "NovAtel" 306 "Sleipner Motor" 307 "MBW Technologies" 315 "ICOM" 328 "Qwerty" 329 "Dief" 341 "Boening Automationstechnologie" 345 "Korean Maritime University" 351 "Thrane and Thrane" 355 "Mastervolt" 356 "Fischer Panda Generators" 358 "Victron Energy" 370 "Rolls Royce Marine" 373 "Electronic Design" 374 "Northern Lights" 378 "Glendinning" 381 "B & G" 384 "Rose Point Navigation Systems" 385 "Johnson Outdoors Marine Electronics Inc Geonav" 394 "Capi 2" 396 "Beyond Measure" 400 "Livorsi Marine" 404 "ComNav" 409 "Chetco" 419 "Fusion Electronics" 421 "Standard Horizon" 422 "True Heading" 426 "Egersund Marine Electronics" 427 "em-trak Marine Electronics" 431 "Tohatsu Co, JP" 437 "Digital Yacht" 438 "Comar Systems Limited" 440 "Cummins" 443 "VDO (aka Continental-Corporation)" 451 "Parker Hannifin aka Village Marine Tech" 459 "Alltek Marine Electronics" 460 "SAN GIORGIO S.E.I.N" 466 "Veethree Electronics & Marine" 470 "SI-TEX Marine Electronics" 471 "Sea Cross Marine" 475 "GME aka Standard Communications" 476 "Humminbird Marine Electronics" 478 "Ocean Sat" 481 "Chetco Digital Instruments" 493 "Watcheye" 499 "Lcj Capteurs" 502 "Attwood Marine" 503 "Naviop S.R.L." 504 "Vesper Marine" 510 "Marinesoft" 513 "Simarine" 517 "NoLand Engineering" 518 "Transas USA" 529 "National Instruments Korea" 530 "National Marine Electronics Association" 532 "Onwa Marine" 540 "Webasto" 571 "Marinecraft (South Korea)" 573 "McMurdo Group aka Orolia" 578 "Advansea" 579 "KVH" 580 "San Jose Technology" 583 "Yacht Control" 586 "Suzuki Motor" 591 "US Coast Guard" 595 "Ship Module aka Customware" 600 "Aquatic AV" 605 "Aventics" 606 "Intellian" 612 "SamwonIT" 614 "Arlt Tecnologies" 637 "Bavaria Yachts" 641 "Diverse Yacht Services" 644 "Wema U.S.A dba KUS" 658 "Shenzhen Jiuzhou Himunication" 688 "Rockford" 699 "Harman International" 704 "JL Audio" 708 "Lars Thrane" 715 "Autonnic" 717 "Yacht Devices" 734 "REAP Systems" 735 "AEM Performance Electronics" 739 "LxNav" 741 "Littelfuse, Inc (formerly Carling Technologies)" 743 "DaeMyung" 744 "Woosung" 748 "ISOTTA IFRA srl" 773 "Clarion US" 776 "HMI Systems" 777 "Ocean Signal" 778 "Seakeeper" 781 "Poly Planar" 785 "Fischer Panda DE" 795 "Broyda Industries" 796 "Canadian Automotive" 797 "Tides Marine" 798 "Lumishore" 799 "Still Water Designs and Audio" 802 "BJ Technologies (Beneteau)" 803 "Gill Sensors" 811 "Blue Water Desalination" 815 "FLIR" 824 "Undheim Systems" 826 "Lewmar" 838 "TeamSurv" 844 "Fell Marine" 847 "Oceanvolt" 862 "Prospec" 868 "Data Panel" 890 "L3 Technologies" 894 "Rhodan Marine Systems" 896 "Nexfour Solutions" 905 "ASA Electronics" 909 "Marines Co (South Korea)" 911 "Nautic-on" 917 "Sentinel" 929 "JL Marine Systems" 930 "Ecotronix" 944 "Zontisa Marine" 951 "EXOR International" 962 "Timbolier Industries" 963 "TJC Micro" 968 "Cox Powertrain" 969 "Blue Seas" 981 "Kobelt Manufacturing" 992 "Blue Ocean IOT" 997 "Xenta Systems" 999 "Signal K" 1004 "Ultraflex" 1008 "Lintest SmartBoat" 1011 "Soundmax" 1020 "Team Italia Marine (Onyx Marine Automation s.r.l)" 1021 "Entratech" 1022 "ITC" 1029 "The Marine Guardian" 1047 "Sonic" 1051 "ProNav" 1053 "Vetus Maxwell INC." 1056 "Lithium Pros" 1059 "Boatrax" 1062 "Marol Co ltd" 1065 "CALYPSO Instruments" 1066 "Spot Zero Water" 1069 "Lithionics Battery" 1070 "Quick-teck Electronics" 1075 "Uniden America" 1083 "Nauticoncept" 1084 "Shadow-Caster LED lighting" 1085 "Wet Sounds" 1088 "E-T-A Circuit Breakers" 1092 "Scheiber" 1100 "Smart Yachts International Limited" 1109 "Dockmate" 1114 "Bobs Machine" 1118 "L3Harris ASV" 1119 "Balmar" 1120 "Elettromedia" 1127 "Electromaax" 1140 "Across Oceans Systems" 1145 "Kiwi Yachting" 1150 "BSB Artificial Intelligence" 1151 "Orca Technologies" 1154 "TBS Electronics" 1158 "Technoton Electroics" 1160 "MG Energy Systems" 1169 "Sea Machine Robotics" 1171 "Vista Manufacturing" 1183 "Zipwake" 1186 "Sailmon" 1192 "Airmoniq Pro Kft" 1194 "Sierra Marine" 1200 "Xinuo Information Technology (Xiamen)" 1218 "Septentrio" 1233 "NKE Marine Electronics" 1238 "SuperTrack Aps" 1239 "Honda Electronics" 1245 "Raritan Engineering" 1249 "Integrated Power Solutions AG" 1260 "Interactive Technologies" 1283 "LTG-Tech" 1299 "Energy Solutions (UK)" 1300 "WATT Fuel Cell" 1302 "Pro Mainer" 1305 "Dragonfly Energy" 1306 "Koden Electronics" 1311 "Humphree" 1316 "Hinkley Yachts" 1317 "Global Marine Management GmbH (GMM)" 1320 "Triskel Marine" 1330 "Warwick Control Technologies" 1331 "Dolphin Charger" 1337 "Barnacle Systems" 1348 "Radian IoT" 1353 "Ocean LED Marine" 1359 "BluNav" 1361 "OVA (Nantong Saiyang Electronics Co., Ltd)" 1368 "RAD Propulsion" 1369 "Electric Yacht" 1372 "Elco Motor Yachts" 1384 "Tecnoseal Foundry S.r.l" 1385 "Pro Charging Systems" 1389 "EVEX" 1398 "Gobius Sensor Technology" 1403 "Arco Marine" 1408 "Lenco Marine" 1413 "Naocontrol" 1417 "Revatek" 1438 "Aeolionics" 1439 "PredictWind" 1440 "Egis Mobile Electric" 1445 "Starboard Yacht Group" 1446 "Roswell Marine" 1451 "ePropulsion (Guangdong ePropulsion Technology Ltd.)" 1452 "Micro-Air" 1453 "Vital Battery" 1458 "Ride Controller" 1460 "Tocaro Blue" 1461 "Vanquish Yachts" 1471 "FT Technologies" 1478 "Alps Alpine" 1481 "E-Force Marine" 1482 "CMC Marine" 1483 "Nanjing Sandemarine Information Technology" 1850 "Teleflex Marine (SeaStar Solutions)" 1851 "Raymarine" 1852 "Navionics" 1853 "Japan Radio" 1854 "Northstar Technologies" 1855 "Furuno" 1856 "Trimble" 1857 "Simrad" 1858 "Litton" 1859 "Kvasar" 1860 "MMP" 1861 "Vector Cantech" 1862 "Yamaha Marine" 1863 "Faria Instruments" ;
VAL_ 2583625728 Industry_Code 0 "Global" 1 "Highway" 2 "Agriculture" 3 "Construction" 4 "Marine Industry" 5 "Industrial" ;
VAL_ 2583625728 Manufacturer_Code 69 "ARKS Enterprises" 78 "FW Murphy/Enovation Controls" 80 "Twin Disc" 85 "Kohler Power Systems" 88 "Hemisphere GPS" 135 "Airmar" 137 "Maretron" 140 "Lowrance" 144 "Mercury Marine" 147 "Nautibus Electronic" 148 "Blue Water Data" 154 "Westerbeke" 157 "ISSPRO" 161 "Offshore Systems (UK)" 163 "Evinrude/BRP" 165 "CPAC Systems" 168 "Xantrex Technology" 169 "Marlin Technologies" 172 "Yanmar Marine" 174 "Volvo Penta" 176 "Carling Technologies Inc. (Moritz Aerospace)" 185 "Beede Instruments" 192 "Floscan Instrument" 193 "Nobeltec" 198 "Mystic Valley Communications" 199 "Actia" 201 "Disenos Y Technologia" 211 "Digital Switching Systems" 215 "Xintex/Atena" 224 "EMMI NETWORK" 228 "ZF" 229 "Garmin" 233 "Yacht Monitoring Solutions" 235 "Sailormade Marine Telemetry/Tetra Technology" 243 "Eride" 257 "Honda Motor" 272 "Groco" 273 "Actisense" 274 "Amphenol LTW Technology" 275 "Navico" 283 "Hamilton Jet" 285 "Sea Recovery" 286 "Coelmo SRL Italy" 295 "BEP Marine" 304 "Empir Bus" 305 "NovAtel" 306 "Sleipner Motor" 307 "MBW Technologies" 315 "ICOM" 328 "Qwerty" 329 "Dief" 341 "Boening Automationstechnologie" 345 "Korean Maritime University" 351 "Thrane and Thrane" 355 "Mastervolt" 356 "Fischer Panda Generators" 358 "Victron Energy" 370 "Rolls Royce Marine" 373 "Electronic Design" 374 "Northern Lights" 378 "Glendinning" 381 "B & G" 384 "Rose Point Navigation Systems" 385 "Johnson Outdoors Marine Electronics Inc Geonav" 394 "Capi 2" 396 "Beyond Measure" 400 "Livorsi Marine" 404 "ComNav" 409 "Chetco" 419 "Fusion Electronics" 421 "Standard Horizon" 422 "True Heading" 426 "Egersund Marine Electronics" 427 "em-trak Marine Electronics" 431 "Tohatsu Co, JP" 437 "Digital Yacht" 438 "Comar Systems Limited" 440 "Cummins" 443 "VDO (aka Continental-Corporation)" 451 "Parker Hannifin aka Village Marine Tech" 459 "Alltek Marine Electronics" 460 "SAN GIORGIO S.E.I.N" 466 "Veethree Electronics & Marine" 470 "SI-TEX Marine Electronics" 471 "Sea Cross Marine" 475 "GME aka Standard Communications" 476 "Humminbird Marine Electronics" 478 "Ocean Sat" 481 "Chetco Digital Instruments" 493 "Watcheye" 499 "Lcj Capteurs" 502 "Attwood Marine" 503 "Naviop S.R.L." 504 "Vesper Marine" 510 "Marinesoft" 513 "Simarine" 517 "NoLand Engineering" 518 "Transas USA" 529 "National Instruments Korea" 530 "National Marine Electronics Association" 532 "Onwa Marine" 540 "Webasto" 571 "Marinecraft (South Korea)" 573 "McMurdo Group aka Orolia" 578 "Advansea" 579 "KVH" 580 "San Jose Technology" 583 "Yacht Control" 586 "Suzuki Motor" 591 "US Coast Guard" 595 "Ship Module aka Customware" 600 "Aquatic AV" 605 "Aventics" 606 "Intellian" 612 "SamwonIT" 614 "Arlt Tecnologies" 637 "Bavaria Yachts" 641 "Diverse Yacht Services" 644 "Wema U.S.A dba KUS" 658 "Shenzhen Jiuzhou Himunication" 688 "Rockford" 699 "Harman International" 704 "JL Audio" 708 "Lars Thrane" 715 "Autonnic" 717 "Yacht Devices" 734 "REAP Systems" 735 "AEM Performance Electronics" 739 "LxNav" 741 "Littelfuse, Inc (formerly Carling Technologies)" 743 "DaeMyung" 744 "Woosung" 748 "ISOTTA IFRA srl" 773 "Clarion US" 776 "HMI Systems" 777 "Ocean Signal" 778 "Seakeeper" 781 "Poly Planar" 785 "Fischer Panda DE" 795 "Broyda Industries" 796 "Canadian Automotive" 797 "Tides Marine" 798 "Lumishore" 799 "Still Water Designs and Audio" 802 "BJ Technologies (Beneteau)" 803 "Gill Sensors" 811 "Blue Water Desalination" 815 "FLIR" 824 "Undheim Systems" 826 "Lewmar" 838 "TeamSurv" 844 "Fell Marine" 847 "Oceanvolt" 862 "Prospec" 868 "Data Panel" 890 "L3 Technologies" 894 "Rhodan Marine Systems" 896 "Nexfour Solutions" 905 "ASA Electronics" 909 "Marines Co (South Korea)" 911 "Nautic-on" 917 "Sentinel" 929 "JL Marine Systems" 930 "Ecotronix" 944 "Zontisa Marine" 951 "EXOR International" 962 "Timbolier Industries" 963 "TJC Micro" 968 "Cox Powertrain" 969 "Blue Seas" 981 "Kobelt Manufacturing" 992 "Blue Ocean IOT" 997 "Xenta Systems" 999 "Signal K" 1004 "Ultraflex" 1008 "Lintest SmartBoat" 1011 "Soundmax" 1020 "Team Italia Marine (Onyx Marine Automation s.r.l)" 1021 "Entratech" 1022 "ITC" 1029 "The Marine Guardian" 1047 "Sonic" 1051 "ProNav" 1053 "Vetus Maxwell INC." 1056 "Lithium Pros" 1059 "Boatrax" 1062 "Marol Co ltd" 1065 "CALYPSO Instruments" 1066 "Spot Zero Water" 1069 "Lithionics Battery" 1070 "Quick-teck Electronics" 1075 "Uniden America" 1083 "Nauticoncept" 1084 "Shadow-Caster LED lighting" 1085 "Wet Sounds" 1088 "E-T-A Circuit Breakers" 1092 "Scheiber" 1100 "Smart Yachts International Limited" 1109 "Dockmate" 1114 "Bobs Machine" 1118 "L3Harris ASV" 1119 "Balmar" 1120 "Elettromedia" 1127 "Electromaax" 1140 "Across Oceans Systems" 1145 "Kiwi Yachting" 1150 "BSB Artificial Intelligence" 1151 "Orca Technologies" 1154 "TBS Electronics" 1158 "Technoton Electroics" 1160 "MG Energy Systems" 1169 "Sea Machine Robotics" 1171 "Vista Manufacturing" 1183 "Zipwake" 1186 "Sailmon" 1192 "Airmoniq Pro Kft" 1194 "Sierra Marine" 1200 "Xinuo Information Technology (Xiamen)" 1218 "Septentrio" 1233 "NKE Marine Electronics" 1238 "SuperTrack Aps" 1239 "Honda Electronics" 1245 "Raritan Engineering" 1249 "Integrated Power Solutions AG" 1260 "Interactive Technologies" 1283 "LTG-Tech" 1299 "Energy Solutions (UK)" 1300 "WATT Fuel Cell" 1302 "Pro Mainer" 1305 "Dragonfly Energy" 1306 "Koden Electronics" 1311 "Humphree" 1316 "Hinkley Yachts" 1317 "Global Marine Management GmbH (GMM)" 1320 "Triskel Marine" 1330 "Warwick Control Technologies" 1331 "Dolphin Charger" 1337 "Barnacle Systems" 1348 "Radian IoT" 1353 "Ocean LED Marine" 1359 "BluNav" 1361 "OVA (Nantong Saiyang Electronics Co., Ltd)" 1368 "RAD Propulsion" 1369 "Electric Yacht" 1372 "Elco Motor Yachts" 1384 "Tecnoseal Foundry S.r.l" 1385 "Pro Charging Systems" 1389 "EVEX" 1398 "Gobius Sensor Technology" 1403 "Arco Marine" 1408 "Lenco Marine" 1413 "Naocontrol" 1417 "Revatek" 1438 "Aeolionics" 1439 "PredictWind" 1440 "Egis Mobile Electric" 1445 "Starboard Yacht Group" 1446 "Roswell Marine" 1451 "ePropulsion (Guangdong ePropulsion Technology Ltd.)" 1452 "Micro-Air" 1453 "Vital Battery" 1458 "Ride Controller" 1460 "Tocaro Blue" 1461 "Vanquish Yachts" 1471 "FT Technologies" 1478 "Alps Alpine" 1481 "E-Force Marine" 1482 "CMC Marine" 1483 "Nanjing Sandemarine Information Technology" 1850 "Teleflex Marine (SeaStar Solutions)" 1851 "Raymarine" 1852 "Navionics" 1853 "Japan Radio" 1854 "Northstar Technologies" 1855 "Furuno" 1856 "Trimble" 1857 "Simrad" 1858 "Litton" 1859 "Kvasar" 1860 "MMP" 1861 "Vector Cantech" 1862 "Yamaha Marine" 1863 "Faria Instruments" ;
VAL_ 2583625728 Industry_Code 0 "Global" 1 "Highway" 2 "Agriculture" 3 "Construction" 4 "Marine Industry" 5 "Industrial" ;
VAL_ 2583625728 Manufacturer_Code 69 "ARKS Enterprises" 78 "FW Murphy/Enovation Controls" 80 "Twin Disc" 85 "Kohler Power Systems" 88 "Hemisphere GPS" 135 "Airmar" 137 "Maretron" 140 "Lowrance" 144 "Mercury Marine" 147 "Nautibus Electronic" 148 "Blue Water Data" 154 "Westerbeke" 157 "ISSPRO" 161 "Offshore Systems (UK)" 163 "Evinrude/BRP" 165 "CPAC Systems" 168 "Xantrex Technology" 169 "Marlin Technologies" 172 "Yanmar Marine" 174 "Volvo Penta" 176 "Carling Technologies Inc. (Moritz Aerospace)" 185 "Beede Instruments" 192 "Floscan Instrument" 193 "Nobeltec" 198 "Mystic Valley Communications" 199 "Actia" 201 "Disenos Y Technologia" 211 "Digital Switching Systems" 215 "Xintex/Atena" 224 "EMMI NETWORK" 228 "ZF" 229 "Garmin" 233 "Yacht Monitoring Solutions" 235 "Sailormade Marine Telemetry/Tetra Technology" 243 "Eride" 257 "Honda Motor" 272 "Groco" 273 "Actisense" 274 "Amphenol LTW Technology" 275 "Navico" 283 "Hamilton Jet" 285 "Sea Recovery" 286 "Coelmo SRL Italy" 295 "BEP Marine" 304 "Empir Bus" 305 "NovAtel" 306 "Sleipner Motor" 307 "MBW Technologies" 315 "ICOM" 328 "Qwerty" 329 "Dief" 341 "Boening Automationstechnologie" 345 "Korean Maritime University" 351 "Thrane and Thrane" 355 "Mastervolt" 356 "Fischer Panda Generators" 358 "Victron Energy" 370 "Rolls Royce Marine" 373 "Electronic Design" 374 "Northern Lights" 378 "Glendinning" 381 "B & G" 384 "Rose Point Navigation Systems" 385 "Johnson Outdoors Marine Electronics Inc Geonav" 394 "Capi 2" 396 "Beyond Measure" 400 "Livorsi Marine" 404 "ComNav" 409 "Chetco" 419 "Fusion Electronics" 421 "Standard Horizon" 422 "True Heading" 426 "Egersund Marine Electronics" 427 "em-trak Marine Electronics" 431 "Tohatsu Co, JP" 437 "Digital Yacht" 438 "Comar Systems Limited" 440 "Cummins" 443 "VDO (aka Continental-Corporation)" 451 "Parker Hannifin aka Village Marine Tech" 459 "Alltek Marine Electronics" 460 "SAN GIORGIO S.E.I.N" 466 "Veethree Electronics & Marine" 470 "SI-TEX Marine Electronics" 471 "Sea Cross Marine" 475 "GME aka Standard Communications" 476 "Humminbird Marine Electronics" 478 "Ocean Sat" 481 "Chetco Digital Instruments" 493 "Watcheye" 499 "Lcj Capteurs" 502 "Attwood Marine" 503 "Naviop S.R.L." 504 "Vesper Marine" 510 "Marinesoft" 513 "Simarine" 517 "NoLand Engineering" 518 "Transas USA" 529 "National Instruments Korea" 530 "National Marine Electronics Association" 532 "Onwa Marine" 540 "Webasto" 571 "Marinecraft (South Korea)" 573 "McMurdo Group aka Orolia" 578 "Advansea" 579 "KVH" 580 "San Jose Technology" 583 "Yacht Control" 586 "Suzuki Motor" 591 "US Coast Guard" 595 "Ship Module aka Customware" 600 "Aquatic AV" 605 "Aventics" 606 "Intellian" 612 "SamwonIT" 614 "Arlt Tecnologies" 637 "Bavaria Yachts" 641 "Diverse Yacht Services" 644 "Wema U.S.A dba KUS" 658 "Shenzhen Jiuzhou Himunication" 688 "Rockford" 699 "Harman International" 704 "JL Audio" 708 "Lars Thrane" 715 "Autonnic" 717 "Yacht Devices" 734 "REAP Systems" 735 "AEM Performance Electronics" 739 "LxNav" 741 "Littelfuse, Inc (formerly Carling Technologies)" 743 "DaeMyung" 744 "Woosung" 748 "ISOTTA IFRA srl" 773 "Clarion US" 776 "HMI Systems" 777 "Ocean Signal" 778 "Seakeeper" 781 "Poly Planar" 785 "Fischer Panda DE" 795 "Broyda Industries" 796 "Canadian Automotive" 797 "Tides Marine" 798 "Lumishore" 799 "Still Water Designs and Audio" 802 "BJ Technologies (Beneteau)" 803 "Gill Sensors" 811 "Blue Water Desalination" 815 "FLIR" 824 "Undheim Systems" 826 "Lewmar" 838 "TeamSurv" 844 "Fell Marine" 847 "Oceanvolt" 862 "Prospec" 868 "Data Panel" 890 "L3 Technologies" 894 "Rhodan Marine Systems" 896 "Nexfour Solutions" 905 "ASA Electronics" 909 "Marines Co (South Korea)" 911 "Nautic-on" 917 "Sentinel" 929 "JL Marine Systems" 930 "Ecotronix" 944 "Zontisa Marine" 951 "EXOR International" 962 "Timbolier Industries" 963 "TJC Micro" 968 "Cox Powertrain" 969 "Blue Seas" 981 "Kobelt Manufacturing" 992 "Blue Ocean IOT" 997 "Xenta Systems" 999 "Signal K" 1004 "Ultraflex" 1008 "Lintest SmartBoat" 1011 "Soundmax" 1020 "Team Italia Marine (Onyx Marine Automation s.r.l)" 1021 "Entratech" 1022 "ITC" 1029 "The Marine Guardian" 1047 "Sonic" 1051 "ProNav" 1053 "Vetus Maxwell INC." 1056 "Lithium Pros" 1059 "Boatrax" 1062 "Marol Co ltd" 1065 "CALYPSO Instruments" 1066 "Spot Zero Water" 1069 "Lithionics Battery" 1070 "Quick-teck Electronics" 1075 "Uniden America" 1083 "Nauticoncept" 1084 "Shadow-Caster LED lighting" 1085 "Wet Sounds" 1088 "E-T-A Circuit Breakers" 1092 "Scheiber" 1100 "Smart Yachts International Limited" 1109 "Dockmate" 1114 "Bobs Machine" 1118 "L3Harris ASV" 1119 "Balmar" 1120 "Elettromedia" 1127 "Electromaax" 1140 "Across Oceans Systems" 1145 "Kiwi Yachting" 1150 "BSB Artificial Intelligence" 1151 "Orca Technologies" 1154 "TBS Electronics" 1158 "Technoton Electroics" 1160 "MG Energy Systems" 1169 "Sea Machine Robotics" 1171 "Vista Manufacturing" 1183 "Zipwake" 1186 "Sailmon" 1192 "Airmoniq Pro Kft" 1194 "Sierra Marine" 1200 "Xinuo Information Technology (Xiamen)" 1218 "Septentrio" 1233 "NKE Marine Electronics" 1238 "SuperTrack Aps" 1239 "Honda Electronics" 1245 "Raritan Engineering" 1249 "Integrated Power Solutions AG" 1260 "Interactive Technologies" 1283 "LTG-Tech" 1299 "Energy Solutions (UK)" 1300 "WATT Fuel Cell" 1302 "Pro Mainer" 1305 "Dragonfly Energy" 1306 "Koden Electronics" 1311 "Humphree" 1316 "Hinkley Yachts" 1317 "Global Marine Management GmbH (GMM)" 1320 "Triskel Marine" 1330 "Warwick Control Technologies" 1331 "Dolphin Charger" 1337 "Barnacle Systems" 1348 "Radian IoT" 1353 "Ocean LED Marine" 1359 "BluNav" 1361 "OVA (Nantong Saiyang Electronics Co., Ltd)" 1368 "RAD Propulsion" 1369 "Electric Yacht" 1372 "Elco Motor Yachts" 1384 "Tecnoseal Foundry S.r.l" 1385 "Pro Charging Systems" 1389 "EVEX" 1398 "Gobius Sensor Technology" 1403 "Arco Marine" 1408 "Lenco Marine" 1413 "Naocontrol" 1417 "Revatek" 1438 "Aeolionics" 1439 "PredictWind" 1440 "Egis Mobile Electric" 1445 "Starboard Yacht Group" 1446 "Roswell Marine" 1451 "ePropulsion (Guangdong ePropulsion Technology Ltd.)" 1452 "Micro-Air" 1453 "Vital Battery" 1458 "Ride Controller" 1460 "Tocaro Blue" 1461 "Vanquish Yachts" 1471 "FT Technologies" 1478 "Alps Alpine" 1481 "E-Force Marine" 1482 "CMC Marine" 1483 "Nanjing Sandemarine Information Technology" 1850 "Teleflex Marine (SeaStar Solutions)" 1851 "Raymarine" 1852 "Navionics" 1853 "Japan Radio" 1854 "Northstar Technologies" 1855 "Furuno" 1856 "Trimble" 1857 "Simrad" 1858 "Litton" 1859 "Kvasar" 1860 "MMP" 1861 "Vector Cantech" 1862 "Yamaha Marine" 1863 "Faria Instruments" ;
VAL_ 2583625728 Industry_Code 0 "Global" 1 "Highway" 2 "Agriculture" 3 "Construction" 4 "Marine Industry" 5 "Industrial" ;
CM_ SG_ 2449149952 Proposed_Rx_Frequency_Channel "STRING field: decode bytes as ASCII (0x00/@/0xFF = terminator); canboat type: STRING_FIX";
CM_ SG_ 2449149952 Proposed_Tx_Frequency_Channel "STRING field: decode bytes as ASCII (0x00/@/0xFF = terminator); canboat type: STRING_FIX";
CM_ SG_ 2449149952 Telephone_Number "STRING field: decode bytes as ASCII (0x00/@/0xFF = terminator); canboat type: STRING_LAU";
CM_ SG_ 2449149952 Calling_Rx_Frequency_Channel "STRING field: decode bytes as ASCII (0x00/@/0xFF = terminator); canboat type: STRING_FIX";
CM_ SG_ 2449149952 Calling_Tx_Frequency_Channel "STRING field: decode bytes as ASCII (0x00/@/0xFF = terminator); canboat type: STRING_FIX";
CM_ SG_ 2449149952 Proposed_Rx_Frequency_Channel "STRING field: decode bytes as ASCII (0x00/@/0xFF = terminator); canboat type: STRING_FIX";
CM_ SG_ 2449149952 Proposed_Tx_Frequency_Channel "STRING field: decode bytes as ASCII (0x00/@/0xFF = terminator); canboat type: STRING_FIX";
CM_ SG_ 2449149952 Telephone_Number "STRING field: decode bytes as ASCII (0x00/@/0xFF = terminator); canboat type: STRING_LAU";
CM_ SG_ 2449149952 Calling_Rx_Frequency_Channel "STRING field: decode bytes as ASCII (0x00/@/0xFF = terminator); canboat type: STRING_FIX";
CM_ SG_ 2449149952 Calling_Tx_Frequency_Channel "STRING field: decode bytes as ASCII (0x00/@/0xFF = terminator); canboat type: STRING_FIX";
CM_ SG_ 2583367936 Name "STRING field: decode bytes as ASCII (0x00/@/0xFF = terminator); canboat type: STRING_FIX";
CM_ SG_ 2583368192 Vendor_ID "STRING field: decode bytes as ASCII (0x00/@/0xFF = terminator); canboat type: STRING_FIX";
CM_ SG_ 2583368192 Callsign "STRING field: decode bytes as ASCII (0x00/@/0xFF = terminator); canboat type: STRING_FIX";
CM_ SG_ 2382104064 Station_identifier "STRING field: decode bytes as ASCII (0x00/@/0xFF = terminator); canboat type: STRING_FIX";
CM_ SG_ 2583432192 Label "STRING field: decode bytes as ASCII (0x00/@/0xFF = terminator); canboat type: STRING_LAU";
CM_ SG_ 2650542592 Route_WP_List_Name "STRING field: decode bytes as ASCII (0x00/@/0xFF = terminator); canboat type: STRING_LAU";
CM_ SG_ 2583498752 Station_ID "STRING field: decode bytes as ASCII (0x00/@/0xFF = terminator); canboat type: STRING_LAU";
CM_ SG_ 2583498752 Station_Name "STRING field: decode bytes as ASCII (0x00/@/0xFF = terminator); canboat type: STRING_LAU";
CM_ SG_ 2583499008 Station_ID "STRING field: decode bytes as ASCII (0x00/@/0xFF = terminator); canboat type: STRING_LAU";
CM_ SG_ 2583499008 Station_Name "STRING field: decode bytes as ASCII (0x00/@/0xFF = terminator); canboat type: STRING_LAU";
CM_ SG_ 2583499264 Station_ID "STRING field: decode bytes as ASCII (0x00/@/0xFF = terminator); canboat type: STRING_LAU";
CM_ SG_ 2583499264 Station_Name "STRING field: decode bytes as ASCII (0x00/@/0xFF = terminator); canboat type: STRING_LAU";
CM_ SG_ 2583499520 Station_ID "STRING field: decode bytes as ASCII (0x00/@/0xFF = terminator); canboat type: STRING_LAU";
CM_ SG_ 2583499520 Station_Name "STRING field: decode bytes as ASCII (0x00/@/0xFF = terminator); canboat type: STRING_LAU";
CM_ SG_ 2583499776 Station_ID "STRING field: decode bytes as ASCII (0x00/@/0xFF = terminator); canboat type: STRING_LAU";
CM_ SG_ 2650610176 Name_of_the_lighting_controller "STRING field: decode bytes as ASCII (0x00/@/0xFF = terminator); canboat type: STRING_LAU";
CM_ SG_ 2583560448 Zone_Name "STRING field: decode bytes as ASCII (0x00/@/0xFF = terminator); canboat type: STRING_LAU";
CM_ SG_ 2583560704 Zone_Name "STRING field: decode bytes as ASCII (0x00/@/0xFF = terminator); canboat type: STRING_LAU";
CM_ SG_ 2583560960 Name_of_Lighting_Device "STRING field: decode bytes as ASCII (0x00/@/0xFF = terminator); canboat type: STRING_LAU";
CM_ SG_ 2583561728 Name_of_Program "STRING field: decode bytes as ASCII (0x00/@/0xFF = terminator); canboat type: STRING_LAU";
CM_ SG_ 2583561728 Description "STRING field: decode bytes as ASCII (0x00/@/0xFF = terminator); canboat type: STRING_LAU";
CM_ SG_ 2583562240 Diagnostic_Data "STRING field: decode bytes as ASCII (0x00/@/0xFF = terminator); canboat type: STRING_LAU";
CM_ SG_ 2583562752 Name "STRING field: decode bytes as ASCII (0x00/@/0xFF = terminator); canboat type: STRING_LAU";
CM_ SG_ 2583562752 Artist_Name "STRING field: decode bytes as ASCII (0x00/@/0xFF = terminator); canboat type: STRING_LAU";
CM_ SG_ 2583562752 Album_Name "STRING field: decode bytes as ASCII (0x00/@/0xFF = terminator); canboat type: STRING_LAU";
CM_ SG_ 2583562752 Station_Name "STRING field: decode bytes as ASCII (0x00/@/0xFF = terminator); canboat type: STRING_LAU";
CM_ SG_ 2583563008 Artist "STRING field: decode bytes as ASCII (0x00/@/0xFF = terminator); canboat type: STRING_LAU";
CM_ SG_ 2583563264 Group_name_1 "STRING field: decode bytes as ASCII (0x00/@/0xFF = terminator); canboat type: STRING_LAU";
CM_ SG_ 2583563264 Group_name_2 "STRING field: decode bytes as ASCII (0x00/@/0xFF = terminator); canboat type: STRING_LAU";
CM_ SG_ 2583563264 Group_name_3 "STRING field: decode bytes as ASCII (0x00/@/0xFF = terminator); canboat type: STRING_LAU";
CM_ SG_ 2583564032 Current_Pincode "STRING field: decode bytes as ASCII (0x00/@/0xFF = terminator); canboat type: STRING_LAU";
CM_ SG_ 2583564032 New_Pincode "STRING field: decode bytes as ASCII (0x00/@/0xFF = terminator); canboat type: STRING_LAU";

BA_DEF_ BO_ "GenMsgCycleTime" INT 0 60000;
BA_DEF_ BO_ "ProtocolType" STRING;

BA_DEF_ BO_ "J1939PGN" INT 0 262143;
BA_ "J1939PGN" BO_ 2650475776 129805;
BA_ "J1939PGN" BO_ 2650476032 129806;
BA_ "J1939PGN" BO_ 2650476288 129807;
BA_ "J1939PGN" BO_ 2449149952 129808;
BA_ "J1939PGN" BO_ 2449149952 129808;
BA_ "J1939PGN" BO_ 2583367936 129809;
BA_ "J1939PGN" BO_ 2583368192 129810;
BA_ "J1939PGN" BO_ 2583368448 129811;
BA_ "J1939PGN" BO_ 2583368704 129812;
BA_ "J1939PGN" BO_ 2583368960 129813;
BA_ "J1939PGN" BO_ 2583369216 129814;
BA_ "J1939PGN" BO_ 2583369472 129815;
BA_ "J1939PGN" BO_ 2583369728 129816;
BA_ "J1939PGN" BO_ 2382103552 130052;
BA_ "GenMsgCycleTime" BO_ 2382103552 1000;
BA_ "J1939PGN" BO_ 2382103808 130053;
BA_ "GenMsgCycleTime" BO_ 2382103808 1000;
BA_ "J1939PGN" BO_ 2382104064 130054;
BA_ "GenMsgCycleTime" BO_ 2382104064 1000;
BA_ "J1939PGN" BO_ 2583432192 130060;
BA_ "J1939PGN" BO_ 2583432448 130061;
BA_ "J1939PGN" BO_ 2650542080 130064;
BA_ "J1939PGN" BO_ 2650542336 130065;
BA_ "J1939PGN" BO_ 2650542592 130066;
BA_ "J1939PGN" BO_ 2650542848 130067;
BA_ "J1939PGN" BO_ 2650543104 130068;
BA_ "J1939PGN" BO_ 2650543360 130069;
BA_ "J1939PGN" BO_ 2650543616 130070;
BA_ "J1939PGN" BO_ 2650543872 130071;
BA_ "J1939PGN" BO_ 2650544128 130072;
BA_ "J1939PGN" BO_ 2650544384 130073;
BA_ "J1939PGN" BO_ 2650544640 130074;
BA_ "J1939PGN" BO_ 2315059712 130306;
BA_ "GenMsgCycleTime" BO_ 2315059712 100;
BA_ "J1939PGN" BO_ 2516387328 130310;
BA_ "GenMsgCycleTime" BO_ 2516387328 500;
BA_ "J1939PGN" BO_ 2516387584 130311;
BA_ "GenMsgCycleTime" BO_ 2516387584 500;
BA_ "J1939PGN" BO_ 2516387840 130312;
BA_ "GenMsgCycleTime" BO_ 2516387840 2000;
BA_ "J1939PGN" BO_ 2516388096 130313;
BA_ "GenMsgCycleTime" BO_ 2516388096 2000;
BA_ "J1939PGN" BO_ 2516388352 130314;
BA_ "GenMsgCycleTime" BO_ 2516388352 2000;
BA_ "J1939PGN" BO_ 2516388608 130315;
BA_ "J1939PGN" BO_ 2516388864 130316;
BA_ "GenMsgCycleTime" BO_ 2516388864 2000;
BA_ "J1939PGN" BO_ 2583498752 130320;
BA_ "GenMsgCycleTime" BO_ 2583498752 1000;
BA_ "J1939PGN" BO_ 2583499008 130321;
BA_ "GenMsgCycleTime" BO_ 2583499008 1000;
BA_ "J1939PGN" BO_ 2583499264 130322;
BA_ "GenMsgCycleTime" BO_ 2583499264 1000;
BA_ "J1939PGN" BO_ 2583499520 130323;
BA_ "GenMsgCycleTime" BO_ 2583499520 1000;
BA_ "J1939PGN" BO_ 2583499776 130324;
BA_ "GenMsgCycleTime" BO_ 2583499776 1000;
BA_ "J1939PGN" BO_ 2583501056 130329;
BA_ "GenMsgCycleTime" BO_ 2583501056 5000;
BA_ "J1939PGN" BO_ 2650610176 130330;
BA_ "J1939PGN" BO_ 2583560192 130560;
BA_ "J1939PGN" BO_ 2583560448 130561;
BA_ "J1939PGN" BO_ 2583560704 130562;
BA_ "J1939PGN" BO_ 2583560960 130563;
BA_ "J1939PGN" BO_ 2583561216 130564;
BA_ "J1939PGN" BO_ 2583561472 130565;
BA_ "J1939PGN" BO_ 2583561728 130566;
BA_ "J1939PGN" BO_ 2583561984 130567;
BA_ "J1939PGN" BO_ 2583562240 130568;
BA_ "J1939PGN" BO_ 2583562496 130569;
BA_ "J1939PGN" BO_ 2583562752 130570;
BA_ "J1939PGN" BO_ 2583563008 130571;
BA_ "J1939PGN" BO_ 2583563264 130572;
BA_ "J1939PGN" BO_ 2583563520 130573;
BA_ "J1939PGN" BO_ 2583563776 130574;
BA_ "GenMsgCycleTime" BO_ 2583563776 500;
BA_ "J1939PGN" BO_ 2583564032 130575;
BA_ "J1939PGN" BO_ 2315128832 130576;
BA_ "GenMsgCycleTime" BO_ 2315128832 200;
BA_ "J1939PGN" BO_ 2382237952 130577;
BA_ "GenMsgCycleTime" BO_ 2382237952 1000;
BA_ "J1939PGN" BO_ 2315129344 130578;
BA_ "GenMsgCycleTime" BO_ 2315129344 250;
BA_ "J1939PGN" BO_ 2583565056 130579;
BA_ "J1939PGN" BO_ 2583565312 130580;
BA_ "J1939PGN" BO_ 2583565568 130581;
BA_ "J1939PGN" BO_ 2583565824 130582;
BA_ "J1939PGN" BO_ 2583566080 130583;
BA_ "J1939PGN" BO_ 2583566336 130584;
BA_ "J1939PGN" BO_ 2583566592 130585;
BA_ "J1939PGN" BO_ 2583566848 130586;
BA_ "J1939PGN" BO_ 2583625728 130816;
BA_ "J1939PGN" BO_ 2583625728 130816;
BA_ "J1939PGN" BO_ 2583625728 130816;
BA_ "J1939PGN" BO_ 2583625728 130816;
